VERSION ""

NS_ :

BS_:

BU_:

BO_ 2566590462 NTEES: 34 Vector__XXX
 SG_ NxTStd100HEOtptEB1Tt : 0|16@1+ (1,0) [0|64255] "kWh" Vector__XXX
 SG_ NxTrkngStrd100HrEngnOtptEnrgBn2 : 16|16@1+ (1,0) [0|64255] "kWh" Vector__XXX
 SG_ NxTrkngStrd100HrEngnOtptEnrgBn3 : 32|16@1+ (1,0) [0|64255] "kWh" Vector__XXX
 SG_ NxTrkngStrd100HrEngnOtptEnrgBn4 : 48|16@1+ (1,0) [0|64255] "kWh" Vector__XXX
 SG_ NxTrkngStrd100HrEngnOtptEnrgBn5 : 64|16@1+ (1,0) [0|64255] "kWh" Vector__XXX
 SG_ NxTrkngStrd100HrEngnOtptEnrgBn6 : 80|16@1+ (1,0) [0|64255] "kWh" Vector__XXX
 SG_ NxTrkngStrd100HrEngnOtptEnrgBn7 : 96|16@1+ (1,0) [0|64255] "kWh" Vector__XXX
 SG_ NxTrkngStrd100HrEngnOtptEnrgBn8 : 112|16@1+ (1,0) [0|64255] "kWh" Vector__XXX
 SG_ NxTrkngStrd100HrEngnOtptEnrgBn9 : 128|16@1+ (1,0) [0|64255] "kWh" Vector__XXX
 SG_ NxTStd100HEOtptEB10 : 144|16@1+ (1,0) [0|64255] "kWh" Vector__XXX
 SG_ NxTStd100HEOtptEB11 : 160|16@1+ (1,0) [0|64255] "kWh" Vector__XXX
 SG_ NxTStd100HEOtptEB12 : 176|16@1+ (1,0) [0|64255] "kWh" Vector__XXX
 SG_ NxTStd100HEOtptEB13 : 192|16@1+ (1,0) [0|64255] "kWh" Vector__XXX
 SG_ NxTStd100HEOtptEB14 : 208|16@1+ (1,0) [0|64255] "kWh" Vector__XXX
 SG_ NxTStd100HEOtptEB15NtB : 224|16@1+ (1,0) [0|64255] "kWh" Vector__XXX
 SG_ NxTStd100HEOtptEB16RB : 240|16@1+ (1,0) [0|64255] "kWh" Vector__XXX
 SG_ NxTStd100HEOtptEB17MOB : 256|16@1+ (1,0) [0|64255] "kWh" Vector__XXX

BO_ 2566590718 NTENS: 68 Vector__XXX
 SG_ NxTStd100HEOtNxMssB1Tt : 0|32@1+ (0.0005,0) [0|2105540.6075] "g" Vector__XXX
 SG_ NxTrkngStrd100HrEngnOtNxMssBn2 : 32|32@1+ (0.0005,0) [0|2105540.6075] "g" Vector__XXX
 SG_ NxTrkngStrd100HrEngnOtNxMssBn3 : 64|32@1+ (0.0005,0) [0|2105540.6075] "g" Vector__XXX
 SG_ NxTrkngStrd100HrEngnOtNxMssBn4 : 96|32@1+ (0.0005,0) [0|2105540.6075] "g" Vector__XXX
 SG_ NxTrkngStrd100HrEngnOtNxMssBn5 : 128|32@1+ (0.0005,0) [0|2105540.6075] "g" Vector__XXX
 SG_ NxTrkngStrd100HrEngnOtNxMssBn6 : 160|32@1+ (0.0005,0) [0|2105540.6075] "g" Vector__XXX
 SG_ NxTrkngStrd100HrEngnOtNxMssBn7 : 192|32@1+ (0.0005,0) [0|2105540.6075] "g" Vector__XXX
 SG_ NxTrkngStrd100HrEngnOtNxMssBn8 : 224|32@1+ (0.0005,0) [0|2105540.6075] "g" Vector__XXX
 SG_ NxTrkngStrd100HrEngnOtNxMssBn9 : 256|32@1+ (0.0005,0) [0|2105540.6075] "g" Vector__XXX
 SG_ NxTrkngStrd100HrEngnOtNxMssBn10 : 288|32@1+ (0.0005,0) [0|2105540.6075] "g" Vector__XXX
 SG_ NxTrkngStrd100HrEngnOtNxMssBn11 : 320|32@1+ (0.0005,0) [0|2105540.6075] "g" Vector__XXX
 SG_ NxTrkngStrd100HrEngnOtNxMssBn12 : 352|32@1+ (0.0005,0) [0|2105540.6075] "g" Vector__XXX
 SG_ NxTrkngStrd100HrEngnOtNxMssBn13 : 384|32@1+ (0.0005,0) [0|2105540.6075] "g" Vector__XXX
 SG_ NxTrkngStrd100HrEngnOtNxMssBn14 : 416|32@1+ (0.0005,0) [0|2105540.6075] "g" Vector__XXX
 SG_ NxTStd100HEOtNxMssB15NtB : 448|32@1+ (0.0005,0) [0|2105540.6075] "g" Vector__XXX
 SG_ NxTStd100HEOtNxMssB16RB : 480|32@1+ (0.0005,0) [0|2105540.6075] "g" Vector__XXX
 SG_ NxTStd100HEOtNxMssB17MOB : 512|32@1+ (0.0005,0) [0|2105540.6075] "g" Vector__XXX

BO_ 2566590974 NTSNS: 68 Vector__XXX
 SG_ NxTStd100HSstOtNxMssB1Tt : 0|32@1+ (0.0002,0) [0|842216.243] "g" Vector__XXX
 SG_ NxTrkngStrd100HrSstmOtNxMssBn2 : 32|32@1+ (0.0002,0) [0|842216.243] "g" Vector__XXX
 SG_ NxTrkngStrd100HrSstmOtNxMssBn3 : 64|32@1+ (0.0002,0) [0|842216.243] "g" Vector__XXX
 SG_ NxTrkngStrd100HrSstmOtNxMssBn4 : 96|32@1+ (0.0002,0) [0|842216.243] "g" Vector__XXX
 SG_ NxTrkngStrd100HrSstmOtNxMssBn5 : 128|32@1+ (0.0002,0) [0|842216.243] "g" Vector__XXX
 SG_ NxTrkngStrd100HrSstmOtNxMssBn6 : 160|32@1+ (0.0002,0) [0|842216.243] "g" Vector__XXX
 SG_ NxTrkngStrd100HrSstmOtNxMssBn7 : 192|32@1+ (0.0002,0) [0|842216.243] "g" Vector__XXX
 SG_ NxTrkngStrd100HrSstmOtNxMssBn8 : 224|32@1+ (0.0002,0) [0|842216.243] "g" Vector__XXX
 SG_ NxTrkngStrd100HrSstmOtNxMssBn9 : 256|32@1+ (0.0002,0) [0|842216.243] "g" Vector__XXX
 SG_ NxTrkngStrd100HrSstmOtNxMssBn10 : 288|32@1+ (0.0002,0) [0|842216.243] "g" Vector__XXX
 SG_ NxTrkngStrd100HrSstmOtNxMssBn11 : 320|32@1+ (0.0002,0) [0|842216.243] "g" Vector__XXX
 SG_ NxTrkngStrd100HrSstmOtNxMssBn12 : 352|32@1+ (0.0002,0) [0|842216.243] "g" Vector__XXX
 SG_ NxTrkngStrd100HrSstmOtNxMssBn13 : 384|32@1+ (0.0002,0) [0|842216.243] "g" Vector__XXX
 SG_ NxTrkngStrd100HrSstmOtNxMssBn14 : 416|32@1+ (0.0002,0) [0|842216.243] "g" Vector__XXX
 SG_ NxTStd100HSstOtNxMssB15NtB : 448|32@1+ (0.0002,0) [0|842216.243] "g" Vector__XXX
 SG_ NxTStd100HSstOtNxMssB16RB : 480|32@1+ (0.0002,0) [0|842216.243] "g" Vector__XXX
 SG_ NxTStd100HSstOtNxMssB17MOB : 512|32@1+ (0.0002,0) [0|842216.243] "g" Vector__XXX

BO_ 2566591230 NTFCA: 34 Vector__XXX
 SG_ NxTrkngAtv100HrFlCnsmptnBn1Ttl : 0|16@1+ (0.5,0) [0|32127.5] "l" Vector__XXX
 SG_ NxTrkngAtv100HrFlCnsmptnBn2 : 16|16@1+ (0.5,0) [0|32127.5] "l" Vector__XXX
 SG_ NxTrkngAtv100HrFlCnsmptnBn3 : 32|16@1+ (0.5,0) [0|32127.5] "l" Vector__XXX
 SG_ NxTrkngAtv100HrFlCnsmptnBn4 : 48|16@1+ (0.5,0) [0|32127.5] "l" Vector__XXX
 SG_ NxTrkngAtv100HrFlCnsmptnBn5 : 64|16@1+ (0.5,0) [0|32127.5] "l" Vector__XXX
 SG_ NxTrkngAtv100HrFlCnsmptnBn6 : 80|16@1+ (0.5,0) [0|32127.5] "l" Vector__XXX
 SG_ NxTrkngAtv100HrFlCnsmptnBn7 : 96|16@1+ (0.5,0) [0|32127.5] "l" Vector__XXX
 SG_ NxTrkngAtv100HrFlCnsmptnBn8 : 112|16@1+ (0.5,0) [0|32127.5] "l" Vector__XXX
 SG_ NxTrkngAtv100HrFlCnsmptnBn9 : 128|16@1+ (0.5,0) [0|32127.5] "l" Vector__XXX
 SG_ NxTrkngAtv100HrFlCnsmptnBn10 : 144|16@1+ (0.5,0) [0|32127.5] "l" Vector__XXX
 SG_ NxTrkngAtv100HrFlCnsmptnBn11 : 160|16@1+ (0.5,0) [0|32127.5] "l" Vector__XXX
 SG_ NxTrkngAtv100HrFlCnsmptnBn12 : 176|16@1+ (0.5,0) [0|32127.5] "l" Vector__XXX
 SG_ NxTrkngAtv100HrFlCnsmptnBn13 : 192|16@1+ (0.5,0) [0|32127.5] "l" Vector__XXX
 SG_ NxTrkngAtv100HrFlCnsmptnBn14 : 208|16@1+ (0.5,0) [0|32127.5] "l" Vector__XXX
 SG_ NxTAtv100HFCsptB15NtB : 224|16@1+ (0.5,0) [0|32127.5] "l" Vector__XXX
 SG_ NxTAtv100HFCsptB16RB : 240|16@1+ (0.5,0) [0|32127.5] "l" Vector__XXX
 SG_ NxTAtv100HFCsptB17MOB : 256|16@1+ (0.5,0) [0|32127.5] "l" Vector__XXX

BO_ 2566591486 NTEHA: 34 Vector__XXX
 SG_ NxTrkngAtv100HrEngnRnTmBn1Ttl : 0|16@1+ (10,0) [0|642550] "s" Vector__XXX
 SG_ NxTrkngAtv100HrEngnRnTmBn2 : 16|16@1+ (10,0) [0|642550] "s" Vector__XXX
 SG_ NxTrkngAtv100HrEngnRnTmBn3 : 32|16@1+ (10,0) [0|642550] "s" Vector__XXX
 SG_ NxTrkngAtv100HrEngnRnTmBn4 : 48|16@1+ (10,0) [0|642550] "s" Vector__XXX
 SG_ NxTrkngAtv100HrEngnRnTmBn5 : 64|16@1+ (10,0) [0|642550] "s" Vector__XXX
 SG_ NxTrkngAtv100HrEngnRnTmBn6 : 80|16@1+ (10,0) [0|642550] "s" Vector__XXX
 SG_ NxTrkngAtv100HrEngnRnTmBn7 : 96|16@1+ (10,0) [0|642550] "s" Vector__XXX
 SG_ NxTrkngAtv100HrEngnRnTmBn8 : 112|16@1+ (10,0) [0|642550] "s" Vector__XXX
 SG_ NxTrkngAtv100HrEngnRnTmBn9 : 128|16@1+ (10,0) [0|642550] "s" Vector__XXX
 SG_ NxTrkngAtv100HrEngnRnTmBn10 : 144|16@1+ (10,0) [0|642550] "s" Vector__XXX
 SG_ NxTrkngAtv100HrEngnRnTmBn11 : 160|16@1+ (10,0) [0|642550] "s" Vector__XXX
 SG_ NxTrkngAtv100HrEngnRnTmBn12 : 176|16@1+ (10,0) [0|642550] "s" Vector__XXX
 SG_ NxTrkngAtv100HrEngnRnTmBn13 : 192|16@1+ (10,0) [0|642550] "s" Vector__XXX
 SG_ NxTrkngAtv100HrEngnRnTmBn14 : 208|16@1+ (10,0) [0|642550] "s" Vector__XXX
 SG_ NxTrkngAtv100HrEngnRnTmBn15NtBn : 224|16@1+ (10,0) [0|642550] "s" Vector__XXX
 SG_ NxTAtv100HERTB16RB : 240|16@1+ (10,0) [0|642550] "s" Vector__XXX
 SG_ NxTAtv100HERTB17MOB : 256|16@1+ (10,0) [0|642550] "s" Vector__XXX

BO_ 2566591742 NTVMA: 34 Vector__XXX
 SG_ NxTrkngAtv100HrVhlDstnBn1Ttl : 0|16@1+ (0.25,0) [0|16063.75] "km" Vector__XXX
 SG_ NxTrkngAtv100HrVhlDstnBn2 : 16|16@1+ (0.25,0) [0|16063.75] "km" Vector__XXX
 SG_ NxTrkngAtv100HrVhlDstnBn3 : 32|16@1+ (0.25,0) [0|16063.75] "km" Vector__XXX
 SG_ NxTrkngAtv100HrVhlDstnBn4 : 48|16@1+ (0.25,0) [0|16063.75] "km" Vector__XXX
 SG_ NxTrkngAtv100HrVhlDstnBn5 : 64|16@1+ (0.25,0) [0|16063.75] "km" Vector__XXX
 SG_ NxTrkngAtv100HrVhlDstnBn6 : 80|16@1+ (0.25,0) [0|16063.75] "km" Vector__XXX
 SG_ NxTrkngAtv100HrVhlDstnBn7 : 96|16@1+ (0.25,0) [0|16063.75] "km" Vector__XXX
 SG_ NxTrkngAtv100HrVhlDstnBn8 : 112|16@1+ (0.25,0) [0|16063.75] "km" Vector__XXX
 SG_ NxTrkngAtv100HrVhlDstnBn9 : 128|16@1+ (0.25,0) [0|16063.75] "km" Vector__XXX
 SG_ NxTrkngAtv100HrVhlDstnBn10 : 144|16@1+ (0.25,0) [0|16063.75] "km" Vector__XXX
 SG_ NxTrkngAtv100HrVhlDstnBn11 : 160|16@1+ (0.25,0) [0|16063.75] "km" Vector__XXX
 SG_ NxTrkngAtv100HrVhlDstnBn12 : 176|16@1+ (0.25,0) [0|16063.75] "km" Vector__XXX
 SG_ NxTrkngAtv100HrVhlDstnBn13 : 192|16@1+ (0.25,0) [0|16063.75] "km" Vector__XXX
 SG_ NxTrkngAtv100HrVhlDstnBn14 : 208|16@1+ (0.25,0) [0|16063.75] "km" Vector__XXX
 SG_ NxTrkngAtv100HrVhlDstnBn15NtBn : 224|16@1+ (0.25,0) [0|16063.75] "km" Vector__XXX
 SG_ NxTrkngAtv100HrVhlDstnBn16RgnBn : 240|16@1+ (0.25,0) [0|16063.75] "km" Vector__XXX
 SG_ NxTAtv100HVDstB17MOB : 256|16@1+ (0.25,0) [0|16063.75] "km" Vector__XXX

BO_ 2566591998 NTEEA: 34 Vector__XXX
 SG_ NxTAtv100HEOtptEB1Tt : 0|16@1+ (1,0) [0|64255] "kWh" Vector__XXX
 SG_ NxTrkngAtv100HrEngnOtptEnrgBn2 : 16|16@1+ (1,0) [0|64255] "kWh" Vector__XXX
 SG_ NxTrkngAtv100HrEngnOtptEnrgBn3 : 32|16@1+ (1,0) [0|64255] "kWh" Vector__XXX
 SG_ NxTrkngAtv100HrEngnOtptEnrgBn4 : 48|16@1+ (1,0) [0|64255] "kWh" Vector__XXX
 SG_ NxTrkngAtv100HrEngnOtptEnrgBn5 : 64|16@1+ (1,0) [0|64255] "kWh" Vector__XXX
 SG_ NxTrkngAtv100HrEngnOtptEnrgBn6 : 80|16@1+ (1,0) [0|64255] "kWh" Vector__XXX
 SG_ NxTrkngAtv100HrEngnOtptEnrgBn7 : 96|16@1+ (1,0) [0|64255] "kWh" Vector__XXX
 SG_ NxTrkngAtv100HrEngnOtptEnrgBn8 : 112|16@1+ (1,0) [0|64255] "kWh" Vector__XXX
 SG_ NxTrkngAtv100HrEngnOtptEnrgBn9 : 128|16@1+ (1,0) [0|64255] "kWh" Vector__XXX
 SG_ NxTrkngAtv100HrEngnOtptEnrgBn10 : 144|16@1+ (1,0) [0|64255] "kWh" Vector__XXX
 SG_ NxTrkngAtv100HrEngnOtptEnrgBn11 : 160|16@1+ (1,0) [0|64255] "kWh" Vector__XXX
 SG_ NxTrkngAtv100HrEngnOtptEnrgBn12 : 176|16@1+ (1,0) [0|64255] "kWh" Vector__XXX
 SG_ NxTrkngAtv100HrEngnOtptEnrgBn13 : 192|16@1+ (1,0) [0|64255] "kWh" Vector__XXX
 SG_ NxTrkngAtv100HrEngnOtptEnrgBn14 : 208|16@1+ (1,0) [0|64255] "kWh" Vector__XXX
 SG_ NxTAtv100HEOtptEB15NtB : 224|16@1+ (1,0) [0|64255] "kWh" Vector__XXX
 SG_ NxTAtv100HEOtptEB16RB : 240|16@1+ (1,0) [0|64255] "kWh" Vector__XXX
 SG_ NxTAtv100HEOtptEB17MOB : 256|16@1+ (1,0) [0|64255] "kWh" Vector__XXX

BO_ 2566592254 NTENA: 68 Vector__XXX
 SG_ NxTAtv100HEOtNxMssB1Tt : 0|32@1+ (0.0005,0) [0|2105540.6075] "g" Vector__XXX
 SG_ NxTrkngAtv100HrEngnOtNxMssBn2 : 32|32@1+ (0.0005,0) [0|2105540.6075] "g" Vector__XXX
 SG_ NxTrkngAtv100HrEngnOtNxMssBn3 : 64|32@1+ (0.0005,0) [0|2105540.6075] "g" Vector__XXX
 SG_ NxTrkngAtv100HrEngnOtNxMssBn4 : 96|32@1+ (0.0005,0) [0|2105540.6075] "g" Vector__XXX
 SG_ NxTrkngAtv100HrEngnOtNxMssBn5 : 128|32@1+ (0.0005,0) [0|2105540.6075] "g" Vector__XXX
 SG_ NxTrkngAtv100HrEngnOtNxMssBn6 : 160|32@1+ (0.0005,0) [0|2105540.6075] "g" Vector__XXX
 SG_ NxTrkngAtv100HrEngnOtNxMssBn7 : 192|32@1+ (0.0005,0) [0|2105540.6075] "g" Vector__XXX
 SG_ NxTrkngAtv100HrEngnOtNxMssBn8 : 224|32@1+ (0.0005,0) [0|2105540.6075] "g" Vector__XXX
 SG_ NxTrkngAtv100HrEngnOtNxMssBn9 : 256|32@1+ (0.0005,0) [0|2105540.6075] "g" Vector__XXX
 SG_ NxTrkngAtv100HrEngnOtNxMssBn10 : 288|32@1+ (0.0005,0) [0|2105540.6075] "g" Vector__XXX
 SG_ NxTrkngAtv100HrEngnOtNxMssBn11 : 320|32@1+ (0.0005,0) [0|2105540.6075] "g" Vector__XXX
 SG_ NxTrkngAtv100HrEngnOtNxMssBn12 : 352|32@1+ (0.0005,0) [0|2105540.6075] "g" Vector__XXX
 SG_ NxTrkngAtv100HrEngnOtNxMssBn13 : 384|32@1+ (0.0005,0) [0|2105540.6075] "g" Vector__XXX
 SG_ NxTrkngAtv100HrEngnOtNxMssBn14 : 416|32@1+ (0.0005,0) [0|2105540.6075] "g" Vector__XXX
 SG_ NxTAtv100HEOtNxMssB15NtB : 448|32@1+ (0.0005,0) [0|2105540.6075] "g" Vector__XXX
 SG_ NxTAtv100HEOtNxMssB16RB : 480|32@1+ (0.0005,0) [0|2105540.6075] "g" Vector__XXX
 SG_ NxTAtv100HEOtNxMssB17MOB : 512|32@1+ (0.0005,0) [0|2105540.6075] "g" Vector__XXX

BO_ 2566592510 NTSNA: 68 Vector__XXX
 SG_ NxTAtv100HSstOtNxMssB1Tt : 0|32@1+ (0.0002,0) [0|842216.243] "g" Vector__XXX
 SG_ NxTrkngAtv100HrSstmOtNxMssBn2 : 32|32@1+ (0.0002,0) [0|842216.243] "g" Vector__XXX
 SG_ NxTrkngAtv100HrSstmOtNxMssBn3 : 64|32@1+ (0.0002,0) [0|842216.243] "g" Vector__XXX
 SG_ NxTrkngAtv100HrSstmOtNxMssBn4 : 96|32@1+ (0.0002,0) [0|842216.243] "g" Vector__XXX
 SG_ NxTrkngAtv100HrSstmOtNxMssBn5 : 128|32@1+ (0.0002,0) [0|842216.243] "g" Vector__XXX
 SG_ NxTrkngAtv100HrSstmOtNxMssBn6 : 160|32@1+ (0.0002,0) [0|842216.243] "g" Vector__XXX
 SG_ NxTrkngAtv100HrSstmOtNxMssBn7 : 192|32@1+ (0.0002,0) [0|842216.243] "g" Vector__XXX
 SG_ NxTrkngAtv100HrSstmOtNxMssBn8 : 224|32@1+ (0.0002,0) [0|842216.243] "g" Vector__XXX
 SG_ NxTrkngAtv100HrSstmOtNxMssBn9 : 256|32@1+ (0.0002,0) [0|842216.243] "g" Vector__XXX
 SG_ NxTrkngAtv100HrSstmOtNxMssBn10 : 288|32@1+ (0.0002,0) [0|842216.243] "g" Vector__XXX
 SG_ NxTrkngAtv100HrSstmOtNxMssBn11 : 320|32@1+ (0.0002,0) [0|842216.243] "g" Vector__XXX
 SG_ NxTrkngAtv100HrSstmOtNxMssBn12 : 352|32@1+ (0.0002,0) [0|842216.243] "g" Vector__XXX
 SG_ NxTrkngAtv100HrSstmOtNxMssBn13 : 384|32@1+ (0.0002,0) [0|842216.243] "g" Vector__XXX
 SG_ NxTrkngAtv100HrSstmOtNxMssBn14 : 416|32@1+ (0.0002,0) [0|842216.243] "g" Vector__XXX
 SG_ NxTAtv100HSstOtNxMssB15NtB : 448|32@1+ (0.0002,0) [0|842216.243] "g" Vector__XXX
 SG_ NxTAtv100HSstOtNxMssB16RB : 480|32@1+ (0.0002,0) [0|842216.243] "g" Vector__XXX
 SG_ NxTAtv100HSstOtNxMssB17MOB : 512|32@1+ (0.0002,0) [0|842216.243] "g" Vector__XXX

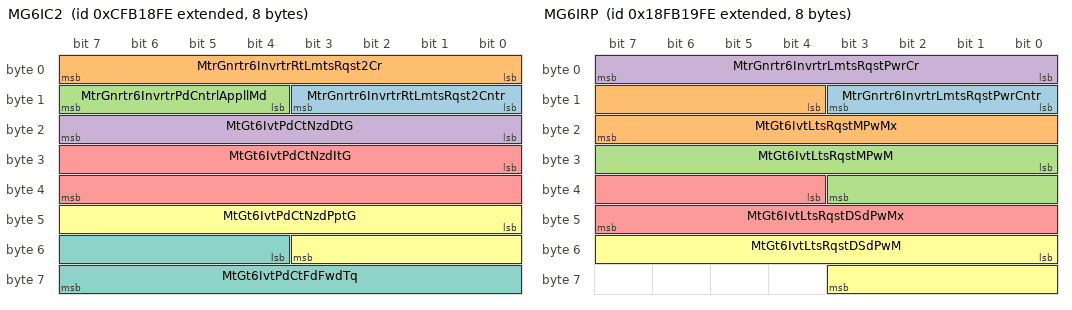
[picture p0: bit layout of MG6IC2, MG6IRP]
BO_ 2365266174 MG6IC2: 8 Vector__XXX
 SG_ MtrGnrtr6InvrtrRtLmtsRqst2Cntr : 8|4@1+ (1,0) [0|15] "" Vector__XXX
 SG_ MtrGnrtr6InvrtrRtLmtsRqst2Cr : 0|8@1+ (1,0) [0|250] "count" Vector__XXX
 SG_ MtrGnrtr6InvrtrPdCntrlAppllMd : 12|4@1+ (1,0) [0|15] "" Vector__XXX
 SG_ MtGt6IvtPdCtNzdDtG : 16|8@1+ (0.03125,0) [0|7.8125] "%/(%/s)" Vector__XXX
 SG_ MtGt6IvtPdCtNzdItG : 24|16@1+ (0.015625,0) [0|1003.984375] "%/(%/s)" Vector__XXX
 SG_ MtGt6IvtPdCtNzdPptG : 40|12@1+ (0.0625,0) [0|250.9375] "%/%" Vector__XXX
 SG_ MtGt6IvtPdCtFdFwdTq : 52|12@1+ (0.0625,-125) [-125|125.9375] "%" Vector__XXX

BO_ 2566593022 MG6IRP: 8 Vector__XXX
 SG_ MtrGnrtr6InvrtrLmtsRqstPwrCntr : 8|4@1+ (1,0) [0|15] "" Vector__XXX
 SG_ MtGt6IvtLtsRqstMPwMx : 12|12@1+ (0.0625,-125) [-125|125.9375] "%" Vector__XXX
 SG_ MtGt6IvtLtsRqstMPwM : 24|12@1+ (0.0625,-125) [-125|125.9375] "%" Vector__XXX
 SG_ MtrGnrtr6InvrtrLmtsRqstPwrCr : 0|8@1+ (1,0) [0|250] "count" Vector__XXX
 SG_ MtGt6IvtLtsRqstDSdPwMx : 36|12@1+ (0.0625,-125) [-125|125.9375] "%" Vector__XXX
 SG_ MtGt6IvtLtsRqstDSdPwM : 48|12@1+ (0.0625,-125) [-125|125.9375] "%" Vector__XXX

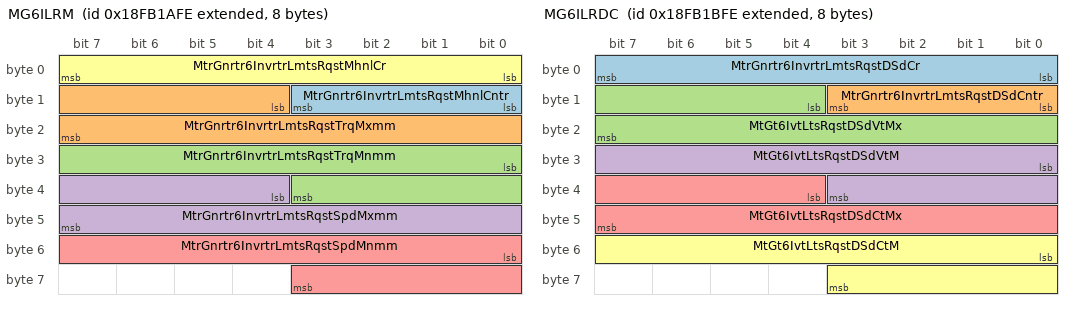
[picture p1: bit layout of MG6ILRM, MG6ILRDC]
BO_ 2566593278 MG6ILRM: 8 Vector__XXX
 SG_ MtrGnrtr6InvrtrLmtsRqstMhnlCntr : 8|4@1+ (1,0) [0|15] "" Vector__XXX
 SG_ MtrGnrtr6InvrtrLmtsRqstTrqMxmm : 12|12@1+ (0.0625,-125) [-125|125.9375] "%" Vector__XXX
 SG_ MtrGnrtr6InvrtrLmtsRqstTrqMnmm : 24|12@1+ (0.0625,-125) [-125|125.9375] "%" Vector__XXX
 SG_ MtrGnrtr6InvrtrLmtsRqstSpdMxmm : 36|12@1+ (0.0625,-125) [-125|125.9375] "%" Vector__XXX
 SG_ MtrGnrtr6InvrtrLmtsRqstSpdMnmm : 48|12@1+ (0.0625,-125) [-125|125.9375] "%" Vector__XXX
 SG_ MtrGnrtr6InvrtrLmtsRqstMhnlCr : 0|8@1+ (1,0) [0|250] "count" Vector__XXX

BO_ 2566593534 MG6ILRDC: 8 Vector__XXX
 SG_ MtrGnrtr6InvrtrLmtsRqstDSdCr : 0|8@1+ (1,0) [0|250] "count" Vector__XXX
 SG_ MtrGnrtr6InvrtrLmtsRqstDSdCntr : 8|4@1+ (1,0) [0|15] "" Vector__XXX
 SG_ MtGt6IvtLtsRqstDSdVtMx : 12|12@1+ (0.0625,-125) [-125|125.9375] "%" Vector__XXX
 SG_ MtGt6IvtLtsRqstDSdVtM : 24|12@1+ (0.0625,-125) [-125|125.9375] "%" Vector__XXX
 SG_ MtGt6IvtLtsRqstDSdCtMx : 36|12@1+ (0.0625,-125) [-125|125.9375] "%" Vector__XXX
 SG_ MtGt6IvtLtsRqstDSdCtM : 48|12@1+ (0.0625,-125) [-125|125.9375] "%" Vector__XXX

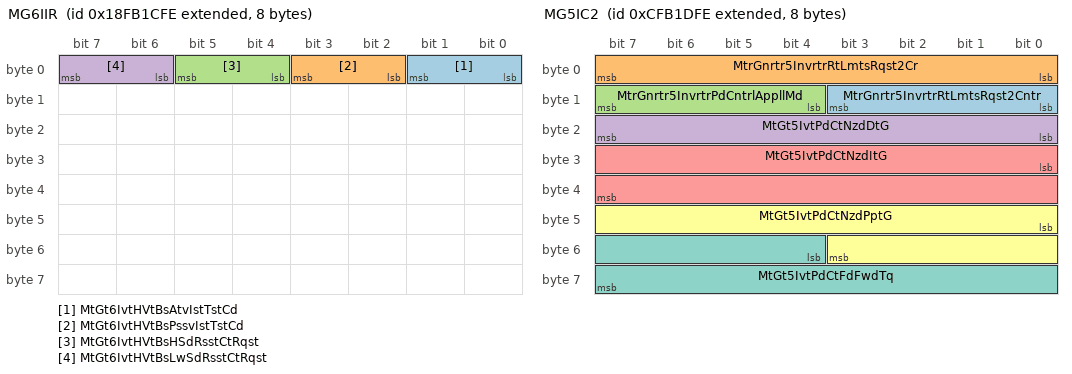
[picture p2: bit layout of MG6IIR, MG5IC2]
BO_ 2566593790 MG6IIR: 8 Vector__XXX
 SG_ MtGt6IvtHVtBsAtvIstTstCd : 0|2@1+ (1,0) [0|3] "" Vector__XXX
 SG_ MtGt6IvtHVtBsPssvIstTstCd : 2|2@1+ (1,0) [0|3] "" Vector__XXX
 SG_ MtGt6IvtHVtBsHSdRsstCtRqst : 4|2@1+ (1,0) [0|3] "" Vector__XXX
 SG_ MtGt6IvtHVtBsLwSdRsstCtRqst : 6|2@1+ (1,0) [0|3] "" Vector__XXX

BO_ 2365267454 MG5IC2: 8 Vector__XXX
 SG_ MtrGnrtr5InvrtrRtLmtsRqst2Cntr : 8|4@1+ (1,0) [0|15] "" Vector__XXX
 SG_ MtrGnrtr5InvrtrRtLmtsRqst2Cr : 0|8@1+ (1,0) [0|250] "count" Vector__XXX
 SG_ MtrGnrtr5InvrtrPdCntrlAppllMd : 12|4@1+ (1,0) [0|15] "" Vector__XXX
 SG_ MtGt5IvtPdCtNzdDtG : 16|8@1+ (0.03125,0) [0|7.8125] "%/(%/s)" Vector__XXX
 SG_ MtGt5IvtPdCtNzdItG : 24|16@1+ (0.015625,0) [0|1003.984375] "%/(%/s)" Vector__XXX
 SG_ MtGt5IvtPdCtNzdPptG : 40|12@1+ (0.0625,0) [0|250.9375] "%/%" Vector__XXX
 SG_ MtGt5IvtPdCtFdFwdTq : 52|12@1+ (0.0625,-125) [-125|125.9375] "%" Vector__XXX

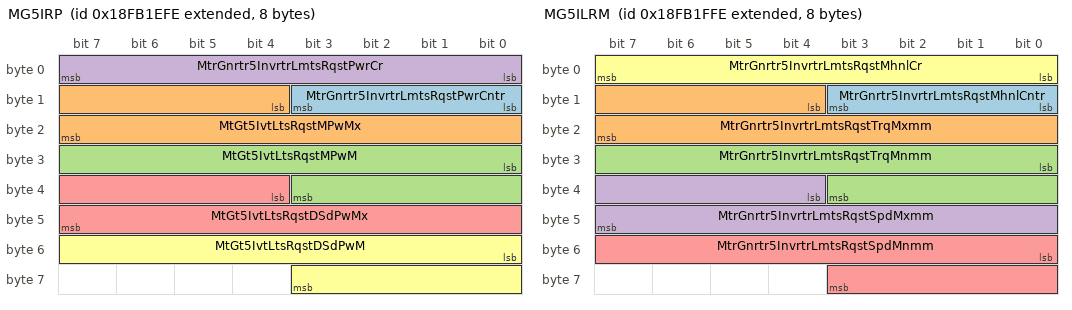
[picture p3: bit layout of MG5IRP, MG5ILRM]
BO_ 2566594302 MG5IRP: 8 Vector__XXX
 SG_ MtrGnrtr5InvrtrLmtsRqstPwrCntr : 8|4@1+ (1,0) [0|15] "" Vector__XXX
 SG_ MtGt5IvtLtsRqstMPwMx : 12|12@1+ (0.0625,-125) [-125|125.9375] "%" Vector__XXX
 SG_ MtGt5IvtLtsRqstMPwM : 24|12@1+ (0.0625,-125) [-125|125.9375] "%" Vector__XXX
 SG_ MtrGnrtr5InvrtrLmtsRqstPwrCr : 0|8@1+ (1,0) [0|250] "count" Vector__XXX
 SG_ MtGt5IvtLtsRqstDSdPwMx : 36|12@1+ (0.0625,-125) [-125|125.9375] "%" Vector__XXX
 SG_ MtGt5IvtLtsRqstDSdPwM : 48|12@1+ (0.0625,-125) [-125|125.9375] "%" Vector__XXX

BO_ 2566594558 MG5ILRM: 8 Vector__XXX
 SG_ MtrGnrtr5InvrtrLmtsRqstMhnlCntr : 8|4@1+ (1,0) [0|15] "" Vector__XXX
 SG_ MtrGnrtr5InvrtrLmtsRqstTrqMxmm : 12|12@1+ (0.0625,-125) [-125|125.9375] "%" Vector__XXX
 SG_ MtrGnrtr5InvrtrLmtsRqstTrqMnmm : 24|12@1+ (0.0625,-125) [-125|125.9375] "%" Vector__XXX
 SG_ MtrGnrtr5InvrtrLmtsRqstSpdMxmm : 36|12@1+ (0.0625,-125) [-125|125.9375] "%" Vector__XXX
 SG_ MtrGnrtr5InvrtrLmtsRqstSpdMnmm : 48|12@1+ (0.0625,-125) [-125|125.9375] "%" Vector__XXX
 SG_ MtrGnrtr5InvrtrLmtsRqstMhnlCr : 0|8@1+ (1,0) [0|250] "count" Vector__XXX

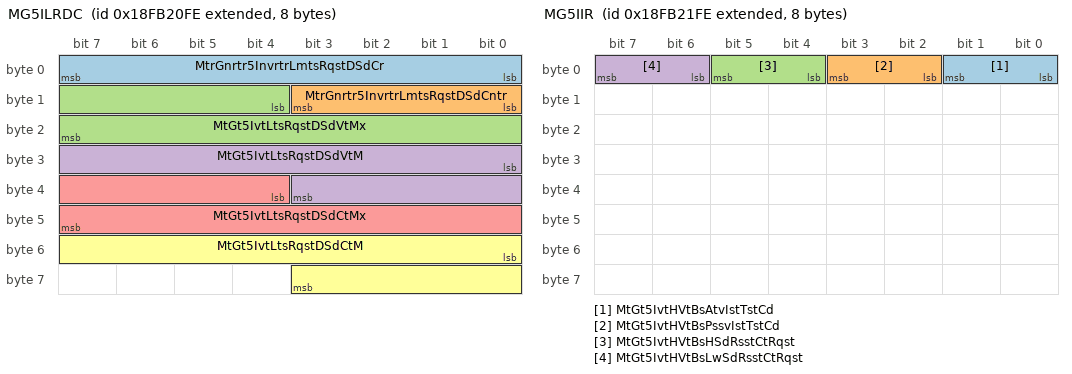
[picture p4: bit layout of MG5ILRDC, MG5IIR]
BO_ 2566594814 MG5ILRDC: 8 Vector__XXX
 SG_ MtrGnrtr5InvrtrLmtsRqstDSdCr : 0|8@1+ (1,0) [0|250] "count" Vector__XXX
 SG_ MtrGnrtr5InvrtrLmtsRqstDSdCntr : 8|4@1+ (1,0) [0|15] "" Vector__XXX
 SG_ MtGt5IvtLtsRqstDSdVtMx : 12|12@1+ (0.0625,-125) [-125|125.9375] "%" Vector__XXX
 SG_ MtGt5IvtLtsRqstDSdVtM : 24|12@1+ (0.0625,-125) [-125|125.9375] "%" Vector__XXX
 SG_ MtGt5IvtLtsRqstDSdCtMx : 36|12@1+ (0.0625,-125) [-125|125.9375] "%" Vector__XXX
 SG_ MtGt5IvtLtsRqstDSdCtM : 48|12@1+ (0.0625,-125) [-125|125.9375] "%" Vector__XXX

BO_ 2566595070 MG5IIR: 8 Vector__XXX
 SG_ MtGt5IvtHVtBsAtvIstTstCd : 0|2@1+ (1,0) [0|3] "" Vector__XXX
 SG_ MtGt5IvtHVtBsPssvIstTstCd : 2|2@1+ (1,0) [0|3] "" Vector__XXX
 SG_ MtGt5IvtHVtBsHSdRsstCtRqst : 4|2@1+ (1,0) [0|3] "" Vector__XXX
 SG_ MtGt5IvtHVtBsLwSdRsstCtRqst : 6|2@1+ (1,0) [0|3] "" Vector__XXX

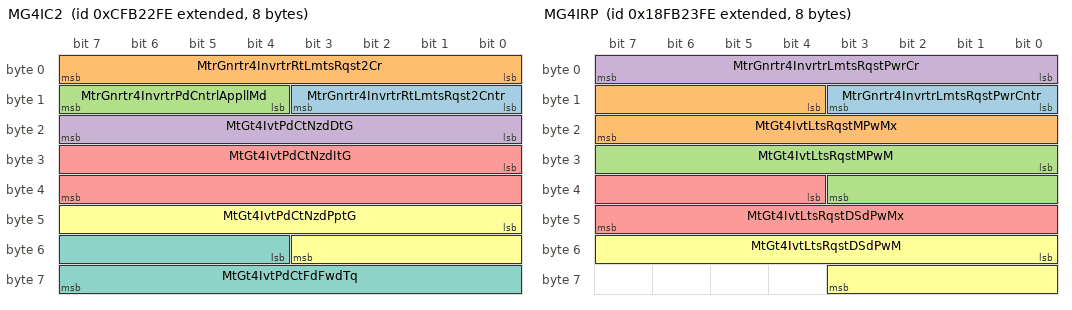
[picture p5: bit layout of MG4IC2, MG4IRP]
BO_ 2365268734 MG4IC2: 8 Vector__XXX
 SG_ MtrGnrtr4InvrtrRtLmtsRqst2Cntr : 8|4@1+ (1,0) [0|15] "" Vector__XXX
 SG_ MtrGnrtr4InvrtrRtLmtsRqst2Cr : 0|8@1+ (1,0) [0|250] "count" Vector__XXX
 SG_ MtrGnrtr4InvrtrPdCntrlAppllMd : 12|4@1+ (1,0) [0|15] "" Vector__XXX
 SG_ MtGt4IvtPdCtNzdDtG : 16|8@1+ (0.03125,0) [0|7.8125] "%/(%/s)" Vector__XXX
 SG_ MtGt4IvtPdCtNzdItG : 24|16@1+ (0.015625,0) [0|1003.984375] "%/(%/s)" Vector__XXX
 SG_ MtGt4IvtPdCtNzdPptG : 40|12@1+ (0.0625,0) [0|250.9375] "%/%" Vector__XXX
 SG_ MtGt4IvtPdCtFdFwdTq : 52|12@1+ (0.0625,-125) [-125|125.9375] "%" Vector__XXX

BO_ 2566595582 MG4IRP: 8 Vector__XXX
 SG_ MtrGnrtr4InvrtrLmtsRqstPwrCntr : 8|4@1+ (1,0) [0|15] "" Vector__XXX
 SG_ MtGt4IvtLtsRqstMPwMx : 12|12@1+ (0.0625,-125) [-125|125.9375] "%" Vector__XXX
 SG_ MtGt4IvtLtsRqstMPwM : 24|12@1+ (0.0625,-125) [-125|125.9375] "%" Vector__XXX
 SG_ MtrGnrtr4InvrtrLmtsRqstPwrCr : 0|8@1+ (1,0) [0|250] "count" Vector__XXX
 SG_ MtGt4IvtLtsRqstDSdPwMx : 36|12@1+ (0.0625,-125) [-125|125.9375] "%" Vector__XXX
 SG_ MtGt4IvtLtsRqstDSdPwM : 48|12@1+ (0.0625,-125) [-125|125.9375] "%" Vector__XXX

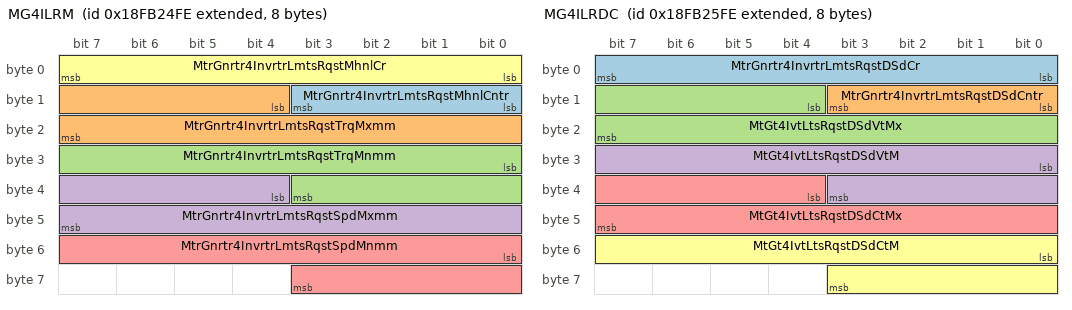
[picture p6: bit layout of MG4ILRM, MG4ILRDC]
BO_ 2566595838 MG4ILRM: 8 Vector__XXX
 SG_ MtrGnrtr4InvrtrLmtsRqstMhnlCntr : 8|4@1+ (1,0) [0|15] "" Vector__XXX
 SG_ MtrGnrtr4InvrtrLmtsRqstTrqMxmm : 12|12@1+ (0.0625,-125) [-125|125.9375] "%" Vector__XXX
 SG_ MtrGnrtr4InvrtrLmtsRqstTrqMnmm : 24|12@1+ (0.0625,-125) [-125|125.9375] "%" Vector__XXX
 SG_ MtrGnrtr4InvrtrLmtsRqstSpdMxmm : 36|12@1+ (0.0625,-125) [-125|125.9375] "%" Vector__XXX
 SG_ MtrGnrtr4InvrtrLmtsRqstSpdMnmm : 48|12@1+ (0.0625,-125) [-125|125.9375] "%" Vector__XXX
 SG_ MtrGnrtr4InvrtrLmtsRqstMhnlCr : 0|8@1+ (1,0) [0|250] "count" Vector__XXX

BO_ 2566596094 MG4ILRDC: 8 Vector__XXX
 SG_ MtrGnrtr4InvrtrLmtsRqstDSdCr : 0|8@1+ (1,0) [0|250] "count" Vector__XXX
 SG_ MtrGnrtr4InvrtrLmtsRqstDSdCntr : 8|4@1+ (1,0) [0|15] "" Vector__XXX
 SG_ MtGt4IvtLtsRqstDSdVtMx : 12|12@1+ (0.0625,-125) [-125|125.9375] "%" Vector__XXX
 SG_ MtGt4IvtLtsRqstDSdVtM : 24|12@1+ (0.0625,-125) [-125|125.9375] "%" Vector__XXX
 SG_ MtGt4IvtLtsRqstDSdCtMx : 36|12@1+ (0.0625,-125) [-125|125.9375] "%" Vector__XXX
 SG_ MtGt4IvtLtsRqstDSdCtM : 48|12@1+ (0.0625,-125) [-125|125.9375] "%" Vector__XXX

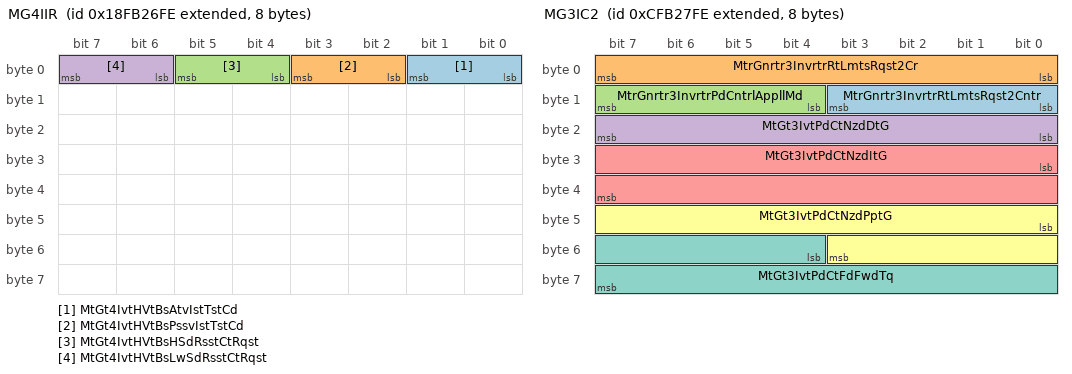
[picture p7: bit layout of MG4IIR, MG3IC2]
BO_ 2566596350 MG4IIR: 8 Vector__XXX
 SG_ MtGt4IvtHVtBsAtvIstTstCd : 0|2@1+ (1,0) [0|3] "" Vector__XXX
 SG_ MtGt4IvtHVtBsPssvIstTstCd : 2|2@1+ (1,0) [0|3] "" Vector__XXX
 SG_ MtGt4IvtHVtBsHSdRsstCtRqst : 4|2@1+ (1,0) [0|3] "" Vector__XXX
 SG_ MtGt4IvtHVtBsLwSdRsstCtRqst : 6|2@1+ (1,0) [0|3] "" Vector__XXX

BO_ 2365270014 MG3IC2: 8 Vector__XXX
 SG_ MtrGnrtr3InvrtrRtLmtsRqst2Cntr : 8|4@1+ (1,0) [0|15] "" Vector__XXX
 SG_ MtrGnrtr3InvrtrRtLmtsRqst2Cr : 0|8@1+ (1,0) [0|250] "count" Vector__XXX
 SG_ MtrGnrtr3InvrtrPdCntrlAppllMd : 12|4@1+ (1,0) [0|15] "" Vector__XXX
 SG_ MtGt3IvtPdCtNzdDtG : 16|8@1+ (0.03125,0) [0|7.8125] "%/(%/s)" Vector__XXX
 SG_ MtGt3IvtPdCtNzdItG : 24|16@1+ (0.015625,0) [0|1003.984375] "%/(%/s)" Vector__XXX
 SG_ MtGt3IvtPdCtNzdPptG : 40|12@1+ (0.0625,0) [0|250.9375] "%/%" Vector__XXX
 SG_ MtGt3IvtPdCtFdFwdTq : 52|12@1+ (0.0625,-125) [-125|125.9375] "%" Vector__XXX

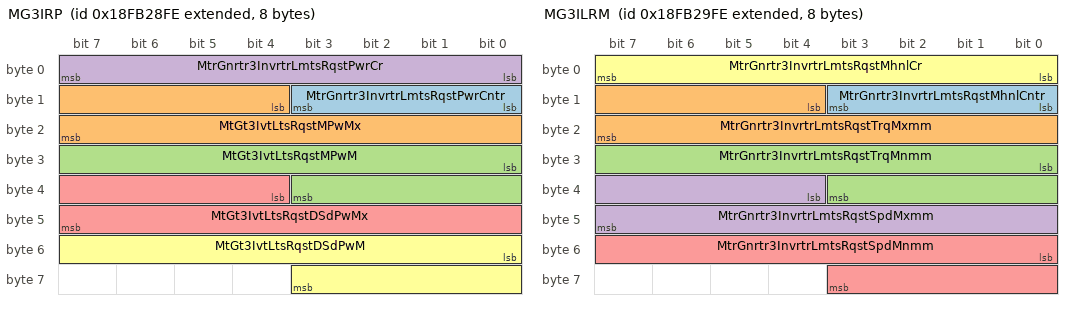
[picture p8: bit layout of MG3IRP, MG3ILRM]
BO_ 2566596862 MG3IRP: 8 Vector__XXX
 SG_ MtrGnrtr3InvrtrLmtsRqstPwrCntr : 8|4@1+ (1,0) [0|15] "" Vector__XXX
 SG_ MtGt3IvtLtsRqstMPwMx : 12|12@1+ (0.0625,-125) [-125|125.9375] "%" Vector__XXX
 SG_ MtGt3IvtLtsRqstMPwM : 24|12@1+ (0.0625,-125) [-125|125.9375] "%" Vector__XXX
 SG_ MtrGnrtr3InvrtrLmtsRqstPwrCr : 0|8@1+ (1,0) [0|250] "count" Vector__XXX
 SG_ MtGt3IvtLtsRqstDSdPwMx : 36|12@1+ (0.0625,-125) [-125|125.9375] "%" Vector__XXX
 SG_ MtGt3IvtLtsRqstDSdPwM : 48|12@1+ (0.0625,-125) [-125|125.9375] "%" Vector__XXX

BO_ 2566597118 MG3ILRM: 8 Vector__XXX
 SG_ MtrGnrtr3InvrtrLmtsRqstMhnlCntr : 8|4@1+ (1,0) [0|15] "" Vector__XXX
 SG_ MtrGnrtr3InvrtrLmtsRqstTrqMxmm : 12|12@1+ (0.0625,-125) [-125|125.9375] "%" Vector__XXX
 SG_ MtrGnrtr3InvrtrLmtsRqstTrqMnmm : 24|12@1+ (0.0625,-125) [-125|125.9375] "%" Vector__XXX
 SG_ MtrGnrtr3InvrtrLmtsRqstSpdMxmm : 36|12@1+ (0.0625,-125) [-125|125.9375] "%" Vector__XXX
 SG_ MtrGnrtr3InvrtrLmtsRqstSpdMnmm : 48|12@1+ (0.0625,-125) [-125|125.9375] "%" Vector__XXX
 SG_ MtrGnrtr3InvrtrLmtsRqstMhnlCr : 0|8@1+ (1,0) [0|250] "count" Vector__XXX

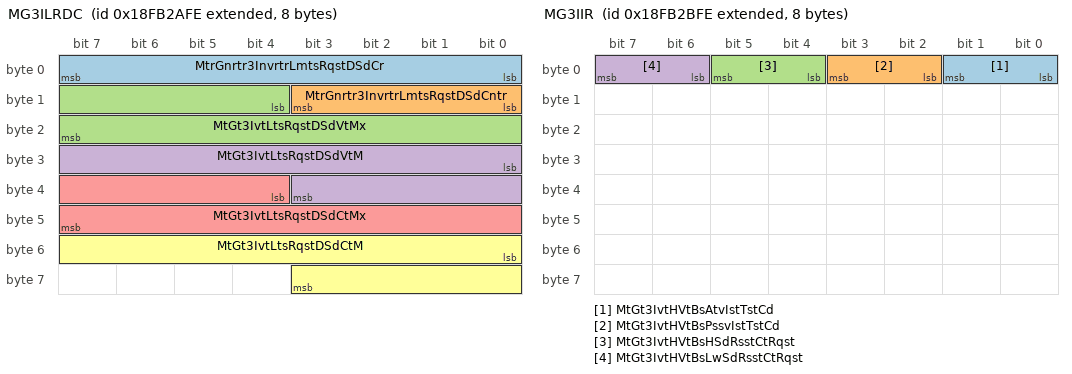
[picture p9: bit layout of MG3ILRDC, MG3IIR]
BO_ 2566597374 MG3ILRDC: 8 Vector__XXX
 SG_ MtrGnrtr3InvrtrLmtsRqstDSdCr : 0|8@1+ (1,0) [0|250] "count" Vector__XXX
 SG_ MtrGnrtr3InvrtrLmtsRqstDSdCntr : 8|4@1+ (1,0) [0|15] "" Vector__XXX
 SG_ MtGt3IvtLtsRqstDSdVtMx : 12|12@1+ (0.0625,-125) [-125|125.9375] "%" Vector__XXX
 SG_ MtGt3IvtLtsRqstDSdVtM : 24|12@1+ (0.0625,-125) [-125|125.9375] "%" Vector__XXX
 SG_ MtGt3IvtLtsRqstDSdCtMx : 36|12@1+ (0.0625,-125) [-125|125.9375] "%" Vector__XXX
 SG_ MtGt3IvtLtsRqstDSdCtM : 48|12@1+ (0.0625,-125) [-125|125.9375] "%" Vector__XXX

BO_ 2566597630 MG3IIR: 8 Vector__XXX
 SG_ MtGt3IvtHVtBsAtvIstTstCd : 0|2@1+ (1,0) [0|3] "" Vector__XXX
 SG_ MtGt3IvtHVtBsPssvIstTstCd : 2|2@1+ (1,0) [0|3] "" Vector__XXX
 SG_ MtGt3IvtHVtBsHSdRsstCtRqst : 4|2@1+ (1,0) [0|3] "" Vector__XXX
 SG_ MtGt3IvtHVtBsLwSdRsstCtRqst : 6|2@1+ (1,0) [0|3] "" Vector__XXX

BO_ 2566598142 TCI82: 8 Vector__XXX
 SG_ EngineTurbocharger5Speed : 0|16@1+ (4,0) [0|257020] "rpm" Vector__XXX
 SG_ EngineTurbocharger6Speed : 16|16@1+ (4,0) [0|257020] "rpm" Vector__XXX
 SG_ EngnTrhrgr5CmprssrIntkPrssr : 32|16@1+ (0.0078125,-250) [-250|251.9921875] "kPa" Vector__XXX
 SG_ EngnTrhrgr6CmprssrIntkPrssr : 48|16@1+ (0.0078125,-250) [-250|251.9921875] "kPa" Vector__XXX

BO_ 2566598398 WINCH2: 8 Vector__XXX
 SG_ WinchLifetimeRevolutionCounter : 0|32@1+ (1,0) [0|4211081215] "count" Vector__XXX

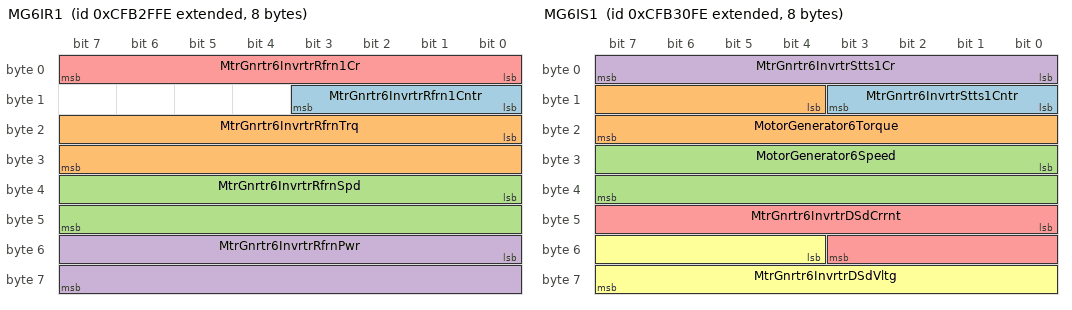
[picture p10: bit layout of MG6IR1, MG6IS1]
BO_ 2365272062 MG6IR1: 8 Vector__XXX
 SG_ MtrGnrtr6InvrtrRfrn1Cntr : 8|4@1+ (1,0) [0|15] "" Vector__XXX
 SG_ MtrGnrtr6InvrtrRfrnTrq : 16|16@1+ (0.5,0) [0|32127.5] "Nm" Vector__XXX
 SG_ MtrGnrtr6InvrtrRfrnSpd : 32|16@1+ (4,0) [0|257020] "rpm" Vector__XXX
 SG_ MtrGnrtr6InvrtrRfrnPwr : 48|16@1+ (0.0625,0) [0|4015.9375] "kW" Vector__XXX
 SG_ MtrGnrtr6InvrtrRfrn1Cr : 0|8@1+ (1,0) [0|250] "count" Vector__XXX

BO_ 2365272318 MG6IS1: 8 Vector__XXX
 SG_ MtrGnrtr6InvrtrStts1Cntr : 8|4@1+ (1,0) [0|15] "" Vector__XXX
 SG_ MotorGenerator6Torque : 12|12@1+ (0.0625,-125) [-125|125.9375] "%" Vector__XXX
 SG_ MotorGenerator6Speed : 24|16@1+ (0.00390625,-125) [-125|125.99609375] "%" Vector__XXX
 SG_ MtrGnrtr6InvrtrStts1Cr : 0|8@1+ (1,0) [0|250] "count" Vector__XXX
 SG_ MtrGnrtr6InvrtrDSdCrrnt : 40|12@1+ (0.0625,-125) [-125|125.9375] "%" Vector__XXX
 SG_ MtrGnrtr6InvrtrDSdVltg : 52|12@1+ (0.0625,-125) [-125|125.9375] "%" Vector__XXX

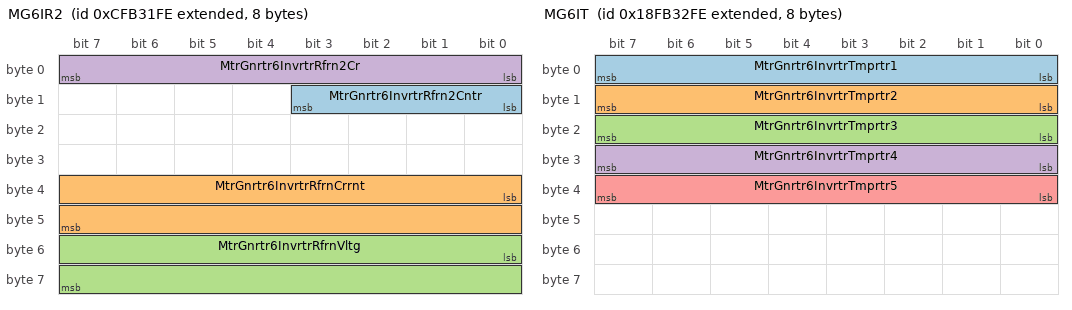
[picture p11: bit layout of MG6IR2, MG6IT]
BO_ 2365272574 MG6IR2: 8 Vector__XXX
 SG_ MtrGnrtr6InvrtrRfrn2Cntr : 8|4@1+ (1,0) [0|15] "" Vector__XXX
 SG_ MtrGnrtr6InvrtrRfrnCrrnt : 32|16@1+ (0.125,0) [0|8031.875] "A" Vector__XXX
 SG_ MtrGnrtr6InvrtrRfrnVltg : 48|16@1+ (0.125,0) [0|8031.875] "V" Vector__XXX
 SG_ MtrGnrtr6InvrtrRfrn2Cr : 0|8@1+ (1,0) [0|250] "count" Vector__XXX

BO_ 2566599422 MG6IT: 8 Vector__XXX
 SG_ MtrGnrtr6InvrtrTmprtr1 : 0|8@1+ (1,-40) [-40|210] "degC" Vector__XXX
 SG_ MtrGnrtr6InvrtrTmprtr2 : 8|8@1+ (1,-40) [-40|210] "degC" Vector__XXX
 SG_ MtrGnrtr6InvrtrTmprtr3 : 16|8@1+ (1,-40) [-40|210] "degC" Vector__XXX
 SG_ MtrGnrtr6InvrtrTmprtr4 : 24|8@1+ (1,-40) [-40|210] "degC" Vector__XXX
 SG_ MtrGnrtr6InvrtrTmprtr5 : 32|8@1+ (1,-40) [-40|210] "degC" Vector__XXX

BO_ 2566599678 MG6IMT: 8 Vector__XXX
 SG_ MotorGenerator6Temperature1 : 0|8@1+ (1,-40) [-40|210] "degC" Vector__XXX
 SG_ MotorGenerator6Temperature2 : 8|8@1+ (1,-40) [-40|210] "degC" Vector__XXX
 SG_ MotorGenerator6Temperature3 : 16|8@1+ (1,-40) [-40|210] "degC" Vector__XXX
 SG_ MotorGenerator6Temperature4 : 24|8@1+ (1,-40) [-40|210] "degC" Vector__XXX

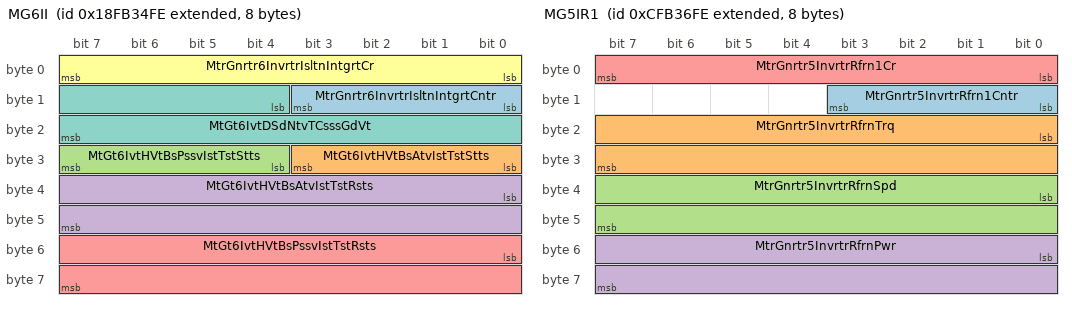
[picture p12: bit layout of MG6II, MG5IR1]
BO_ 2566599934 MG6II: 8 Vector__XXX
 SG_ MtrGnrtr6InvrtrIsltnIntgrtCntr : 8|4@1+ (1,0) [0|15] "" Vector__XXX
 SG_ MtGt6IvtHVtBsAtvIstTstStts : 24|4@1+ (1,0) [0|15] "" Vector__XXX
 SG_ MtGt6IvtHVtBsPssvIstTstStts : 28|4@1+ (1,0) [0|15] "" Vector__XXX
 SG_ MtGt6IvtHVtBsAtvIstTstRsts : 32|16@1+ (0.1,0) [0|6425.5] "OhmPerV" Vector__XXX
 SG_ MtGt6IvtHVtBsPssvIstTstRsts : 48|16@1+ (0.1,0) [0|6425.5] "OhmPerV" Vector__XXX
 SG_ MtrGnrtr6InvrtrIsltnIntgrtCr : 0|8@1+ (1,0) [0|250] "count" Vector__XXX
 SG_ MtGt6IvtDSdNtvTCsssGdVt : 12|12@1+ (0.0625,-125) [-125|125.9375] "%" Vector__XXX

BO_ 2566600190 MG6IAPL: 8 Vector__XXX
 SG_ MtGt6IvtPwLtdDTUddRs : 0|2@1+ (1,0) [0|3] "" Vector__XXX
 SG_ MtGt6IvtPwLtdDTMPwMx : 10|2@1+ (1,0) [0|3] "" Vector__XXX
 SG_ MtGt6IvtPwLtdDTMPwM : 12|2@1+ (1,0) [0|3] "" Vector__XXX
 SG_ MtrGnrtr6InvrtrPwrLmtdDTTrqMxmm : 18|2@1+ (1,0) [0|3] "" Vector__XXX
 SG_ MtrGnrtr6InvrtrPwrLmtdDTTrqMnmm : 20|2@1+ (1,0) [0|3] "" Vector__XXX
 SG_ MtrGnrtr6InvrtrPwrLmtdDTSpdMxmm : 22|2@1+ (1,0) [0|3] "" Vector__XXX
 SG_ MtrGnrtr6InvrtrPwrLmtdDTSpdMnmm : 24|2@1+ (1,0) [0|3] "" Vector__XXX
 SG_ MtGt6IvtPwLtdDTIvtTpt : 28|2@1+ (1,0) [0|3] "" Vector__XXX
 SG_ MtGt6IvtPwLtdDTMtTpt : 30|2@1+ (1,0) [0|3] "" Vector__XXX
 SG_ MtGt6IvtPwLtdDTFtCdt : 32|2@1+ (1,0) [0|3] "" Vector__XXX
 SG_ MtGt6IvtPwLtdDTAtvTqRtLt : 34|2@1+ (1,0) [0|3] "" Vector__XXX
 SG_ MtGt6IvtPwLtdDTAtvSpdRtLt : 36|2@1+ (1,0) [0|3] "" Vector__XXX
 SG_ MtGt6IvtTqLtdDTMCtsts : 38|2@1+ (1,0) [0|3] "" Vector__XXX
 SG_ MtGt6IvtPwLtdDTDSdCtMx : 2|2@1+ (1,0) [0|3] "" Vector__XXX
 SG_ MtGt6IvtPwLtdDTDSdCtM : 4|2@1+ (1,0) [0|3] "" Vector__XXX
 SG_ MtGt6IvtPwLtdDTDSdVtMx : 6|2@1+ (1,0) [0|3] "" Vector__XXX
 SG_ MtGt6IvtPwLtdDTDSdVtM : 8|2@1+ (1,0) [0|3] "" Vector__XXX
 SG_ MtGt6IvtPwLtdDTDSdPwMx : 14|2@1+ (1,0) [0|3] "" Vector__XXX
 SG_ MtGt6IvtPwLtdDTDSdPwM : 16|2@1+ (1,0) [0|3] "" Vector__XXX

BO_ 2365273854 MG5IR1: 8 Vector__XXX
 SG_ MtrGnrtr5InvrtrRfrn1Cntr : 8|4@1+ (1,0) [0|15] "" Vector__XXX
 SG_ MtrGnrtr5InvrtrRfrnTrq : 16|16@1+ (0.5,0) [0|32127.5] "Nm" Vector__XXX
 SG_ MtrGnrtr5InvrtrRfrnSpd : 32|16@1+ (4,0) [0|257020] "rpm" Vector__XXX
 SG_ MtrGnrtr5InvrtrRfrnPwr : 48|16@1+ (0.0625,0) [0|4015.9375] "kW" Vector__XXX
 SG_ MtrGnrtr5InvrtrRfrn1Cr : 0|8@1+ (1,0) [0|250] "count" Vector__XXX

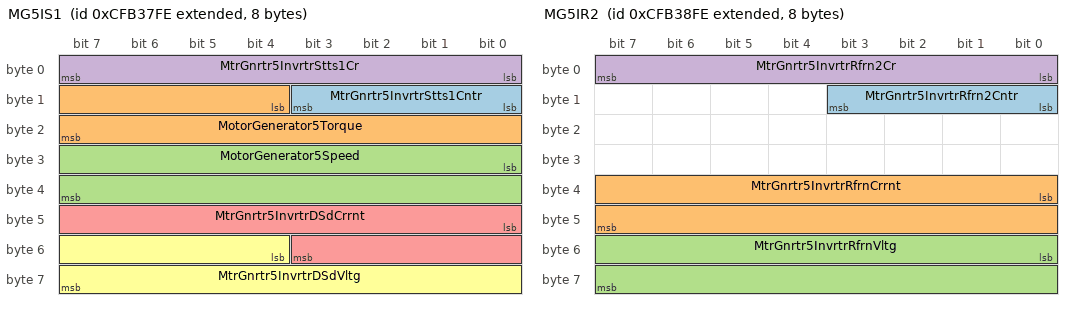
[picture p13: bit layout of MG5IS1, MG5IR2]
BO_ 2365274110 MG5IS1: 8 Vector__XXX
 SG_ MtrGnrtr5InvrtrStts1Cntr : 8|4@1+ (1,0) [0|15] "" Vector__XXX
 SG_ MotorGenerator5Torque : 12|12@1+ (0.0625,-125) [-125|125.9375] "%" Vector__XXX
 SG_ MotorGenerator5Speed : 24|16@1+ (0.00390625,-125) [-125|125.99609375] "%" Vector__XXX
 SG_ MtrGnrtr5InvrtrStts1Cr : 0|8@1+ (1,0) [0|250] "count" Vector__XXX
 SG_ MtrGnrtr5InvrtrDSdCrrnt : 40|12@1+ (0.0625,-125) [-125|125.9375] "%" Vector__XXX
 SG_ MtrGnrtr5InvrtrDSdVltg : 52|12@1+ (0.0625,-125) [-125|125.9375] "%" Vector__XXX

BO_ 2365274366 MG5IR2: 8 Vector__XXX
 SG_ MtrGnrtr5InvrtrRfrn2Cntr : 8|4@1+ (1,0) [0|15] "" Vector__XXX
 SG_ MtrGnrtr5InvrtrRfrnCrrnt : 32|16@1+ (0.125,0) [0|8031.875] "A" Vector__XXX
 SG_ MtrGnrtr5InvrtrRfrnVltg : 48|16@1+ (0.125,0) [0|8031.875] "V" Vector__XXX
 SG_ MtrGnrtr5InvrtrRfrn2Cr : 0|8@1+ (1,0) [0|250] "count" Vector__XXX

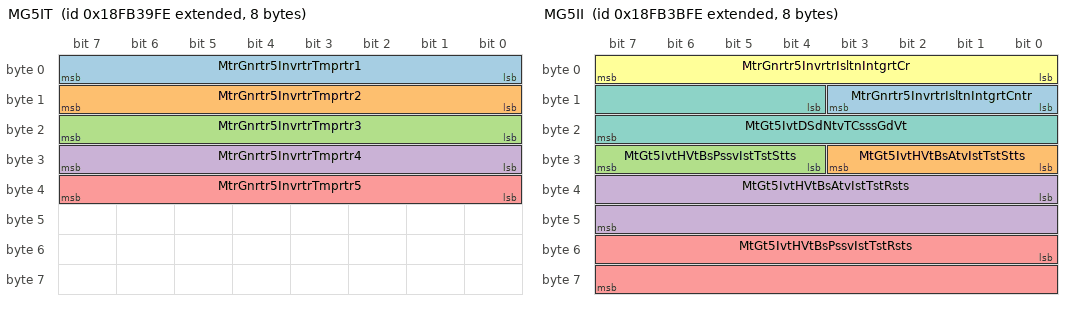
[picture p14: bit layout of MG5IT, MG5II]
BO_ 2566601214 MG5IT: 8 Vector__XXX
 SG_ MtrGnrtr5InvrtrTmprtr1 : 0|8@1+ (1,-40) [-40|210] "degC" Vector__XXX
 SG_ MtrGnrtr5InvrtrTmprtr2 : 8|8@1+ (1,-40) [-40|210] "degC" Vector__XXX
 SG_ MtrGnrtr5InvrtrTmprtr3 : 16|8@1+ (1,-40) [-40|210] "degC" Vector__XXX
 SG_ MtrGnrtr5InvrtrTmprtr4 : 24|8@1+ (1,-40) [-40|210] "degC" Vector__XXX
 SG_ MtrGnrtr5InvrtrTmprtr5 : 32|8@1+ (1,-40) [-40|210] "degC" Vector__XXX

BO_ 2566601470 MG5IMT: 8 Vector__XXX
 SG_ MotorGenerator5Temperature1 : 0|8@1+ (1,-40) [-40|210] "degC" Vector__XXX
 SG_ MotorGenerator5Temperature2 : 8|8@1+ (1,-40) [-40|210] "degC" Vector__XXX
 SG_ MotorGenerator5Temperature3 : 16|8@1+ (1,-40) [-40|210] "degC" Vector__XXX
 SG_ MotorGenerator5Temperature4 : 24|8@1+ (1,-40) [-40|210] "degC" Vector__XXX

BO_ 2566601726 MG5II: 8 Vector__XXX
 SG_ MtrGnrtr5InvrtrIsltnIntgrtCntr : 8|4@1+ (1,0) [0|15] "" Vector__XXX
 SG_ MtGt5IvtHVtBsAtvIstTstStts : 24|4@1+ (1,0) [0|15] "" Vector__XXX
 SG_ MtGt5IvtHVtBsPssvIstTstStts : 28|4@1+ (1,0) [0|15] "" Vector__XXX
 SG_ MtGt5IvtHVtBsAtvIstTstRsts : 32|16@1+ (0.1,0) [0|6425.5] "OhmPerV" Vector__XXX
 SG_ MtGt5IvtHVtBsPssvIstTstRsts : 48|16@1+ (0.1,0) [0|6425.5] "OhmPerV" Vector__XXX
 SG_ MtrGnrtr5InvrtrIsltnIntgrtCr : 0|8@1+ (1,0) [0|250] "count" Vector__XXX
 SG_ MtGt5IvtDSdNtvTCsssGdVt : 12|12@1+ (0.0625,-125) [-125|125.9375] "%" Vector__XXX

BO_ 2566601982 MG5IAPL: 8 Vector__XXX
 SG_ MtGt5IvtPwLtdDTUddRs : 0|2@1+ (1,0) [0|3] "" Vector__XXX
 SG_ MtGt5IvtPwLtdDTMPwMx : 10|2@1+ (1,0) [0|3] "" Vector__XXX
 SG_ MtGt5IvtPwLtdDTMPwM : 12|2@1+ (1,0) [0|3] "" Vector__XXX
 SG_ MtrGnrtr5InvrtrPwrLmtdDTTrqMxmm : 18|2@1+ (1,0) [0|3] "" Vector__XXX
 SG_ MtrGnrtr5InvrtrPwrLmtdDTTrqMnmm : 20|2@1+ (1,0) [0|3] "" Vector__XXX
 SG_ MtrGnrtr5InvrtrPwrLmtdDTSpdMxmm : 22|2@1+ (1,0) [0|3] "" Vector__XXX
 SG_ MtrGnrtr5InvrtrPwrLmtdDTSpdMnmm : 24|2@1+ (1,0) [0|3] "" Vector__XXX
 SG_ MtGt5IvtPwLtdDTIvtTpt : 28|2@1+ (1,0) [0|3] "" Vector__XXX
 SG_ MtGt5IvtPwLtdDTMtTpt : 30|2@1+ (1,0) [0|3] "" Vector__XXX
 SG_ MtGt5IvtPwLtdDTFtCdt : 32|2@1+ (1,0) [0|3] "" Vector__XXX
 SG_ MtGt5IvtPwLtdDTAtvTqRtLt : 34|2@1+ (1,0) [0|3] "" Vector__XXX
 SG_ MtGt5IvtPwLtdDTAtvSpdRtLt : 36|2@1+ (1,0) [0|3] "" Vector__XXX
 SG_ MtGt5IvtTqLtdDTMCtsts : 38|2@1+ (1,0) [0|3] "" Vector__XXX
 SG_ MtGt5IvtPwLtdDTDSdCtMx : 2|2@1+ (1,0) [0|3] "" Vector__XXX
 SG_ MtGt5IvtPwLtdDTDSdCtM : 4|2@1+ (1,0) [0|3] "" Vector__XXX
 SG_ MtGt5IvtPwLtdDTDSdVtMx : 6|2@1+ (1,0) [0|3] "" Vector__XXX
 SG_ MtGt5IvtPwLtdDTDSdVtM : 8|2@1+ (1,0) [0|3] "" Vector__XXX
 SG_ MtGt5IvtPwLtdDTDSdPwMx : 14|2@1+ (1,0) [0|3] "" Vector__XXX
 SG_ MtGt5IvtPwLtdDTDSdPwM : 16|2@1+ (1,0) [0|3] "" Vector__XXX

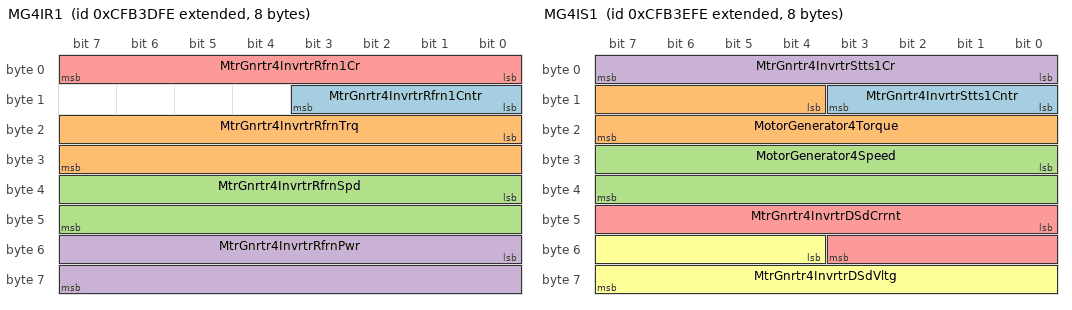
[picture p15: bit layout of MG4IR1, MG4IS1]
BO_ 2365275646 MG4IR1: 8 Vector__XXX
 SG_ MtrGnrtr4InvrtrRfrn1Cntr : 8|4@1+ (1,0) [0|15] "" Vector__XXX
 SG_ MtrGnrtr4InvrtrRfrnTrq : 16|16@1+ (0.5,0) [0|32127.5] "Nm" Vector__XXX
 SG_ MtrGnrtr4InvrtrRfrnSpd : 32|16@1+ (4,0) [0|257020] "rpm" Vector__XXX
 SG_ MtrGnrtr4InvrtrRfrnPwr : 48|16@1+ (0.0625,0) [0|4015.9375] "kW" Vector__XXX
 SG_ MtrGnrtr4InvrtrRfrn1Cr : 0|8@1+ (1,0) [0|250] "count" Vector__XXX

BO_ 2365275902 MG4IS1: 8 Vector__XXX
 SG_ MtrGnrtr4InvrtrStts1Cntr : 8|4@1+ (1,0) [0|15] "" Vector__XXX
 SG_ MotorGenerator4Torque : 12|12@1+ (0.0625,-125) [-125|125.9375] "%" Vector__XXX
 SG_ MotorGenerator4Speed : 24|16@1+ (0.00390625,-125) [-125|125.99609375] "%" Vector__XXX
 SG_ MtrGnrtr4InvrtrStts1Cr : 0|8@1+ (1,0) [0|250] "count" Vector__XXX
 SG_ MtrGnrtr4InvrtrDSdCrrnt : 40|12@1+ (0.0625,-125) [-125|125.9375] "%" Vector__XXX
 SG_ MtrGnrtr4InvrtrDSdVltg : 52|12@1+ (0.0625,-125) [-125|125.9375] "%" Vector__XXX

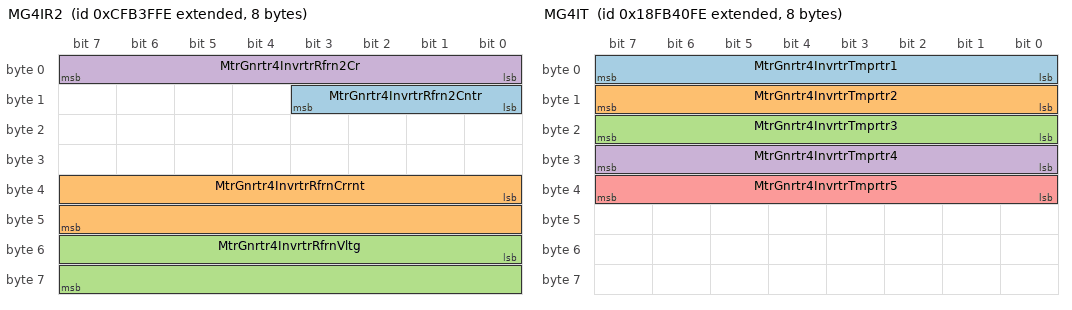
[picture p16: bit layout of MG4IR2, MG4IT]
BO_ 2365276158 MG4IR2: 8 Vector__XXX
 SG_ MtrGnrtr4InvrtrRfrn2Cntr : 8|4@1+ (1,0) [0|15] "" Vector__XXX
 SG_ MtrGnrtr4InvrtrRfrnCrrnt : 32|16@1+ (0.125,0) [0|8031.875] "A" Vector__XXX
 SG_ MtrGnrtr4InvrtrRfrnVltg : 48|16@1+ (0.125,0) [0|8031.875] "V" Vector__XXX
 SG_ MtrGnrtr4InvrtrRfrn2Cr : 0|8@1+ (1,0) [0|250] "count" Vector__XXX

BO_ 2566603006 MG4IT: 8 Vector__XXX
 SG_ MtrGnrtr4InvrtrTmprtr1 : 0|8@1+ (1,-40) [-40|210] "degC" Vector__XXX
 SG_ MtrGnrtr4InvrtrTmprtr2 : 8|8@1+ (1,-40) [-40|210] "degC" Vector__XXX
 SG_ MtrGnrtr4InvrtrTmprtr3 : 16|8@1+ (1,-40) [-40|210] "degC" Vector__XXX
 SG_ MtrGnrtr4InvrtrTmprtr4 : 24|8@1+ (1,-40) [-40|210] "degC" Vector__XXX
 SG_ MtrGnrtr4InvrtrTmprtr5 : 32|8@1+ (1,-40) [-40|210] "degC" Vector__XXX

BO_ 2566603262 MG4IMT: 8 Vector__XXX
 SG_ MotorGenerator4Temperature1 : 0|8@1+ (1,-40) [-40|210] "degC" Vector__XXX
 SG_ MotorGenerator4Temperature2 : 8|8@1+ (1,-40) [-40|210] "degC" Vector__XXX
 SG_ MotorGenerator4Temperature3 : 16|8@1+ (1,-40) [-40|210] "degC" Vector__XXX
 SG_ MotorGenerator4Temperature4 : 24|8@1+ (1,-40) [-40|210] "degC" Vector__XXX

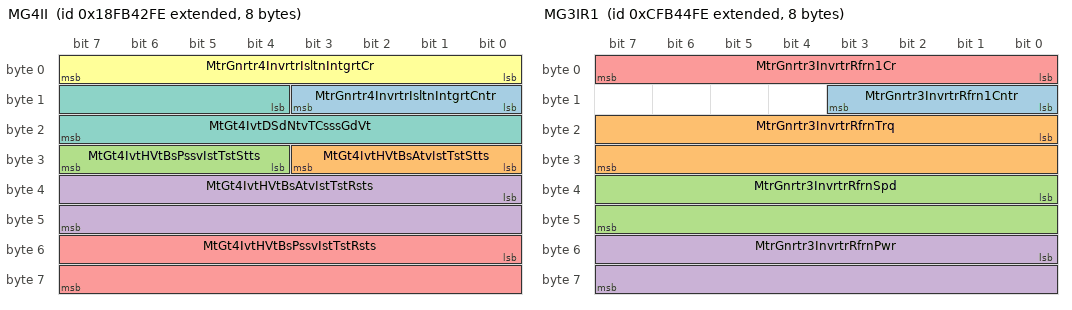
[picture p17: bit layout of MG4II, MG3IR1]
BO_ 2566603518 MG4II: 8 Vector__XXX
 SG_ MtrGnrtr4InvrtrIsltnIntgrtCntr : 8|4@1+ (1,0) [0|15] "" Vector__XXX
 SG_ MtGt4IvtHVtBsAtvIstTstStts : 24|4@1+ (1,0) [0|15] "" Vector__XXX
 SG_ MtGt4IvtHVtBsPssvIstTstStts : 28|4@1+ (1,0) [0|15] "" Vector__XXX
 SG_ MtGt4IvtHVtBsAtvIstTstRsts : 32|16@1+ (0.1,0) [0|6425.5] "OhmPerV" Vector__XXX
 SG_ MtGt4IvtHVtBsPssvIstTstRsts : 48|16@1+ (0.1,0) [0|6425.5] "OhmPerV" Vector__XXX
 SG_ MtrGnrtr4InvrtrIsltnIntgrtCr : 0|8@1+ (1,0) [0|250] "count" Vector__XXX
 SG_ MtGt4IvtDSdNtvTCsssGdVt : 12|12@1+ (0.0625,-125) [-125|125.9375] "%" Vector__XXX

BO_ 2566603774 MG4IAPL: 8 Vector__XXX
 SG_ MtGt4IvtPwLtdDTUddRs : 0|2@1+ (1,0) [0|3] "" Vector__XXX
 SG_ MtGt4IvtPwLtdDTMPwMx : 10|2@1+ (1,0) [0|3] "" Vector__XXX
 SG_ MtGt4IvtPwLtdDTMPwM : 12|2@1+ (1,0) [0|3] "" Vector__XXX
 SG_ MtrGnrtr4InvrtrPwrLmtdDTTrqMxmm : 18|2@1+ (1,0) [0|3] "" Vector__XXX
 SG_ MtrGnrtr4InvrtrPwrLmtdDTTrqMnmm : 20|2@1+ (1,0) [0|3] "" Vector__XXX
 SG_ MtrGnrtr4InvrtrPwrLmtdDTSpdMxmm : 22|2@1+ (1,0) [0|3] "" Vector__XXX
 SG_ MtrGnrtr4InvrtrPwrLmtdDTSpdMnmm : 24|2@1+ (1,0) [0|3] "" Vector__XXX
 SG_ MtGt4IvtPwLtdDTIvtTpt : 28|2@1+ (1,0) [0|3] "" Vector__XXX
 SG_ MtGt4IvtPwLtdDTMtTpt : 30|2@1+ (1,0) [0|3] "" Vector__XXX
 SG_ MtGt4IvtPwLtdDTFtCdt : 32|2@1+ (1,0) [0|3] "" Vector__XXX
 SG_ MtGt4IvtPwLtdDTAtvTqRtLt : 34|2@1+ (1,0) [0|3] "" Vector__XXX
 SG_ MtGt4IvtPwLtdDTAtvSpdRtLt : 36|2@1+ (1,0) [0|3] "" Vector__XXX
 SG_ MtGt4IvtTqLtdDTMCtsts : 38|2@1+ (1,0) [0|3] "" Vector__XXX
 SG_ MtGt4IvtPwLtdDTDSdCtMx : 2|2@1+ (1,0) [0|3] "" Vector__XXX
 SG_ MtGt4IvtPwLtdDTDSdCtM : 4|2@1+ (1,0) [0|3] "" Vector__XXX
 SG_ MtGt4IvtPwLtdDTDSdVtMx : 6|2@1+ (1,0) [0|3] "" Vector__XXX
 SG_ MtGt4IvtPwLtdDTDSdVtM : 8|2@1+ (1,0) [0|3] "" Vector__XXX
 SG_ MtGt4IvtPwLtdDTDSdPwMx : 14|2@1+ (1,0) [0|3] "" Vector__XXX
 SG_ MtGt4IvtPwLtdDTDSdPwM : 16|2@1+ (1,0) [0|3] "" Vector__XXX

BO_ 2365277438 MG3IR1: 8 Vector__XXX
 SG_ MtrGnrtr3InvrtrRfrn1Cntr : 8|4@1+ (1,0) [0|15] "" Vector__XXX
 SG_ MtrGnrtr3InvrtrRfrnTrq : 16|16@1+ (0.5,0) [0|32127.5] "Nm" Vector__XXX
 SG_ MtrGnrtr3InvrtrRfrnSpd : 32|16@1+ (4,0) [0|257020] "rpm" Vector__XXX
 SG_ MtrGnrtr3InvrtrRfrnPwr : 48|16@1+ (0.0625,0) [0|4015.9375] "kW" Vector__XXX
 SG_ MtrGnrtr3InvrtrRfrn1Cr : 0|8@1+ (1,0) [0|250] "count" Vector__XXX

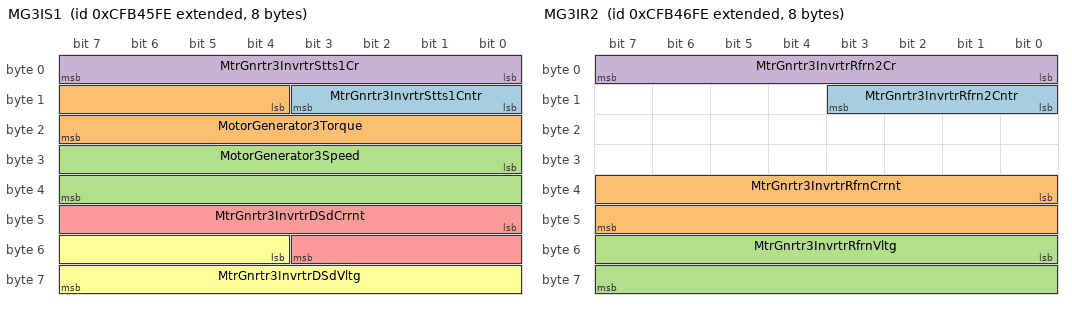
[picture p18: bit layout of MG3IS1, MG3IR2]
BO_ 2365277694 MG3IS1: 8 Vector__XXX
 SG_ MtrGnrtr3InvrtrStts1Cntr : 8|4@1+ (1,0) [0|15] "" Vector__XXX
 SG_ MotorGenerator3Torque : 12|12@1+ (0.0625,-125) [-125|125.9375] "%" Vector__XXX
 SG_ MotorGenerator3Speed : 24|16@1+ (0.00390625,-125) [-125|125.99609375] "%" Vector__XXX
 SG_ MtrGnrtr3InvrtrStts1Cr : 0|8@1+ (1,0) [0|250] "count" Vector__XXX
 SG_ MtrGnrtr3InvrtrDSdCrrnt : 40|12@1+ (0.0625,-125) [-125|125.9375] "%" Vector__XXX
 SG_ MtrGnrtr3InvrtrDSdVltg : 52|12@1+ (0.0625,-125) [-125|125.9375] "%" Vector__XXX

BO_ 2365277950 MG3IR2: 8 Vector__XXX
 SG_ MtrGnrtr3InvrtrRfrn2Cntr : 8|4@1+ (1,0) [0|15] "" Vector__XXX
 SG_ MtrGnrtr3InvrtrRfrnCrrnt : 32|16@1+ (0.125,0) [0|8031.875] "A" Vector__XXX
 SG_ MtrGnrtr3InvrtrRfrnVltg : 48|16@1+ (0.125,0) [0|8031.875] "V" Vector__XXX
 SG_ MtrGnrtr3InvrtrRfrn2Cr : 0|8@1+ (1,0) [0|250] "count" Vector__XXX

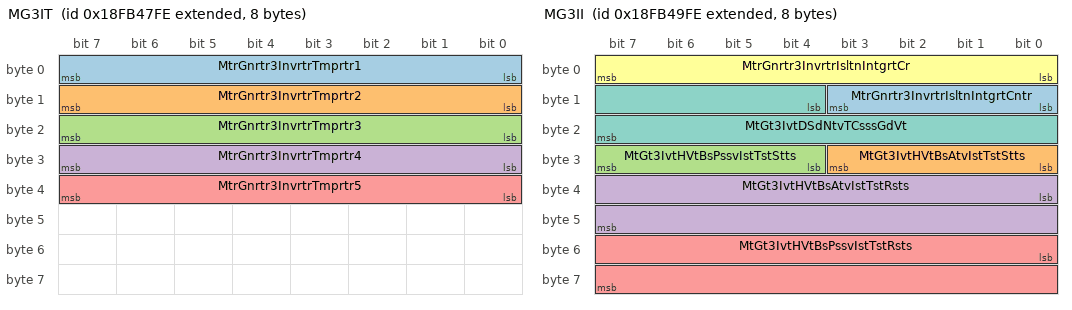
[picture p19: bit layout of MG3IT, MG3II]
BO_ 2566604798 MG3IT: 8 Vector__XXX
 SG_ MtrGnrtr3InvrtrTmprtr1 : 0|8@1+ (1,-40) [-40|210] "degC" Vector__XXX
 SG_ MtrGnrtr3InvrtrTmprtr2 : 8|8@1+ (1,-40) [-40|210] "degC" Vector__XXX
 SG_ MtrGnrtr3InvrtrTmprtr3 : 16|8@1+ (1,-40) [-40|210] "degC" Vector__XXX
 SG_ MtrGnrtr3InvrtrTmprtr4 : 24|8@1+ (1,-40) [-40|210] "degC" Vector__XXX
 SG_ MtrGnrtr3InvrtrTmprtr5 : 32|8@1+ (1,-40) [-40|210] "degC" Vector__XXX

BO_ 2566605054 MG3IMT: 8 Vector__XXX
 SG_ MotorGenerator3Temperature1 : 0|8@1+ (1,-40) [-40|210] "degC" Vector__XXX
 SG_ MotorGenerator3Temperature2 : 8|8@1+ (1,-40) [-40|210] "degC" Vector__XXX
 SG_ MotorGenerator3Temperature3 : 16|8@1+ (1,-40) [-40|210] "degC" Vector__XXX
 SG_ MotorGenerator3Temperature4 : 24|8@1+ (1,-40) [-40|210] "degC" Vector__XXX

BO_ 2566605310 MG3II: 8 Vector__XXX
 SG_ MtrGnrtr3InvrtrIsltnIntgrtCntr : 8|4@1+ (1,0) [0|15] "" Vector__XXX
 SG_ MtGt3IvtHVtBsAtvIstTstStts : 24|4@1+ (1,0) [0|15] "" Vector__XXX
 SG_ MtGt3IvtHVtBsPssvIstTstStts : 28|4@1+ (1,0) [0|15] "" Vector__XXX
 SG_ MtGt3IvtHVtBsAtvIstTstRsts : 32|16@1+ (0.1,0) [0|6425.5] "OhmPerV" Vector__XXX
 SG_ MtGt3IvtHVtBsPssvIstTstRsts : 48|16@1+ (0.1,0) [0|6425.5] "OhmPerV" Vector__XXX
 SG_ MtrGnrtr3InvrtrIsltnIntgrtCr : 0|8@1+ (1,0) [0|250] "count" Vector__XXX
 SG_ MtGt3IvtDSdNtvTCsssGdVt : 12|12@1+ (0.0625,-125) [-125|125.9375] "%" Vector__XXX

CM_ BO_ 2566590462 "NOx Tracking Stored 100 Hour Engine Output Energy Bins ";
CM_ SG_ 2566590462 NxTStd100HEOtptEB1Tt "NOx Tracking Stored 100 Hour Engine Output Energy Bin 1 (Total): Accumulated Engine output energy while all NOx sensors are active over the prior 100 hour period for Bin 1 [Note Bin 1 is the total of Bins 2-14]";
CM_ SG_ 2566590462 NxTrkngStrd100HrEngnOtptEnrgBn2 "NOx Tracking Stored 100 Hour Engine Output Energy Bin 2 : Accumulated Engine output energy while all NOx sensors are active over the prior 100 hour period for Bin 2 [Note Bin 2 is the 'idle' bin]";
CM_ SG_ 2566590462 NxTrkngStrd100HrEngnOtptEnrgBn3 "NOx Tracking Stored 100 Hour Engine Output Energy Bin 3 : Accumulated Engine output energy while all NOx sensors are active over the prior 100 hour period for Bin 3. ";
CM_ SG_ 2566590462 NxTrkngStrd100HrEngnOtptEnrgBn4 "NOx Tracking Stored 100 Hour Engine Output Energy Bin 4: Accumulated Engine output energy while all NOx sensors are active over the prior 100 hour period for Bin 4.";
CM_ SG_ 2566590462 NxTrkngStrd100HrEngnOtptEnrgBn5 "NOx Tracking Stored 100 Hour Engine Output Energy Bin 5: Accumulated Engine output energy while all NOx sensors are active over the prior 100 hour period for Bin 5.";
CM_ SG_ 2566590462 NxTrkngStrd100HrEngnOtptEnrgBn6 "NOx Tracking Stored 100 Hour Engine Output Energy Bin 6: Accumulated Engine output energy while all NOx sensors are active over the prior 100 hour period for Bin 6. ";
CM_ SG_ 2566590462 NxTrkngStrd100HrEngnOtptEnrgBn7 "NOx Tracking Stored 100 Hour Engine Output Energy Bin 7: Accumulated Engine output energy while all NOx sensors are active over the prior 100 hour period for Bin 7. ";
CM_ SG_ 2566590462 NxTrkngStrd100HrEngnOtptEnrgBn8 "NOx Tracking Stored 100 Hour Engine Output Energy Bin 8: Accumulated Engine output energy while all NOx sensors are active over the prior 100 hour period for Bin 8. ";
CM_ SG_ 2566590462 NxTrkngStrd100HrEngnOtptEnrgBn9 "NOx Tracking Stored 100 Hour Engine Output Energy Bin 9: Accumulated Engine output energy while all NOx sensors are active over the prior 100 hour period for Bin 9";
CM_ SG_ 2566590462 NxTStd100HEOtptEB10 "NOx Tracking Stored 100 Hour Engine Output Energy Bin 10: Accumulated Engine output energy while all NOx sensors are active over the prior 100 hour period for Bin 10";
CM_ SG_ 2566590462 NxTStd100HEOtptEB11 "NOx Tracking Stored 100 Hour Engine Output Energy Bin 11: Accumulated Engine output energy while all NOx sensors are active over the prior 100 hour period for Bin 11";
CM_ SG_ 2566590462 NxTStd100HEOtptEB12 "NOx Tracking Stored 100 Hour Engine Output Energy Bin 12: Accumulated Engine output energy while all NOx sensors are active over the prior 100 hour period for Bin 12";
CM_ SG_ 2566590462 NxTStd100HEOtptEB13 "NOx Tracking Stored 100 Hour Engine Output Energy Bin 13: Accumulated Engine output energy while all NOx sensors are active over the prior 100 hour period for Bin 13";
CM_ SG_ 2566590462 NxTStd100HEOtptEB14 "NOx Tracking Stored 100 Hour Engine Output Energy Bin 14 : Accumulated Engine output energy while all NOx sensors are active over the prior 100 hour period for Bin 14";
CM_ SG_ 2566590462 NxTStd100HEOtptEB15NtB "NOx Tracking Stored 100 Hour Engine Output Energy Bin 15 (NTE BIN) : Accumulated Engine output energy while all NOx sensors are active over the prior 100 hour period for Bin 15 [Note Bin 15 is the NTE Bin]";
CM_ SG_ 2566590462 NxTStd100HEOtptEB16RB "NOx Tracking Stored 100 Hour Engine Output Energy Bin 16 (Regen Bin) : Accumulated Engine output energy while all NOx sensors are active over the prior 100 hour period for Bin 16 [Note Bin 16 is the Regen Bin]";
CM_ SG_ 2566590462 NxTStd100HEOtptEB17MOB "NOx Tracking Stored 100 Hour Engine Output Energy Bin 17 (MIL On Bin) : Accumulated Engine output energy while all NOx sensors are active over the prior 100 hour period for Bin 17 [Note Bin 17 is the MIL On Bin]";
CM_ BO_ 2566590718 "NOx Tracking Stored 100 Hour Engine Out NOx Mass Bins ";
CM_ SG_ 2566590718 NxTStd100HEOtNxMssB1Tt "NOx Tracking Stored 100 Hour Engine Out NOx Mass Bin 1 (Total): Accumulated Engine out NOx mass while all NOx sensors are active over the prior 100 hour period for Bin 1 [Note Bin 1 is the total of Bins 2-14]";
CM_ SG_ 2566590718 NxTrkngStrd100HrEngnOtNxMssBn2 "NOx Tracking Stored 100 Hour Engine Out NOx Mass Bin 2 : Accumulated Engine out NOx mass while all NOx sensors are active over the prior 100 hour period for Bin 2 [Note Bin 2 is the 'idle' bin]";
CM_ SG_ 2566590718 NxTrkngStrd100HrEngnOtNxMssBn3 "NOx Tracking Stored 100 Hour Engine Out NOx Mass Bin 3 : Accumulated Engine out NOx mass while all NOx sensors are active over the prior 100 hour period for Bin 3. ";
CM_ SG_ 2566590718 NxTrkngStrd100HrEngnOtNxMssBn4 "NOx Tracking Stored 100 Hour Engine Out NOx Mass Bin 4: Accumulated Engine out NOx mass while all NOx sensors are active over the prior 100 hour period for Bin 4.";
CM_ SG_ 2566590718 NxTrkngStrd100HrEngnOtNxMssBn5 "NOx Tracking Stored 100 Hour Engine Out NOx Mass Bin 5: Accumulated Engine out NOx mass while all NOx sensors are active over the prior 100 hour period for Bin 5.";
CM_ SG_ 2566590718 NxTrkngStrd100HrEngnOtNxMssBn6 "NOx Tracking Stored 100 Hour Engine Out NOx Mass Bin 6: Accumulated Engine out NOx mass while all NOx sensors are active over the prior 100 hour period for Bin 6. ";
CM_ SG_ 2566590718 NxTrkngStrd100HrEngnOtNxMssBn7 "NOx Tracking Stored 100 Hour Engine Out NOx Mass Bin 7: Accumulated Engine out NOx mass while all NOx sensors are active over the prior 100 hour period for Bin 7. ";
CM_ SG_ 2566590718 NxTrkngStrd100HrEngnOtNxMssBn8 "NOx Tracking Stored 100 Hour Engine Out NOx Mass Bin 8: Accumulated Engine out NOx mass while all NOx sensors are active over the prior 100 hour period for Bin 8. ";
CM_ SG_ 2566590718 NxTrkngStrd100HrEngnOtNxMssBn9 "NOx Tracking Stored 100 Hour Engine Out NOx Mass Bin 9: Accumulated Engine out NOx mass while all NOx sensors are active over the prior 100 hour period for Bin 9";
CM_ SG_ 2566590718 NxTrkngStrd100HrEngnOtNxMssBn10 "NOx Tracking Stored 100 Hour Engine Out NOx Mass Bin 10: Accumulated Engine out NOx mass while all NOx sensors are active over the prior 100 hour period for Bin 10";
CM_ SG_ 2566590718 NxTrkngStrd100HrEngnOtNxMssBn11 "NOx Tracking Stored 100 Hour Engine Out NOx Mass Bin 11: Accumulated Engine out NOx mass while all NOx sensors are active over the prior 100 hour period for Bin 11";
CM_ SG_ 2566590718 NxTrkngStrd100HrEngnOtNxMssBn12 "NOx Tracking Stored 100 Hour Engine Out NOx Mass Bin 12: Accumulated Engine out NOx mass while all NOx sensors are active over the prior 100 hour period for Bin 12";
CM_ SG_ 2566590718 NxTrkngStrd100HrEngnOtNxMssBn13 "NOx Tracking Stored 100 Hour Engine Out NOx Mass Bin 13: Accumulated Engine out NOx mass while all NOx sensors are active over the prior 100 hour period for Bin 13";
CM_ SG_ 2566590718 NxTrkngStrd100HrEngnOtNxMssBn14 "NOx Tracking Stored 100 Hour Engine Out NOx Mass Bin 14 : Accumulated Engine out NOx mass while all NOx sensors are active over the prior 100 hour period for Bin 14";
CM_ SG_ 2566590718 NxTStd100HEOtNxMssB15NtB "NOx Tracking Stored 100 Hour Engine Out NOx Mass Bin 15 (NTE BIN) : Accumulated Engine out NOx mass while all NOx sensors are active over the prior 100 hour period for Bin 15 [Note Bin 15 is the NTE Bin]";
CM_ SG_ 2566590718 NxTStd100HEOtNxMssB16RB "NOx Tracking Stored 100 Hour Engine Out NOx Mass Bin 16 (Regen Bin) : Accumulated Engine out NOx mass while all NOx sensors are active over the prior 100 hour period for Bin 16 [Note Bin 16 is the Regen Bin]";
CM_ SG_ 2566590718 NxTStd100HEOtNxMssB17MOB "NOx Tracking Stored 100 Hour Engine Out NOx Mass Bin 17 (MIL On Bin) : Accumulated Engine out NOx mass while all NOx sensors are active over the prior 100 hour period for Bin 17 [Note Bin 17 is the Mil On Bin]";
CM_ BO_ 2566590974 "NOx Tracking Stored 100 Hour System Out NOx Mass Bins ";
CM_ SG_ 2566590974 NxTStd100HSstOtNxMssB1Tt "NOx Tracking Stored 100 Hour System Out NOx Mass Bin 1 (Total): Accumulated system out [SCR outlet] NOx mass while all NOx sensors are active over the prior 100 hour period for Bin 1 [Note Bin 1 is the total of Bins 2-14]";
CM_ SG_ 2566590974 NxTrkngStrd100HrSstmOtNxMssBn2 "NOx Tracking Stored 100 Hour System Out NOx Mass Bin 2 : Accumulated system out [SCR outlet] NOx mass while all NOx sensors are active over the prior 100 hour period for Bin 2 [Note Bin 2 is the 'idle' bin]";
CM_ SG_ 2566590974 NxTrkngStrd100HrSstmOtNxMssBn3 "NOx Tracking Stored 100 Hour System Out NOx Mass Bin 3 : Accumulated system out [SCR outlet] NOx mass while all NOx sensors are active over the prior 100 hour period for Bin 3.";
CM_ SG_ 2566590974 NxTrkngStrd100HrSstmOtNxMssBn4 "NOx Tracking Stored 100 Hour System Out NOx Mass Bin 4: Accumulated system out [SCR outlet] NOx mass while all NOx sensors are active over the prior 100 hour period for Bin 4.";
CM_ SG_ 2566590974 NxTrkngStrd100HrSstmOtNxMssBn5 "NOx Tracking Stored 100 Hour System Out NOx Mass Bin 5: Accumulated system out [SCR outlet] NOx mass while all NOx sensors are active over the prior 100 hour period for Bin 5.";
CM_ SG_ 2566590974 NxTrkngStrd100HrSstmOtNxMssBn6 "NOx Tracking Stored 100 Hour System Out NOx Mass Bin 6: Accumulated system out [SCR outlet] NOx mass while all NOx sensors are active over the prior 100 hour period for Bin 6. ";
CM_ SG_ 2566590974 NxTrkngStrd100HrSstmOtNxMssBn7 "NOx Tracking Stored 100 Hour System Out NOx Mass Bin 7: Accumulated system out [SCR outlet] NOx mass while all NOx sensors are active over the prior 100 hour period for Bin 7. ";
CM_ SG_ 2566590974 NxTrkngStrd100HrSstmOtNxMssBn8 "NOx Tracking Stored 100 Hour System Out NOx Mass Bin 8: Accumulated system out [SCR outlet] NOx mass while all NOx sensors are active over the prior 100 hour period for Bin 8. ";
CM_ SG_ 2566590974 NxTrkngStrd100HrSstmOtNxMssBn9 "NOx Tracking Stored 100 Hour System Out NOx Mass Bin 9: Accumulated system out [SCR outlet] NOx mass while all NOx sensors are active over the prior 100 hour period for Bin 9";
CM_ SG_ 2566590974 NxTrkngStrd100HrSstmOtNxMssBn10 "NOx Tracking Stored 100 Hour System Out NOx Mass Bin 10: Accumulated system out [SCR outlet] NOx mass while all NOx sensors are active over the prior 100 hour period for Bin 10 ";
CM_ SG_ 2566590974 NxTrkngStrd100HrSstmOtNxMssBn11 "NOx Tracking Stored 100 Hour System Out NOx Mass Bin 11: Accumulated system out [SCR outlet] NOx mass while all NOx sensors are active over the prior 100 hour period for Bin 11";
CM_ SG_ 2566590974 NxTrkngStrd100HrSstmOtNxMssBn12 "NOx Tracking Stored 100 Hour System Out NOx Mass Bin 12: Accumulated system out [SCR outlet] NOx mass while all NOx sensors are active over the prior 100 hour period for Bin 12";
CM_ SG_ 2566590974 NxTrkngStrd100HrSstmOtNxMssBn13 "NOx Tracking Stored 100 Hour System Out NOx Mass Bin 13: Accumulated system out [SCR outlet] NOx mass while all NOx sensors are active over the prior 100 hour period for Bin 13";
CM_ SG_ 2566590974 NxTrkngStrd100HrSstmOtNxMssBn14 "NOx Tracking Stored 100 Hour System Out NOx Mass Bin 14 : Accumulated system out [SCR outlet] NOx mass while all NOx sensors are active over the prior 100 hour period for Bin 14";
CM_ SG_ 2566590974 NxTStd100HSstOtNxMssB15NtB "NOx Tracking Stored 100 Hour System Out NOx Mass Bin 15 (NTE BIN) : Accumulated system out [SCR outlet] NOx mass while all NOx sensors are active over the prior 100 hour period for Bin 15 [Note Bin 15 is the Regen Bin]";
CM_ SG_ 2566590974 NxTStd100HSstOtNxMssB16RB "NOx Tracking Stored 100 Hour System Out NOx Mass Bin 16 (Regen Bin) : Accumulated system out [SCR outlet] NOx mass while all NOx sensors are active over the prior 100 hour period for Bin 16 [Note Bin 16 is the Regen Bin]";
CM_ SG_ 2566590974 NxTStd100HSstOtNxMssB17MOB "NOx Tracking Stored 100 Hour System Out NOx Mass Bin 17 (MIL On Bin) : Accumulated system out [SCR outlet] NOx mass while all NOx sensors are active over the prior 100 hour period for Bin 17 [Note Bin 17 is the MIL On Bin]";
CM_ BO_ 2566591230 "NOx Tracking Active 100 Hour Fuel Consumption Bins ";
CM_ SG_ 2566591230 NxTrkngAtv100HrFlCnsmptnBn1Ttl "NOx Tracking Active 100 Hour Fuel Consumption Bin 1 (Total): Accumulated Fuel consumption while all NOx sensors are active over the current 100 hour block for Bin 1 [Note Bin 1 is the total of Bins 2-14]";
CM_ SG_ 2566591230 NxTrkngAtv100HrFlCnsmptnBn2 "NOx Tracking Active 100 Hour Fuel Consumption Bin 2 : Accumulated Fuel consumption while all NOx sensors are active over the current 100 hour block for Bin 2 [Note Bin 2 is the 'idle' bin]";
CM_ SG_ 2566591230 NxTrkngAtv100HrFlCnsmptnBn3 "NOx Tracking Active 100 Hour Fuel Consumption Bin 3 : Accumulated Fuel consumption while all NOx sensors are active over the current 100 hour block for Bin 3.";
CM_ SG_ 2566591230 NxTrkngAtv100HrFlCnsmptnBn4 "NOx Tracking Active 100 Hour Fuel Consumption Bin 4: Accumulated Fuel consumption while all NOx sensors are active over the current 100 hour block for Bin 4.";
CM_ SG_ 2566591230 NxTrkngAtv100HrFlCnsmptnBn5 "NOx Tracking Active 100 Hour Fuel Consumption Bin 5: Accumulated Fuel consumption while all NOx sensors are active over the current 100 hour block for Bin 5.";
CM_ SG_ 2566591230 NxTrkngAtv100HrFlCnsmptnBn6 "NOx Tracking Active 100 Hour Fuel Consumption Bin 6: Accumulated Fuel consumption while all NOx sensors are active over the current 100 hour block for Bin 6. ";
CM_ SG_ 2566591230 NxTrkngAtv100HrFlCnsmptnBn7 "NOx Tracking Active 100 Hour Fuel Consumption Bin 7: Accumulated Fuel consumption while all NOx sensors are active over the current 100 hour block for Bin 7. ";
CM_ SG_ 2566591230 NxTrkngAtv100HrFlCnsmptnBn8 "NOx Tracking Active 100 Hour Fuel Consumption Bin 8: Accumulated Fuel consumption while all NOx sensors are active over the current 100 hour block for Bin 8. ";
CM_ SG_ 2566591230 NxTrkngAtv100HrFlCnsmptnBn9 "NOx Tracking Active 100 Hour Fuel Consumption Bin 9: Accumulated Fuel consumption while all NOx sensors are active over the current 100 hour block for Bin 9";
CM_ SG_ 2566591230 NxTrkngAtv100HrFlCnsmptnBn10 "NOx Tracking Active 100 Hour Fuel Consumption Bin 10: Accumulated Fuel consumption while all NOx sensors are active over the current 100 hour block for Bin 10";
CM_ SG_ 2566591230 NxTrkngAtv100HrFlCnsmptnBn11 "NOx Tracking Active 100 Hour Fuel Consumption Bin 11: Accumulated Fuel consumption while all NOx sensors are active over the current 100 hour block for Bin 11";
CM_ SG_ 2566591230 NxTrkngAtv100HrFlCnsmptnBn12 "NOx Tracking Active 100 Hour Fuel Consumption Bin 12: Accumulated Fuel consumption while all NOx sensors are active over the current 100 hour block for Bin 12";
CM_ SG_ 2566591230 NxTrkngAtv100HrFlCnsmptnBn13 "NOx Tracking Active 100 Hour Fuel Consumption Bin 13: Accumulated Fuel consumption while all NOx sensors are active over the current 100 hour block for Bin 13";
CM_ SG_ 2566591230 NxTrkngAtv100HrFlCnsmptnBn14 "NOx Tracking Active 100 Hour Fuel Consumption Bin 14 : Accumulated Fuel consumption while all NOx sensors are active over the current 100 hour block for Bin 14";
CM_ SG_ 2566591230 NxTAtv100HFCsptB15NtB "NOx Tracking Active 100 Hour Fuel Consumption Bin 15 (NTE BIN) : Accumulated Fuel consumption while all NOx sensors are active over the current 100 hour block for Bin 15 [Note Bin 15 is the NTE Bin]";
CM_ SG_ 2566591230 NxTAtv100HFCsptB16RB "NOx Tracking Active 100 Hour Fuel Consumption Bin 16 (Regen Bin) : Accumulated Fuel consumption while all NOx sensors are active over the current 100 hour block for Bin 16 [Note Bin 16 is the Regen Bin]";
CM_ SG_ 2566591230 NxTAtv100HFCsptB17MOB "NOx Tracking Active 100 Hour Fuel Consumption Bin 17 (MIL On Bin) : Accumulated Fuel consumption while all NOx sensors are active over the current 100 hour block for Bin 17 [Note Bin 17 is the Mil On Bin]";
CM_ BO_ 2566591486 "NOx Tracking Active 100 Hour Engine Run Time Bins ";
CM_ SG_ 2566591486 NxTrkngAtv100HrEngnRnTmBn1Ttl "NOx Tracking Active 100 Hour Engine Run Time Bin 1 (Total): Accumulated Engine run time while all NOx sensors are active over the current 100 hour block for Bin 1 [Note Bin 1 is the total of Bins 2-14]";
CM_ SG_ 2566591486 NxTrkngAtv100HrEngnRnTmBn2 "NOx Tracking Active 100 Hour Engine Run Time Bin 2 : Accumulated Engine run time while all NOx sensors are active over the current 100 hour block for Bin 2 [Note Bin 2 is the 'idle' bin]";
CM_ SG_ 2566591486 NxTrkngAtv100HrEngnRnTmBn3 "NOx Tracking Active 100 Hour Engine Run Time Bin 3 : Accumulated Engine run time while all NOx sensors are active over the current 100 hour block for Bin 3. ";
CM_ SG_ 2566591486 NxTrkngAtv100HrEngnRnTmBn4 "NOx Tracking Active 100 Hour Engine Run Time Bin 4: Accumulated Engine run time while all NOx sensors are active over the current 100 hour block for Bin 4. ";
CM_ SG_ 2566591486 NxTrkngAtv100HrEngnRnTmBn5 "NOx Tracking Active 100 Hour Engine Run Time Bin 5: Accumulated Engine run time while all NOx sensors are active over the current 100 hour block for Bin 5.";
CM_ SG_ 2566591486 NxTrkngAtv100HrEngnRnTmBn6 "NOx Tracking Active 100 Hour Engine Run Time Bin 6: Accumulated Engine run time while all NOx sensors are active over the current 100 hour block for Bin 6. ";
CM_ SG_ 2566591486 NxTrkngAtv100HrEngnRnTmBn7 "NOx Tracking Active 100 Hour Engine Run Time Bin 7: Accumulated Engine run time while all NOx sensors are active over the current 100 hour block for Bin 7. ";
CM_ SG_ 2566591486 NxTrkngAtv100HrEngnRnTmBn8 "NOx Tracking Active 100 Hour Engine Run Time Bin 8: Accumulated Engine run time while all NOx sensors are active over the current 100 hour block for Bin 8. ";
CM_ SG_ 2566591486 NxTrkngAtv100HrEngnRnTmBn9 "NOx Tracking Active 100 Hour Engine Run Time Bin 9: Accumulated Engine run time while all NOx sensors are active over the current 100 hour block for Bin 9";
CM_ SG_ 2566591486 NxTrkngAtv100HrEngnRnTmBn10 "NOx Tracking Active 100 Hour Engine Run Time Bin 10: Accumulated Engine run time while all NOx sensors are active over the current 100 hour block for Bin 10";
CM_ SG_ 2566591486 NxTrkngAtv100HrEngnRnTmBn11 "NOx Tracking Active 100 Hour Engine Run Time Bin 11: Accumulated Engine run time while all NOx sensors are active over the current 100 hour block for Bin 11";
CM_ SG_ 2566591486 NxTrkngAtv100HrEngnRnTmBn12 "NOx Tracking Active 100 Hour Engine Run Time Bin 12: Accumulated Engine run time while all NOx sensors are active over the current 100 hour block for Bin 12";
CM_ SG_ 2566591486 NxTrkngAtv100HrEngnRnTmBn13 "NOx Tracking Active 100 Hour Engine Run Time Bin 13: Accumulated Engine run time while all NOx sensors are active over the current 100 hour block for Bin 13";
CM_ SG_ 2566591486 NxTrkngAtv100HrEngnRnTmBn14 "NOx Tracking Active 100 Hour Engine Run Time Bin 14 : Accumulated Engine run time while all NOx sensors are active over the current 100 hour block for Bin 14";
CM_ SG_ 2566591486 NxTrkngAtv100HrEngnRnTmBn15NtBn "NOx Tracking Active 100 Hour Engine Run Time Bin 15 (NTE BIN) : Accumulated Engine run time while all NOx sensors are active over the current 100 hour block for Bin 15 [Note Bin 15 is the NTE Bin]";
CM_ SG_ 2566591486 NxTAtv100HERTB16RB "NOx Tracking Active 100 Hour Engine Run Time Bin 16 (Regen Bin) : Accumulated Engine run time while all NOx sensors are active over the current 100 hour block for Bin 16 [Note Bin 16 is the Regen Bin]";
CM_ SG_ 2566591486 NxTAtv100HERTB17MOB "NOx Tracking Active 100 Hour Engine Run Time Bin 17 (MIL On Bin) : Accumulated Engine run time while all NOx sensors are active over the current 100 hour block for Bin 17 [Note Bin 17 is the MIL On Bin]";
CM_ BO_ 2566591742 "NOx Tracking Active 100 Hour Vehicle Distance Bins ";
CM_ SG_ 2566591742 NxTrkngAtv100HrVhlDstnBn1Ttl "NOx Tracking Active 100 Hour Vehicle Distance Bin 1 (Total): Accumulated Vehicle distance while all NOx sensors are active over the current 100 hour block for Bin 1 [Note Bin 1 is the total of Bins 2-14]";
CM_ SG_ 2566591742 NxTrkngAtv100HrVhlDstnBn2 "NOx Tracking Active 100 Hour Vehicle Distance Bin 2 : Accumulated Vehicle distance while all NOx sensors are active over the current 100 hour block for Bin 2 [Note Bin 2 is the 'idle' bin]";
CM_ SG_ 2566591742 NxTrkngAtv100HrVhlDstnBn3 "NOx Tracking Active 100 Hour Vehicle Distance Bin 3 : Accumulated Vehicle distance while all NOx sensors are active over the current 100 hour block for Bin 3.";
CM_ SG_ 2566591742 NxTrkngAtv100HrVhlDstnBn4 "NOx Tracking Active 100 Hour Vehicle Distance Bin 4: Accumulated Vehicle distance while all NOx sensors are active over the current 100 hour block for Bin 4. ";
CM_ SG_ 2566591742 NxTrkngAtv100HrVhlDstnBn5 "NOx Tracking Active 100 Hour Vehicle Distance Bin 5: Accumulated Vehicle distance while all NOx sensors are active over the current 100 hour block for Bin 5.";
CM_ SG_ 2566591742 NxTrkngAtv100HrVhlDstnBn6 "NOx Tracking Active 100 Hour Vehicle Distance Bin 6: Accumulated Vehicle distance while all NOx sensors are active over the current 100 hour block for Bin 6. ";
CM_ SG_ 2566591742 NxTrkngAtv100HrVhlDstnBn7 "NOx Tracking Active 100 Hour Vehicle Distance Bin 7: Accumulated Vehicle distance while all NOx sensors are active over the current 100 hour block for Bin 7. ";
CM_ SG_ 2566591742 NxTrkngAtv100HrVhlDstnBn8 "NOx Tracking Active 100 Hour Vehicle Distance Bin 8: Accumulated Vehicle distance while all NOx sensors are active over the current 100 hour block for Bin 8. ";
CM_ SG_ 2566591742 NxTrkngAtv100HrVhlDstnBn9 "NOx Tracking Active 100 Hour Vehicle Distance Bin 9: Accumulated Vehicle distance while all NOx sensors are active over the current 100 hour block for Bin 9";
CM_ SG_ 2566591742 NxTrkngAtv100HrVhlDstnBn10 "NOx Tracking Active 100 Hour Vehicle Distance Bin 10: Accumulated Vehicle distance while all NOx sensors are active over the current 100 hour block for Bin 10";
CM_ SG_ 2566591742 NxTrkngAtv100HrVhlDstnBn11 "NOx Tracking Active 100 Hour Vehicle Distance Bin 11: Accumulated Vehicle distance while all NOx sensors are active over the current 100 hour block for Bin 11";
CM_ SG_ 2566591742 NxTrkngAtv100HrVhlDstnBn12 "NOx Tracking Active 100 Hour Vehicle Distance Bin 12: Accumulated Vehicle distance while all NOx sensors are active over the current 100 hour block for Bin 12";
CM_ SG_ 2566591742 NxTrkngAtv100HrVhlDstnBn13 "NOx Tracking Active 100 Hour Vehicle Distance Bin 13: Accumulated Vehicle distance while all NOx sensors are active over the current 100 hour block for Bin 13";
CM_ SG_ 2566591742 NxTrkngAtv100HrVhlDstnBn14 "NOx Tracking Active 100 Hour Vehicle Distance Bin 14 : Accumulated Vehicle distance while all NOx sensors are active over the current 100 hour block for Bin 14";
CM_ SG_ 2566591742 NxTrkngAtv100HrVhlDstnBn15NtBn "NOx Tracking Active 100 Hour Vehicle Distance Bin 15 (NTE BIN) : Accumulated Vehicle distance while all NOx sensors are active over the current 100 hour block for Bin 15 [Note Bin 15 is the NTE Bin]";
CM_ SG_ 2566591742 NxTrkngAtv100HrVhlDstnBn16RgnBn "NOx Tracking Active 100 Hour Vehicle Distance Bin 16 (Regen Bin) : Accumulated Vehicle distance while all NOx sensors are active over the current 100 hour block for Bin 16 [Note Bin 16 is the Regen Bin]";
CM_ SG_ 2566591742 NxTAtv100HVDstB17MOB "NOx Tracking Active 100 Hour Vehicle Distance Bin 17 (MIL On Bin) : Accumulated Vehicle distance while all NOx sensors are active over the current 100 hour block for Bin 17 [Note Bin 17 is the Mil On Bin]";
CM_ BO_ 2566591998 "NOx Tracking Active 100 Hour Engine Output Energy Bins ";
CM_ SG_ 2566591998 NxTAtv100HEOtptEB1Tt "NOx Tracking Active 100 Hour Engine Output Energy Bin 1 (Total): Accumulated Engine output energy while all NOx sensors are active over the current 100 hour block for Bin 1 [Note Bin 1 is the total of Bins 2-14]";
CM_ SG_ 2566591998 NxTrkngAtv100HrEngnOtptEnrgBn2 "NOx Tracking Active 100 Hour Engine Output Energy Bin 2 : Accumulated Engine output energy while all NOx sensors are active over the current 100 hour block for Bin 2 [Note Bin 2 is the 'idle' bin]";
CM_ SG_ 2566591998 NxTrkngAtv100HrEngnOtptEnrgBn3 "NOx Tracking Active 100 Hour Engine Output Energy Bin 3 : Accumulated Engine output energy while all NOx sensors are active over the current 100 hour block for Bin 3. ";
CM_ SG_ 2566591998 NxTrkngAtv100HrEngnOtptEnrgBn4 "NOx Tracking Active 100 Hour Engine Output Energy Bin 4: Accumulated Engine output energy while all NOx sensors are active over the current 100 hour block for Bin 4.";
CM_ SG_ 2566591998 NxTrkngAtv100HrEngnOtptEnrgBn5 "NOx Tracking Active 100 Hour Engine Output Energy Bin 5: Accumulated Engine output energy while all NOx sensors are active over the current 100 hour block for Bin 5.";
CM_ SG_ 2566591998 NxTrkngAtv100HrEngnOtptEnrgBn6 "NOx Tracking Active 100 Hour Engine Output Energy Bin 6: Accumulated Engine output energy while all NOx sensors are active over the current 100 hour block for Bin 6. ";
CM_ SG_ 2566591998 NxTrkngAtv100HrEngnOtptEnrgBn7 "NOx Tracking Active 100 Hour Engine Output Energy Bin 7: Accumulated Engine output energy while all NOx sensors are active over the current 100 hour block for Bin 7. ";
CM_ SG_ 2566591998 NxTrkngAtv100HrEngnOtptEnrgBn8 "NOx Tracking Active 100 Hour Engine Output Energy Bin 8: Accumulated Engine output energy while all NOx sensors are active over the current 100 hour block for Bin 8. ";
CM_ SG_ 2566591998 NxTrkngAtv100HrEngnOtptEnrgBn9 "NOx Tracking Active 100 Hour Engine Output Energy Bin 9: Accumulated Engine output energy while all NOx sensors are active over the current 100 hour block for Bin 9";
CM_ SG_ 2566591998 NxTrkngAtv100HrEngnOtptEnrgBn10 "NOx Tracking Active 100 Hour Engine Output Energy Bin 10: Accumulated Engine output energy while all NOx sensors are active over the current 100 hour block for Bin 10";
CM_ SG_ 2566591998 NxTrkngAtv100HrEngnOtptEnrgBn11 "NOx Tracking Active 100 Hour Engine Output Energy Bin 11: Accumulated Engine output energy while all NOx sensors are active over the current 100 hour block for Bin 11";
CM_ SG_ 2566591998 NxTrkngAtv100HrEngnOtptEnrgBn12 "NOx Tracking Active 100 Hour Engine Output Energy Bin 12: Accumulated Engine output energy while all NOx sensors are active over the current 100 hour block for Bin 12";
CM_ SG_ 2566591998 NxTrkngAtv100HrEngnOtptEnrgBn13 "NOx Tracking Active 100 Hour Engine Output Energy Bin 13: Accumulated Engine output energy while all NOx sensors are active over the current 100 hour block for Bin 13";
CM_ SG_ 2566591998 NxTrkngAtv100HrEngnOtptEnrgBn14 "NOx Tracking Active 100 Hour Engine Output Energy Bin 14 : Accumulated Engine output energy while all NOx sensors are active over the current 100 hour block for Bin 14";
CM_ SG_ 2566591998 NxTAtv100HEOtptEB15NtB "NOx Tracking Active 100 Hour Engine Output Energy Bin 15 (NTE BIN) : Accumulated Engine output energy while all NOx sensors are active over the current 100 hour block for Bin 15 [Note Bin 15 is the NTE Bin]";
CM_ SG_ 2566591998 NxTAtv100HEOtptEB16RB "NOx Tracking Active 100 Hour Engine Output Energy Bin 16 (Regen Bin) : Accumulated Engine output energy while all NOx sensors are active over the current 100 hour block for Bin 16 [Note Bin 16 is the Regen Bin]";
CM_ SG_ 2566591998 NxTAtv100HEOtptEB17MOB "NOx Tracking Active 100 Hour Engine Output Energy Bin 17 (MIL On Bin) : Accumulated Engine output energy while all NOx sensors are active over the current 100 hour block for Bin 17 [Note Bin 17 is the MIL On Bin]";
CM_ BO_ 2566592254 "NOx Tracking Active 100 Hour Engine Out NOx Mass Bins ";
CM_ SG_ 2566592254 NxTAtv100HEOtNxMssB1Tt "NOx Tracking Active 100 Hour Engine Out NOx Mass Bin 1 (Total): Accumulated Engine out NOx mass while all NOx sensors are active over the current 100 hour block for Bin 1 [Note Bin 1 is the total of Bins 2-14]";
CM_ SG_ 2566592254 NxTrkngAtv100HrEngnOtNxMssBn2 "NOx Tracking Active 100 Hour Engine Out NOx Mass Bin 2 : Accumulated Engine out NOx mass while all NOx sensors are active over the current 100 hour block for Bin 2 [Note Bin 2 is the 'idle' bin]";
CM_ SG_ 2566592254 NxTrkngAtv100HrEngnOtNxMssBn3 "NOx Tracking Active 100 Hour Engine Out NOx Mass Bin 3 : Accumulated Engine out NOx mass while all NOx sensors are active over the current 100 hour block for Bin 3. ";
CM_ SG_ 2566592254 NxTrkngAtv100HrEngnOtNxMssBn4 "NOx Tracking Active 100 Hour Engine Out NOx Mass Bin 4: Accumulated Engine out NOx mass while all NOx sensors are active over the current 100 hour block for Bin 4.";
CM_ SG_ 2566592254 NxTrkngAtv100HrEngnOtNxMssBn5 "NOx Tracking Active 100 Hour Engine Out NOx Mass Bin 5: Accumulated Engine out NOx mass while all NOx sensors are active over the current 100 hour block for Bin 5.";
CM_ SG_ 2566592254 NxTrkngAtv100HrEngnOtNxMssBn6 "NOx Tracking Active 100 Hour Engine Out NOx Mass Bin 6: Accumulated Engine out NOx mass while all NOx sensors are active over the current 100 hour block for Bin 6. ";
CM_ SG_ 2566592254 NxTrkngAtv100HrEngnOtNxMssBn7 "NOx Tracking Active 100 Hour Engine Out NOx Mass Bin 7: Accumulated Engine out NOx mass while all NOx sensors are active over the current 100 hour block for Bin 7. ";
CM_ SG_ 2566592254 NxTrkngAtv100HrEngnOtNxMssBn8 "NOx Tracking Active 100 Hour Engine Out NOx Mass Bin 8: Accumulated Engine out NOx mass while all NOx sensors are active over the current 100 hour block for Bin 8. ";
CM_ SG_ 2566592254 NxTrkngAtv100HrEngnOtNxMssBn9 "NOx Tracking Active 100 Hour Engine Out NOx Mass Bin 9: Accumulated Engine out NOx mass while all NOx sensors are active over the current 100 hour block for Bin 9";
CM_ SG_ 2566592254 NxTrkngAtv100HrEngnOtNxMssBn10 "NOx Tracking Active 100 Hour Engine Out NOx Mass Bin 10: Accumulated Engine out NOx mass while all NOx sensors are active over the current 100 hour block for Bin 10";
CM_ SG_ 2566592254 NxTrkngAtv100HrEngnOtNxMssBn11 "NOx Tracking Active 100 Hour Engine Out NOx Mass Bin 11: Accumulated Engine out NOx mass while all NOx sensors are active over the current 100 hour block for Bin 11";
CM_ SG_ 2566592254 NxTrkngAtv100HrEngnOtNxMssBn12 "NOx Tracking Active 100 Hour Engine Out NOx Mass Bin 12: Accumulated Engine out NOx mass while all NOx sensors are active over the current 100 hour block for Bin 12";
CM_ SG_ 2566592254 NxTrkngAtv100HrEngnOtNxMssBn13 "NOx Tracking Active 100 Hour Engine Out NOx Mass Bin 13: Accumulated Engine out NOx mass while all NOx sensors are active over the current 100 hour block for Bin 13";
CM_ SG_ 2566592254 NxTrkngAtv100HrEngnOtNxMssBn14 "NOx Tracking Active 100 Hour Engine Out NOx Mass Bin 14 : Accumulated Engine out NOx mass while all NOx sensors are active over the current 100 hour block for Bin 14";
CM_ SG_ 2566592254 NxTAtv100HEOtNxMssB15NtB "NOx Tracking Active 100 Hour Engine Out NOx Mass Bin 15 (NTE BIN) : Accumulated Engine out NOx mass while all NOx sensors are active over the current 100 hour block for Bin 15 [Note Bin 15 is the NTE Bin]";
CM_ SG_ 2566592254 NxTAtv100HEOtNxMssB16RB "NOx Tracking Active 100 Hour Engine Out NOx Mass Bin 16 (Regen Bin) : Accumulated Engine out NOx mass while all NOx sensors are active over the current 100 hour block for Bin 16 [Note Bin 16 is the Regen Bin]";
CM_ SG_ 2566592254 NxTAtv100HEOtNxMssB17MOB "NOx Tracking Active 100 Hour Engine Out NOx Mass Bin 17 (MIL On Bin) : Accumulated Engine out NOx mass while all NOx sensors are active over the current 100 hour block for Bin 17 [Note Bin 17 the Mil On Bin]";
CM_ BO_ 2566592510 "NOx Tracking Active 100 Hour System Out NOx Mass Bins ";
CM_ SG_ 2566592510 NxTAtv100HSstOtNxMssB1Tt "NOx Tracking Active 100 Hour System Out NOx Mass Bin 1 (Total): Accumulated system out [SCR outlet] NOx mass while all NOx sensors are active over the current 100 hour block for Bin 1 [Note Bin 1 is the total of Bins 2-14]";
CM_ SG_ 2566592510 NxTrkngAtv100HrSstmOtNxMssBn2 "NOx Tracking Active 100 Hour System Out NOx Mass Bin 2 : Accumulated system out [SCR outlet] NOx mass while all NOx sensors are active over the current 100 hour block for Bin 2 [Note Bin 2 is the 'idle' bin]";
CM_ SG_ 2566592510 NxTrkngAtv100HrSstmOtNxMssBn3 "NOx Tracking Active 100 Hour System Out NOx Mass Bin 3 : Accumulated system out [SCR outlet] NOx mass while all NOx sensors are active over the current 100 hour block for Bin 3.";
CM_ SG_ 2566592510 NxTrkngAtv100HrSstmOtNxMssBn4 "NOx Tracking Active 100 Hour System Out NOx Mass Bin 4: Accumulated system out [SCR outlet] NOx mass while all NOx sensors are active over the current 100 hour block for Bin 4.";
CM_ SG_ 2566592510 NxTrkngAtv100HrSstmOtNxMssBn5 "NOx Tracking Active 100 Hour System Out NOx Mass Bin 5: Accumulated system out [SCR outlet] NOx mass while all NOx sensors are active over the current 100 hour block for Bin 5.";
CM_ SG_ 2566592510 NxTrkngAtv100HrSstmOtNxMssBn6 "NOx Tracking Active 100 Hour System Out NOx Mass Bin 6: Accumulated system out [SCR outlet] NOx mass while all NOx sensors are active over the current 100 hour block for Bin 6. ";
CM_ SG_ 2566592510 NxTrkngAtv100HrSstmOtNxMssBn7 "NOx Tracking Active 100 Hour System Out NOx Mass Bin 7: Accumulated system out [SCR outlet] NOx mass while all NOx sensors are active over the current 100 hour block for Bin 7. ";
CM_ SG_ 2566592510 NxTrkngAtv100HrSstmOtNxMssBn8 "NOx Tracking Active 100 Hour System Out NOx Mass Bin 8: Accumulated system out [SCR outlet] NOx mass while all NOx sensors are active over the current 100 hour block for Bin 8. ";
CM_ SG_ 2566592510 NxTrkngAtv100HrSstmOtNxMssBn9 "NOx Tracking Active 100 Hour System Out NOx Mass Bin 9: Accumulated system out [SCR outlet] NOx mass while all NOx sensors are active over the current 100 hour block for Bin 9";
CM_ SG_ 2566592510 NxTrkngAtv100HrSstmOtNxMssBn10 "NOx Tracking Active 100 Hour System Out NOx Mass Bin 10: Accumulated system out [SCR outlet] NOx mass while all NOx sensors are active over the current 100 hour block for Bin 10 ";
CM_ SG_ 2566592510 NxTrkngAtv100HrSstmOtNxMssBn11 "NOx Tracking Active 100 Hour System Out NOx Mass Bin 11: Accumulated system out [SCR outlet] NOx mass while all NOx sensors are active over the current 100 hour block for Bin 11";
CM_ SG_ 2566592510 NxTrkngAtv100HrSstmOtNxMssBn12 "NOx Tracking Active 100 Hour System Out NOx Mass Bin 12: Accumulated system out [SCR outlet] NOx mass while all NOx sensors are active over the current 100 hour block for Bin 12";
CM_ SG_ 2566592510 NxTrkngAtv100HrSstmOtNxMssBn13 "NOx Tracking Active 100 Hour System Out NOx Mass Bin 13: Accumulated system out [SCR outlet] NOx mass while all NOx sensors are active over the current 100 hour block for Bin 13";
CM_ SG_ 2566592510 NxTrkngAtv100HrSstmOtNxMssBn14 "NOx Tracking Active 100 Hour System Out NOx Mass Bin 14 : Accumulated system out [SCR outlet] NOx mass while all NOx sensors are active over the current 100 hour block for Bin 14";
CM_ SG_ 2566592510 NxTAtv100HSstOtNxMssB15NtB "NOx Tracking Active 100 Hour System Out NOx Mass Bin 15 (NTE BIN) : Accumulated system out [SCR outlet] NOx mass while all NOx sensors are active over the current 100 hour block for Bin 15 [Note Bin 15 is the Regen Bin]";
CM_ SG_ 2566592510 NxTAtv100HSstOtNxMssB16RB "NOx Tracking Active 100 Hour System Out NOx Mass Bin 16 (Regen Bin) : Accumulated system out [SCR outlet] NOx mass while all NOx sensors are active over the current 100 hour block for Bin 16 [Note Bin 16 is the Regen Bin]";
CM_ SG_ 2566592510 NxTAtv100HSstOtNxMssB17MOB "NOx Tracking Active 100 Hour System Out NOx Mass Bin 17 (MIL On Bin) : Accumulated system out [SCR outlet] NOx mass while all NOx sensors are active over the current 100 hour block for Bin 17 [Note Bin 17 is the MIL On Bin]";
CM_ BO_ 2365266174 "Motor/Generator 6 Inverter Control 2";
CM_ SG_ 2365266174 MtrGnrtr6InvrtrRtLmtsRqst2Cntr "Motor/Generator 6 Inverter Rate Limits Request 2 Counter: The message counter is used to detect situations where the transmitting ECU malfunction repeats the same frame all the time. The receiver of the information may use the counter parameter to de...";
CM_ SG_ 2365266174 MtrGnrtr6InvrtrRtLmtsRqst2Cr "Motor/Generator 6 Inverter Rate Limits Request 2 CRC: The CRC is defined as follows: - Length: 8 bits- Polynomial: x^8+x^5+x^3+x^2+x+1- Initial Value: FFh- Input Data Reflection: Not reflected- Result Data Reflection: Not reflected- XOR value: FFh SA...";
CM_ SG_ 2365266174 MtrGnrtr6InvrtrPdCntrlAppllMd "Motor/Generator 6 Inverter PID Control Applicable Mode : Defines the Mode for which the PID Gain parameters apply within this instance of the inverter. See SPN 12172 [Control Setpoint Mode] for a definition of modes for control purposes.Applicable mo...";
CM_ SG_ 2365266174 MtGt6IvtPdCtNzdDtG "Motor/Generator 6 Inverter PID Control Normalized Differential Gain: A PID controller can be parametrized by factors Kp, Ki and Kd. This parameter defines the normalized integral gain (Kin) for control applications in this inverter instance. The norm...";
CM_ SG_ 2365266174 MtGt6IvtPdCtNzdItG "Motor/Generator 6 Inverter PID Control Normalized Integral Gain: A PID controller can be parametrized by factors Kp, Ki and Kd. This parameter defines the normalized integral gain (Kin) for control applications in this inverter instance. The normaliz...";
CM_ SG_ 2365266174 MtGt6IvtPdCtNzdPptG "Motor/Generator 6 Inverter PID Control Normalized Proportional Gain: A PID controller can be parametrized by factors Kp, Ki and Kd. This parameter defines the normalized proportional gain (Kpn) for control applications in this inverter instance. The ...";
CM_ SG_ 2365266174 MtGt6IvtPdCtFdFwdTq "Motor/Generator 6 Inverter PID Control Feed-Forward Torque: A PID controller can have a Feed-Forward Torque added to its output. This parameter defines the Feed-Forward Torque Setpoint for control applications in this inverter instance. The Setpoint ...";
CM_ BO_ 2566593022 "Motor/Generator 6 Inverter Limits Request Power";
CM_ SG_ 2566593022 MtrGnrtr6InvrtrLmtsRqstPwrCntr "Motor/Generator 6 Inverter Limits Request Power Counter: The message counter is used to detect situations where the transmitting ECU malfunction repeats the same frame all the time. The receiver of the information may use the counter parameter to det...";
CM_ SG_ 2566593022 MtGt6IvtLtsRqstMPwMx "Motor/Generator 6 Inverter Limits Request Mechanical Power Maximum: This requests a maximum limit for the mechanical power.Refer to SPN 12177 [Reference Power] to convert % to kW. Request a value of FBFh to instruct the inverter to use its default va...";
CM_ SG_ 2566593022 MtGt6IvtLtsRqstMPwM "Motor/Generator 6 Inverter Limits Request Mechanical Power Minimum: This requests a minimum limit for the mechanical power.Refer to SPN 12177 [Reference Power] to convert % to kW. Request a value of FBFh to instruct the inverter to use its default va...";
CM_ SG_ 2566593022 MtrGnrtr6InvrtrLmtsRqstPwrCr "Motor/Generator 6 Inverter Limits Request Power CRC: The CRC is defined as follows: - Length: 8 bits- Polynomial: x^8+x^5+x^3+x^2+x+1- Initial Value: FFh- Input Data Reflection: Not reflected- Result Data Reflection: Not reflected- XOR value: FFh SAE...";
CM_ SG_ 2566593022 MtGt6IvtLtsRqstDSdPwMx "Motor/Generator 6 Inverter Limits Request DC Side Power Maximum: This requests a maximum limit for the DC Side power.Refer to SPN 12177 [Reference Power] to convert % to kW. Request a value of FBFh to instruct the inverter to use its default values.F...";
CM_ SG_ 2566593022 MtGt6IvtLtsRqstDSdPwM "Motor/Generator 6 Inverter Limits Request DC Side Power Minimum: This requests a minimum limit for the DC Side power.Refer to SPN 12177 [Reference Power] to convert % to kW. Request a value of FBFh to instruct the inverter to use its default values.F...";
CM_ BO_ 2566593278 "Motor/Generator 6 Inverter Limits Request Mechanical";
CM_ SG_ 2566593278 MtrGnrtr6InvrtrLmtsRqstMhnlCntr "Motor/Generator 6 Inverter Limits Request Mechanical Counter: The message counter is used to detect situations where the transmitting ECU malfunction repeats the same frame all the time. The receiver of the information may use the counter parameter t...";
CM_ SG_ 2566593278 MtrGnrtr6InvrtrLmtsRqstTrqMxmm "Motor/Generator 6 Inverter Limits Request Torque Maximum: This requests a maximum torque the inverter should command for this device.Refer to SPN 12175 [Reference Torque] to convert % to Nm. Request a value of FBFh to instruct the inverter to use its...";
CM_ SG_ 2566593278 MtrGnrtr6InvrtrLmtsRqstTrqMnmm "Motor/Generator 6 Inverter Limits Request Torque Minimum: This requests a minimum torque the inverter should command for this device.Refer to SPN 12175 [Reference Torque] to convert % to Nm. Request a value of FBFh to instruct the inverter to use its...";
CM_ SG_ 2566593278 MtrGnrtr6InvrtrLmtsRqstSpdMxmm "Motor/Generator 6 Inverter Limits Request Speed Maximum: This is a request to the inverter to set a maximum speed limit for this device.Refer to SPN 12176 [Reference Speed] to convert % to rpm. Request a value of FBFh to instruct the inverter to use ...";
CM_ SG_ 2566593278 MtrGnrtr6InvrtrLmtsRqstSpdMnmm "Motor/Generator 6 Inverter Limits Request Speed Minimum: This is a request to the inverter to set a minimum speed limit for this device.Refer to SPN 12176 [Reference Speed] to convert % to rpm. Request a value of FBFh to instruct the inverter to use ...";
CM_ SG_ 2566593278 MtrGnrtr6InvrtrLmtsRqstMhnlCr "Motor/Generator 6 Inverter Limits Request Mechanical CRC: The CRC is defined as follows: - Length: 8 bits- Polynomial: x^8+x^5+x^3+x^2+x+1- Initial Value: FFh- Input Data Reflection: Not reflected- Result Data Reflection: Not reflected- XOR value: FF...";
CM_ BO_ 2566593534 "Motor/Generator 6 Inverter Limits Request DC Side";
CM_ SG_ 2566593534 MtrGnrtr6InvrtrLmtsRqstDSdCr "Motor/Generator 6 Inverter Limits Request DC Side CRC: The CRC is defined as follows: - Length: 8 bits- Polynomial: x^8+x^5+x^3+x^2+x+1- Initial Value: FFh- Input Data Reflection: Not reflected- Result Data Reflection: Not reflected- XOR value: FFh S...";
CM_ SG_ 2566593534 MtrGnrtr6InvrtrLmtsRqstDSdCntr "Motor/Generator 6 Inverter Limits Request DC Side Counter: The message counter is used to detect situations where the transmitting ECU malfunction repeats the same frame all the time. The receiver of the information may use the counter parameter to d...";
CM_ SG_ 2566593534 MtGt6IvtLtsRqstDSdVtMx "Motor/Generator 6 Inverter Limits Request DC Side Voltage Maximum: This is a request to the inverter to set a maximum DC Side Voltage limit for this device instance.Refer to SPN 12208 [Reference Voltage] to convert % to Volts. Request a value of FBFh...";
CM_ SG_ 2566593534 MtGt6IvtLtsRqstDSdVtM "Motor/Generator 6 Inverter Limits Request DC Side Voltage Minimum: This is a request to the inverter to set a minimum DC Side Voltage limit for this device instance.Refer to SPN 12208 [Reference Voltage] to convert % to Volts. Request a value of FBFh...";
CM_ SG_ 2566593534 MtGt6IvtLtsRqstDSdCtMx "Motor/Generator 6 Inverter Limits Request DC Side Current Maximum: This is a request to the inverter to set a maximum DC Side Current limit for this device instance.Refer to SPN 12207 [Reference Current] to convert % to Amps. Request a value of FBFh ...";
CM_ SG_ 2566593534 MtGt6IvtLtsRqstDSdCtM "Motor/Generator 6 Inverter Limits Request DC Side Current Minimum: This is a request to the inverter to set a minimum DC Side Current limit for this device instance.Refer to SPN 12207 [Reference Current] to convert % to Amps. Request a value of FBFh ...";
CM_ BO_ 2566593790 "Motor/Generator 6 Inverter Isolation Integrity Request";
CM_ SG_ 2566593790 MtGt6IvtHVtBsAtvIstTstCd "Motor/Generator 6 Inverter High-Voltage Bus Active Isolation Test Command: Command for the inverter to perform an active electrical isolation test on the high voltage bus.An active isolation test might use a generated signal (e.g. an injected AC sign...";
CM_ SG_ 2566593790 MtGt6IvtHVtBsPssvIstTstCd "Motor/Generator 6 Inverter High-Voltage Bus Passive Isolation Test Command: Command for the inverter to perform a passive electrical isolation test on the high voltage bus.A passive isolation test uses additional circuitry (e.g. a high impedance netw...";
CM_ SG_ 2566593790 MtGt6IvtHVtBsHSdRsstCtRqst "Motor/Generator 6 Inverter High-Voltage Bus High Side Resistor Connect Request: This parameter is used to request connection of the inverter High-Voltage bus high side resistor in order to perform an isolation test. 00b = Connection not Requested01b ...";
CM_ SG_ 2566593790 MtGt6IvtHVtBsLwSdRsstCtRqst "Motor/Generator 6 Inverter High-Voltage Bus Low Side Resistor Connect Request: This parameter is used to request connection of the inverter High-Voltage bus low side resistor in order to perform an isolation test.  00b = Connection not Requested01b =...";
CM_ BO_ 2365267454 "Motor/Generator 5 Inverter Control 2";
CM_ SG_ 2365267454 MtrGnrtr5InvrtrRtLmtsRqst2Cntr "Motor/Generator 5 Inverter Rate Limits Request 2 Counter: The message counter is used to detect situations where the transmitting ECU malfunction repeats the same frame all the time. The receiver of the information may use the counter parameter to de...";
CM_ SG_ 2365267454 MtrGnrtr5InvrtrRtLmtsRqst2Cr "Motor/Generator 5 Inverter Rate Limits Request 2 CRC: The CRC is defined as follows: - Length: 8 bits- Polynomial: x^8+x^5+x^3+x^2+x+1- Initial Value: FFh- Input Data Reflection: Not reflected- Result Data Reflection: Not reflected- XOR value: FFh SA...";
CM_ SG_ 2365267454 MtrGnrtr5InvrtrPdCntrlAppllMd "Motor/Generator 5 Inverter PID Control Applicable Mode : Defines the Mode for which the PID Gain parameters apply within this instance of the inverter. See SPN 12054 [Control Setpoint Mode] for a definition of modes for control purposes.Applicable mo...";
CM_ SG_ 2365267454 MtGt5IvtPdCtNzdDtG "Motor/Generator 5 Inverter PID Control Normalized Differential Gain: A PID controller can be parametrized by factors Kp, Ki and Kd. This parameter defines the normalized integral gain (Kin) for control applications in this inverter instance. The norm...";
CM_ SG_ 2365267454 MtGt5IvtPdCtNzdItG "Motor/Generator 5 Inverter PID Control Normalized Integral Gain: A PID controller can be parametrized by factors Kp, Ki and Kd. This parameter defines the normalized integral gain (Kin) for control applications in this inverter instance. The normaliz...";
CM_ SG_ 2365267454 MtGt5IvtPdCtNzdPptG "Motor/Generator 5 Inverter PID Control Normalized Proportional Gain: A PID controller can be parametrized by factors Kp, Ki and Kd. This parameter defines the normalized proportional gain (Kpn) for control applications in this inverter instance. The ...";
CM_ SG_ 2365267454 MtGt5IvtPdCtFdFwdTq "Motor/Generator 5 Inverter PID Control Feed-Forward Torque: A PID controller can have a Feed-Forward Torque added to its output. This parameter defines the Feed-Forward Torque Setpoint for control applications in this inverter instance. The Setpoint ...";
CM_ BO_ 2566594302 "Motor/Generator 5 Inverter Limits Request Power";
CM_ SG_ 2566594302 MtrGnrtr5InvrtrLmtsRqstPwrCntr "Motor/Generator 5 Inverter Limits Request Power Counter: The message counter is used to detect situations where the transmitting ECU malfunction repeats the same frame all the time. The receiver of the information may use the counter parameter to det...";
CM_ SG_ 2566594302 MtGt5IvtLtsRqstMPwMx "Motor/Generator 5 Inverter Limits Request Mechanical Power Maximum: This requests a maximum limit for the mechanical power.Refer to SPN 12059 [Reference Power] to convert % to kW. Request a value of FBFh to instruct the inverter to use its default va...";
CM_ SG_ 2566594302 MtGt5IvtLtsRqstMPwM "Motor/Generator 5 Inverter Limits Request Mechanical Power Minimum: This requests a minimum limit for the mechanical power.Refer to SPN 12059 [Reference Power] to convert % to kW. Request a value of FBFh to instruct the inverter to use its default va...";
CM_ SG_ 2566594302 MtrGnrtr5InvrtrLmtsRqstPwrCr "Motor/Generator 5 Inverter Limits Request Power CRC: The CRC is defined as follows: - Length: 8 bits- Polynomial: x^8+x^5+x^3+x^2+x+1- Initial Value: FFh- Input Data Reflection: Not reflected- Result Data Reflection: Not reflected- XOR value: FFh SAE...";
CM_ SG_ 2566594302 MtGt5IvtLtsRqstDSdPwMx "Motor/Generator 5 Inverter Limits Request DC Side Power Maximum: This requests a maximum limit for the DC Side power.Refer to SPN 12059 [Reference Power] to convert % to kW. Request a value of FBFh to instruct the inverter to use its default values.F...";
CM_ SG_ 2566594302 MtGt5IvtLtsRqstDSdPwM "Motor/Generator 5 Inverter Limits Request DC Side Power Minimum: This requests a minimum limit for the DC Side power.Refer to SPN 12059 [Reference Power] to convert % to kW. Request a value of FBFh to instruct the inverter to use its default values.F...";
CM_ BO_ 2566594558 "Motor/Generator 5 Inverter Limits Request Mechanical";
CM_ SG_ 2566594558 MtrGnrtr5InvrtrLmtsRqstMhnlCntr "Motor/Generator 5 Inverter Limits Request Mechanical Counter: The message counter is used to detect situations where the transmitting ECU malfunction repeats the same frame all the time. The receiver of the information may use the counter parameter t...";
CM_ SG_ 2566594558 MtrGnrtr5InvrtrLmtsRqstTrqMxmm "Motor/Generator 5 Inverter Limits Request Torque Maximum: This requests a maximum torque the inverter should command for this device.Refer to SPN 12057 [Reference Torque] to convert % to Nm. Request a value of FBFh to instruct the inverter to use its...";
CM_ SG_ 2566594558 MtrGnrtr5InvrtrLmtsRqstTrqMnmm "Motor/Generator 5 Inverter Limits Request Torque Minimum: This requests a minimum torque the inverter should command for this device.Refer to SPN 12057 [Reference Torque] to convert % to Nm. Request a value of FBFh to instruct the inverter to use its...";
CM_ SG_ 2566594558 MtrGnrtr5InvrtrLmtsRqstSpdMxmm "Motor/Generator 5 Inverter Limits Request Speed Maximum: This is a request to the inverter to set a maximum speed limit for this device.Refer to SPN 12058 [Reference Speed] to convert % to rpm. Request a value of FBFh to instruct the inverter to use ...";
CM_ SG_ 2566594558 MtrGnrtr5InvrtrLmtsRqstSpdMnmm "Motor/Generator 5 Inverter Limits Request Speed Minimum: This is a request to the inverter to set a minimum speed limit for this device.Refer to SPN 12058 [Reference Speed] to convert % to rpm. Request a value of FBFh to instruct the inverter to use ...";
CM_ SG_ 2566594558 MtrGnrtr5InvrtrLmtsRqstMhnlCr "Motor/Generator 5 Inverter Limits Request Mechanical CRC: The CRC is defined as follows: - Length: 8 bits- Polynomial: x^8+x^5+x^3+x^2+x+1- Initial Value: FFh- Input Data Reflection: Not reflected- Result Data Reflection: Not reflected- XOR value: FF...";
CM_ BO_ 2566594814 "Motor/Generator 5 Inverter Limits Request DC Side";
CM_ SG_ 2566594814 MtrGnrtr5InvrtrLmtsRqstDSdCr "Motor/Generator 5 Inverter Limits Request DC Side CRC: The CRC is defined as follows: - Length: 8 bits- Polynomial: x^8+x^5+x^3+x^2+x+1- Initial Value: FFh- Input Data Reflection: Not reflected- Result Data Reflection: Not reflected- XOR value: FFh S...";
CM_ SG_ 2566594814 MtrGnrtr5InvrtrLmtsRqstDSdCntr "Motor/Generator 5 Inverter Limits Request DC Side Counter: The message counter is used to detect situations where the transmitting ECU malfunction repeats the same frame all the time. The receiver of the information may use the counter parameter to d...";
CM_ SG_ 2566594814 MtGt5IvtLtsRqstDSdVtMx "Motor/Generator 5 Inverter Limits Request DC Side Voltage Maximum: This is a request to the inverter to set a maximum DC Side Voltage limit for this device instance.Refer to SPN 12090 [Reference Voltage] to convert % to Volts. Request a value of FBFh...";
CM_ SG_ 2566594814 MtGt5IvtLtsRqstDSdVtM "Motor/Generator 5 Inverter Limits Request DC Side Voltage Minimum: This is a request to the inverter to set a minimum DC Side Voltage limit for this device instance.Refer to SPN 12090 [Reference Voltage] to convert % to Volts. Request a value of FBFh...";
CM_ SG_ 2566594814 MtGt5IvtLtsRqstDSdCtMx "Motor/Generator 5 Inverter Limits Request DC Side Current Maximum: This is a request to the inverter to set a maximum DC Side Current limit for this device instance.Refer to SPN 12089 [Reference Current] to convert % to Amps. Request a value of FBFh ...";
CM_ SG_ 2566594814 MtGt5IvtLtsRqstDSdCtM "Motor/Generator 5 Inverter Limits Request DC Side Current Minimum: This is a request to the inverter to set a minimum DC Side Current limit for this device instance.Refer to SPN 12089 [Reference Current] to convert % to Amps. Request a value of FBFh ...";
CM_ BO_ 2566595070 "Motor/Generator 5 Inverter Isolation Integrity Request";
CM_ SG_ 2566595070 MtGt5IvtHVtBsAtvIstTstCd "Motor/Generator 5 Inverter High-Voltage Bus Active Isolation Test Command: Command for the inverter to perform an active electrical isolation test on the high voltage bus.An active isolation test might use a generated signal (e.g. an injected AC sign...";
CM_ SG_ 2566595070 MtGt5IvtHVtBsPssvIstTstCd "Motor/Generator 5 Inverter High-Voltage Bus Passive Isolation Test Command: Command for the inverter to perform a passive electrical isolation test on the high voltage bus.A passive isolation test uses additional circuitry (e.g. a high impedance netw...";
CM_ SG_ 2566595070 MtGt5IvtHVtBsHSdRsstCtRqst "Motor/Generator 5 Inverter High-Voltage Bus High Side Resistor Connect Request: This parameter is used to request connection of the inverter High-Voltage bus high side resistor in order to perform an isolation test. 00b = Connection not Requested01b ...";
CM_ SG_ 2566595070 MtGt5IvtHVtBsLwSdRsstCtRqst "Motor/Generator 5 Inverter High-Voltage Bus Low Side Resistor Connect Request: This parameter is used to request connection of the inverter High-Voltage bus low side resistor in order to perform an isolation test.  00b = Connection not Requested01b =...";
CM_ BO_ 2365268734 "Motor/Generator 4 Inverter Control 2";
CM_ SG_ 2365268734 MtrGnrtr4InvrtrRtLmtsRqst2Cntr "Motor/Generator 4 Inverter Rate Limits Request 2 Counter: The message counter is used to detect situations where the transmitting ECU malfunction repeats the same frame all the time. The receiver of the information may use the counter parameter to de...";
CM_ SG_ 2365268734 MtrGnrtr4InvrtrRtLmtsRqst2Cr "Motor/Generator 4 Inverter Rate Limits Request 2 CRC: The CRC is defined as follows: - Length: 8 bits- Polynomial: x^8+x^5+x^3+x^2+x+1- Initial Value: FFh- Input Data Reflection: Not reflected- Result Data Reflection: Not reflected- XOR value: FFh SA...";
CM_ SG_ 2365268734 MtrGnrtr4InvrtrPdCntrlAppllMd "Motor/Generator 4 Inverter PID Control Applicable Mode : Defines the Mode for which the PID Gain parameters apply within this instance of the inverter. See SPN 11936 [Control Setpoint Mode] for a definition of modes for control purposes.Applicable mo...";
CM_ SG_ 2365268734 MtGt4IvtPdCtNzdDtG "Motor/Generator 4 Inverter PID Control Normalized Differential Gain: A PID controller can be parametrized by factors Kp, Ki and Kd. This parameter defines the normalized integral gain (Kin) for control applications in this inverter instance. The norm...";
CM_ SG_ 2365268734 MtGt4IvtPdCtNzdItG "Motor/Generator 4 Inverter PID Control Normalized Integral Gain: A PID controller can be parametrized by factors Kp, Ki and Kd. This parameter defines the normalized integral gain (Kin) for control applications in this inverter instance. The normaliz...";
CM_ SG_ 2365268734 MtGt4IvtPdCtNzdPptG "Motor/Generator 4 Inverter PID Control Normalized Proportional Gain: A PID controller can be parametrized by factors Kp, Ki and Kd. This parameter defines the normalized proportional gain (Kpn) for control applications in this inverter instance. The ...";
CM_ SG_ 2365268734 MtGt4IvtPdCtFdFwdTq "Motor/Generator 4 Inverter PID Control Feed-Forward Torque: A PID controller can have a Feed-Forward Torque added to its output. This parameter defines the Feed-Forward Torque Setpoint for control applications in this inverter instance. The Setpoint ...";
CM_ BO_ 2566595582 "Motor/Generator 4 Inverter Limits Request Power";
CM_ SG_ 2566595582 MtrGnrtr4InvrtrLmtsRqstPwrCntr "Motor/Generator 4 Inverter Limits Request Power Counter: The message counter is used to detect situations where the transmitting ECU malfunction repeats the same frame all the time. The receiver of the information may use the counter parameter to det...";
CM_ SG_ 2566595582 MtGt4IvtLtsRqstMPwMx "Motor/Generator 4 Inverter Limits Request Mechanical Power Maximum: This requests a maximum limit for the mechanical power.Refer to SPN 11941 [Reference Power] to convert % to kW. Request a value of FBFh to instruct the inverter to use its default va...";
CM_ SG_ 2566595582 MtGt4IvtLtsRqstMPwM "Motor/Generator 4 Inverter Limits Request Mechanical Power Minimum: This requests a minimum limit for the mechanical power.Refer to SPN 11941 [Reference Power] to convert % to kW. Request a value of FBFh to instruct the inverter to use its default va...";
CM_ SG_ 2566595582 MtrGnrtr4InvrtrLmtsRqstPwrCr "Motor/Generator 4 Inverter Limits Request Power CRC: The CRC is defined as follows: - Length: 8 bits- Polynomial: x^8+x^5+x^3+x^2+x+1- Initial Value: FFh- Input Data Reflection: Not reflected- Result Data Reflection: Not reflected- XOR value: FFh SAE...";
CM_ SG_ 2566595582 MtGt4IvtLtsRqstDSdPwMx "Motor/Generator 4 Inverter Limits Request DC Side Power Maximum: This requests a maximum limit for the DC Side power.Refer to SPN 11941 [Reference Power] to convert % to kW. Request a value of FBFh to instruct the inverter to use its default values.F...";
CM_ SG_ 2566595582 MtGt4IvtLtsRqstDSdPwM "Motor/Generator 4 Inverter Limits Request DC Side Power Minimum: This requests a minimum limit for the DC Side power.Refer to SPN 11941 [Reference Power] to convert % to kW. Request a value of FBFh to instruct the inverter to use its default values.F...";
CM_ BO_ 2566595838 "Motor/Generator 4 Inverter Limits Request Mechanical";
CM_ SG_ 2566595838 MtrGnrtr4InvrtrLmtsRqstMhnlCntr "Motor/Generator 4 Inverter Limits Request Mechanical Counter: The message counter is used to detect situations where the transmitting ECU malfunction repeats the same frame all the time. The receiver of the information may use the counter parameter t...";
CM_ SG_ 2566595838 MtrGnrtr4InvrtrLmtsRqstTrqMxmm "Motor/Generator 4 Inverter Limits Request Torque Maximum: This requests a maximum torque the inverter should command for this device.Refer to SPN 11939 [Reference Torque] to convert % to Nm. Request a value of FBFh to instruct the inverter to use its...";
CM_ SG_ 2566595838 MtrGnrtr4InvrtrLmtsRqstTrqMnmm "Motor/Generator 4 Inverter Limits Request Torque Minimum: This requests a minimum torque the inverter should command for this device.Refer to SPN 11939 [Reference Torque] to convert % to Nm. Request a value of FBFh to instruct the inverter to use its...";
CM_ SG_ 2566595838 MtrGnrtr4InvrtrLmtsRqstSpdMxmm "Motor/Generator 4 Inverter Limits Request Speed Maximum: This is a request to the inverter to set a maximum speed limit for this device.Refer to SPN 11940 [Reference Speed] to convert % to rpm. Request a value of FBFh to instruct the inverter to use ...";
CM_ SG_ 2566595838 MtrGnrtr4InvrtrLmtsRqstSpdMnmm "Motor/Generator 4 Inverter Limits Request Speed Minimum: This is a request to the inverter to set a minimum speed limit for this device.Refer to SPN 11940 [Reference Speed] to convert % to rpm. Request a value of FBFh to instruct the inverter to use ...";
CM_ SG_ 2566595838 MtrGnrtr4InvrtrLmtsRqstMhnlCr "Motor/Generator 4 Inverter Limits Request Mechanical CRC: The CRC is defined as follows: - Length: 8 bits- Polynomial: x^8+x^5+x^3+x^2+x+1- Initial Value: FFh- Input Data Reflection: Not reflected- Result Data Reflection: Not reflected- XOR value: FF...";
CM_ BO_ 2566596094 "Motor/Generator 4 Inverter Limits Request DC Side";
CM_ SG_ 2566596094 MtrGnrtr4InvrtrLmtsRqstDSdCr "Motor/Generator 4 Inverter Limits Request DC Side CRC: The CRC is defined as follows: - Length: 8 bits- Polynomial: x^8+x^5+x^3+x^2+x+1- Initial Value: FFh- Input Data Reflection: Not reflected- Result Data Reflection: Not reflected- XOR value: FFh S...";
CM_ SG_ 2566596094 MtrGnrtr4InvrtrLmtsRqstDSdCntr "Motor/Generator 4 Inverter Limits Request DC Side Counter: The message counter is used to detect situations where the transmitting ECU malfunction repeats the same frame all the time. The receiver of the information may use the counter parameter to d...";
CM_ SG_ 2566596094 MtGt4IvtLtsRqstDSdVtMx "Motor/Generator 4 Inverter Limits Request DC Side Voltage Maximum: This is a request to the inverter to set a maximum DC Side Voltage limit for this device instance.Refer to SPN 11972 [Reference Voltage] to convert % to Volts. Request a value of FBFh...";
CM_ SG_ 2566596094 MtGt4IvtLtsRqstDSdVtM "Motor/Generator 4 Inverter Limits Request DC Side Voltage Minimum: This is a request to the inverter to set a minimum DC Side Voltage limit for this device instance.Refer to SPN 11972 [Reference Voltage] to convert % to Volts. Request a value of FBFh...";
CM_ SG_ 2566596094 MtGt4IvtLtsRqstDSdCtMx "Motor/Generator 4 Inverter Limits Request DC Side Current Maximum: This is a request to the inverter to set a maximum DC Side Current limit for this device instance.Refer to SPN 11971 [Reference Current] to convert % to Amps. Request a value of FBFh ...";
CM_ SG_ 2566596094 MtGt4IvtLtsRqstDSdCtM "Motor/Generator 4 Inverter Limits Request DC Side Current Minimum: This is a request to the inverter to set a minimum DC Side Current limit for this device instance.Refer to SPN 11971 [Reference Current] to convert % to Amps. Request a value of FBFh ...";
CM_ BO_ 2566596350 "Motor/Generator 4 Inverter Isolation Integrity Request";
CM_ SG_ 2566596350 MtGt4IvtHVtBsAtvIstTstCd "Motor/Generator 4 Inverter High-Voltage Bus Active Isolation Test Command: Command for the inverter to perform an active electrical isolation test on the high voltage bus.An active isolation test might use a generated signal (e.g. an injected AC sign...";
CM_ SG_ 2566596350 MtGt4IvtHVtBsPssvIstTstCd "Motor/Generator 4 Inverter High-Voltage Bus Passive Isolation Test Command: Command for the inverter to perform a passive electrical isolation test on the high voltage bus.A passive isolation test uses additional circuitry (e.g. a high impedance netw...";
CM_ SG_ 2566596350 MtGt4IvtHVtBsHSdRsstCtRqst "Motor/Generator 4 Inverter High-Voltage Bus High Side Resistor Connect Request: This parameter is used to request connection of the inverter High-Voltage bus high side resistor in order to perform an isolation test. 00b = Connection not Requested01b ...";
CM_ SG_ 2566596350 MtGt4IvtHVtBsLwSdRsstCtRqst "Motor/Generator 4 Inverter High-Voltage Bus Low Side Resistor Connect Request: This parameter is used to request connection of the inverter High-Voltage bus low side resistor in order to perform an isolation test.  00b = Connection not Requested01b =...";
CM_ BO_ 2365270014 "Motor/Generator 3 Inverter Control 2";
CM_ SG_ 2365270014 MtrGnrtr3InvrtrRtLmtsRqst2Cntr "Motor/Generator 3 Inverter Rate Limits Request 2 Counter: The message counter is used to detect situations where the transmitting ECU malfunction repeats the same frame all the time. The receiver of the information may use the counter parameter to de...";
CM_ SG_ 2365270014 MtrGnrtr3InvrtrRtLmtsRqst2Cr "Motor/Generator 3 Inverter Rate Limits Request 2 CRC: The CRC is defined as follows: - Length: 8 bits- Polynomial: x^8+x^5+x^3+x^2+x+1- Initial Value: FFh- Input Data Reflection: Not reflected- Result Data Reflection: Not reflected- XOR value: FFh SA...";
CM_ SG_ 2365270014 MtrGnrtr3InvrtrPdCntrlAppllMd "Motor/Generator 3 Inverter PID Control Applicable Mode : Defines the Mode for which the PID Gain parameters apply within this instance of the inverter. See SPN 11818 [Control Setpoint Mode] for a definition of modes for control purposes.Applicable mo...";
CM_ SG_ 2365270014 MtGt3IvtPdCtNzdDtG "Motor/Generator 3 Inverter PID Control Normalized Differential Gain: A PID controller can be parametrized by factors Kp, Ki and Kd. This parameter defines the normalized integral gain (Kin) for control applications in this inverter instance. The norm...";
CM_ SG_ 2365270014 MtGt3IvtPdCtNzdItG "Motor/Generator 3 Inverter PID Control Normalized Integral Gain: A PID controller can be parametrized by factors Kp, Ki and Kd. This parameter defines the normalized integral gain (Kin) for control applications in this inverter instance. The normaliz...";
CM_ SG_ 2365270014 MtGt3IvtPdCtNzdPptG "Motor/Generator 3 Inverter PID Control Normalized Proportional Gain: A PID controller can be parametrized by factors Kp, Ki and Kd. This parameter defines the normalized proportional gain (Kpn) for control applications in this inverter instance. The ...";
CM_ SG_ 2365270014 MtGt3IvtPdCtFdFwdTq "Motor/Generator 3 Inverter PID Control Feed-Forward Torque: A PID controller can have a Feed-Forward Torque added to its output. This parameter defines the Feed-Forward Torque Setpoint for control applications in this inverter instance. The Setpoint ...";
CM_ BO_ 2566596862 "Motor/Generator 3 Inverter Limits Request Power";
CM_ SG_ 2566596862 MtrGnrtr3InvrtrLmtsRqstPwrCntr "Motor/Generator 3 Inverter Limits Request Power Counter: The message counter is used to detect situations where the transmitting ECU malfunction repeats the same frame all the time. The receiver of the information may use the counter parameter to det...";
CM_ SG_ 2566596862 MtGt3IvtLtsRqstMPwMx "Motor/Generator 3 Inverter Limits Request Mechanical Power Maximum: This requests a maximum limit for the mechanical power.Refer to SPN 11823 [Reference Power] to convert % to kW. Request a value of FBFh to instruct the inverter to use its default va...";
CM_ SG_ 2566596862 MtGt3IvtLtsRqstMPwM "Motor/Generator 3 Inverter Limits Request Mechanical Power Minimum: This requests a minimum limit for the mechanical power.Refer to SPN 11823 [Reference Power] to convert % to kW. Request a value of FBFh to instruct the inverter to use its default va...";
CM_ SG_ 2566596862 MtrGnrtr3InvrtrLmtsRqstPwrCr "Motor/Generator 3 Inverter Limits Request Power CRC: The CRC is defined as follows: - Length: 8 bits- Polynomial: x^8+x^5+x^3+x^2+x+1- Initial Value: FFh- Input Data Reflection: Not reflected- Result Data Reflection: Not reflected- XOR value: FFh SAE...";
CM_ SG_ 2566596862 MtGt3IvtLtsRqstDSdPwMx "Motor/Generator 3 Inverter Limits Request DC Side Power Maximum: This requests a maximum limit for the DC Side power.Refer to SPN 11823 [Reference Power] to convert % to kW. Request a value of FBFh to instruct the inverter to use its default values.F...";
CM_ SG_ 2566596862 MtGt3IvtLtsRqstDSdPwM "Motor/Generator 3 Inverter Limits Request DC Side Power Minimum: This requests a minimum limit for the DC Side power.Refer to SPN 11823 [Reference Power] to convert % to kW. Request a value of FBFh to instruct the inverter to use its default values.F...";
CM_ BO_ 2566597118 "Motor/Generator 3 Inverter Limits Request Mechanical";
CM_ SG_ 2566597118 MtrGnrtr3InvrtrLmtsRqstMhnlCntr "Motor/Generator 3 Inverter Limits Request Mechanical Counter: The message counter is used to detect situations where the transmitting ECU malfunction repeats the same frame all the time. The receiver of the information may use the counter parameter t...";
CM_ SG_ 2566597118 MtrGnrtr3InvrtrLmtsRqstTrqMxmm "Motor/Generator 3 Inverter Limits Request Torque Maximum: This requests a maximum torque the inverter should command for this device.Refer to SPN 11821 [Reference Torque] to convert % to Nm. Request a value of FBFh to instruct the inverter to use its...";
CM_ SG_ 2566597118 MtrGnrtr3InvrtrLmtsRqstTrqMnmm "Motor/Generator 3 Inverter Limits Request Torque Minimum: This requests a minimum torque the inverter should command for this device.Refer to SPN 11821 [Reference Torque] to convert % to Nm. Request a value of FBFh to instruct the inverter to use its...";
CM_ SG_ 2566597118 MtrGnrtr3InvrtrLmtsRqstSpdMxmm "Motor/Generator 3 Inverter Limits Request Speed Maximum: This is a request to the inverter to set a maximum speed limit for this device.Refer to SPN 11822 [Reference Speed] to convert % to rpm. Request a value of FBFh to instruct the inverter to use ...";
CM_ SG_ 2566597118 MtrGnrtr3InvrtrLmtsRqstSpdMnmm "Motor/Generator 3 Inverter Limits Request Speed Minimum: This is a request to the inverter to set a minimum speed limit for this device.Refer to SPN 11822 [Reference Speed] to convert % to rpm. Request a value of FBFh to instruct the inverter to use ...";
CM_ SG_ 2566597118 MtrGnrtr3InvrtrLmtsRqstMhnlCr "Motor/Generator 3 Inverter Limits Request Mechanical CRC: The CRC is defined as follows: - Length: 8 bits- Polynomial: x^8+x^5+x^3+x^2+x+1- Initial Value: FFh- Input Data Reflection: Not reflected- Result Data Reflection: Not reflected- XOR value: FF...";
CM_ BO_ 2566597374 "Motor/Generator 3 Inverter Limits Request DC Side";
CM_ SG_ 2566597374 MtrGnrtr3InvrtrLmtsRqstDSdCr "Motor/Generator 3 Inverter Limits Request DC Side CRC: The CRC is defined as follows: - Length: 8 bits- Polynomial: x^8+x^5+x^3+x^2+x+1- Initial Value: FFh- Input Data Reflection: Not reflected- Result Data Reflection: Not reflected- XOR value: FFh S...";
CM_ SG_ 2566597374 MtrGnrtr3InvrtrLmtsRqstDSdCntr "Motor/Generator 3 Inverter Limits Request DC Side Counter: The message counter is used to detect situations where the transmitting ECU malfunction repeats the same frame all the time. The receiver of the information may use the counter parameter to d...";
CM_ SG_ 2566597374 MtGt3IvtLtsRqstDSdVtMx "Motor/Generator 3 Inverter Limits Request DC Side Voltage Maximum: This is a request to the inverter to set a maximum DC Side Voltage limit for this device instance.Refer to SPN 11854 [Reference Voltage] to convert % to Volts. Request a value of FBFh...";
CM_ SG_ 2566597374 MtGt3IvtLtsRqstDSdVtM "Motor/Generator 3 Inverter Limits Request DC Side Voltage Minimum: This is a request to the inverter to set a minimum DC Side Voltage limit for this device instance.Refer to SPN 11854 [Reference Voltage] to convert % to Volts. Request a value of FBFh...";
CM_ SG_ 2566597374 MtGt3IvtLtsRqstDSdCtMx "Motor/Generator 3 Inverter Limits Request DC Side Current Maximum: This is a request to the inverter to set a maximum DC Side Current limit for this device instance.Refer to SPN 11853 [Reference Current] to convert % to Amps. Request a value of FBFh ...";
CM_ SG_ 2566597374 MtGt3IvtLtsRqstDSdCtM "Motor/Generator 3 Inverter Limits Request DC Side Current Minimum: This is a request to the inverter to set a minimum DC Side Current limit for this device instance.Refer to SPN 11853 [Reference Current] to convert % to Amps. Request a value of FBFh ...";
CM_ BO_ 2566597630 "Motor/Generator 3 Inverter Isolation Integrity Request";
CM_ SG_ 2566597630 MtGt3IvtHVtBsAtvIstTstCd "Motor/Generator 3 Inverter High-Voltage Bus Active Isolation Test Command: Command for the inverter to perform an active electrical isolation test on the high voltage bus.An active isolation test might use a generated signal (e.g. an injected AC sign...";
CM_ SG_ 2566597630 MtGt3IvtHVtBsPssvIstTstCd "Motor/Generator 3 Inverter High-Voltage Bus Passive Isolation Test Command: Command for the inverter to perform a passive electrical isolation test on the high voltage bus.A passive isolation test uses additional circuitry (e.g. a high impedance netw...";
CM_ SG_ 2566597630 MtGt3IvtHVtBsHSdRsstCtRqst "Motor/Generator 3 Inverter High-Voltage Bus High Side Resistor Connect Request: This parameter is used to request connection of the inverter High-Voltage bus high side resistor in order to perform an isolation test. 00b = Connection not Requested01b ...";
CM_ SG_ 2566597630 MtGt3IvtHVtBsLwSdRsstCtRqst "Motor/Generator 3 Inverter High-Voltage Bus Low Side Resistor Connect Request: This parameter is used to request connection of the inverter High-Voltage bus low side resistor in order to perform an isolation test.  00b = Connection not Requested01b =...";
CM_ BO_ 2566598142 "Turbocharger Information 8";
CM_ SG_ 2566598142 EngineTurbocharger5Speed "Engine Turbocharger 5 Speed: Rotational velocity of rotor in the turbocharger.";
CM_ SG_ 2566598142 EngineTurbocharger6Speed "Engine Turbocharger 6 Speed: Rotational velocity of rotor in the turbocharger.";
CM_ SG_ 2566598142 EngnTrhrgr5CmprssrIntkPrssr "Engine Turbocharger 5 Compressor Intake Pressure: Gage pressure of the air entering the compressor side of the turbocharger.";
CM_ SG_ 2566598142 EngnTrhrgr6CmprssrIntkPrssr "Engine Turbocharger 6 Compressor Intake Pressure: Gage pressure of the air entering the compressor side of the turbocharger.";
CM_ BO_ 2566598398 "Winch Information 2";
CM_ SG_ 2566598398 WinchLifetimeRevolutionCounter "Winch Lifetime Revolution Counter: Accumulated number of revolutions of winch motor during its operation. This includes both forward and reverse directions and may be used for maintenance purposes.";
CM_ BO_ 2365272062 "Motor/Generator 6 Inverter Reference 1";
CM_ SG_ 2365272062 MtrGnrtr6InvrtrRfrn1Cntr "Motor/Generator 6 Inverter Reference 1 Counter: The message counter is used to detect situations where the transmitting ECU malfunction repeats the same frame all the time. The receiver of the information may use the counter parameter to detect this ...";
CM_ SG_ 2365272062 MtrGnrtr6InvrtrRfrnTrq "Motor/Generator 6 Inverter Reference Torque: This value is used for converting torque in percent to units of Nm.Value in Nm = (Percent Value)/(100%) * (Reference Torque)For example, if this parameter has a value of 400 Nm and the percent value is equ...";
CM_ SG_ 2365272062 MtrGnrtr6InvrtrRfrnSpd "Motor/Generator 6 Inverter Reference Speed: This value is used for converting Speed in percent to units of rpm.Value in rpm = (Percent Value)/(100%) * (Reference Speed)For example, if this parameter has a value of 8192 rpm and the percent value is eq...";
CM_ SG_ 2365272062 MtrGnrtr6InvrtrRfrnPwr "Motor/Generator 6 Inverter Reference Power: This value is used for converting power in percent to units of kW.  It is applicable to both mechanical and electrical power.(Value in kW) = (Percent Value)/(100%) * (Reference Power)For example, if this pa...";
CM_ SG_ 2365272062 MtrGnrtr6InvrtrRfrn1Cr "Motor/Generator 6 Inverter Reference 1 CRC: The CRC is defined as follows: - Length: 8 bits- Polynomial: x^8+x^5+x^3+x^2+x+1- Initial Value: FFh- Input Data Reflection: Not reflected- Result Data Reflection: Not reflected- XOR value: FFh SAE makes no...";
CM_ BO_ 2365272318 "Motor/Generator 6 Inverter Status 1";
CM_ SG_ 2365272318 MtrGnrtr6InvrtrStts1Cntr "Motor/Generator 6 Inverter Status 1 Counter: The message counter is used to detect situations where the transmitting ECU malfunction repeats the same frame all the time. The receiver of the information may use the counter parameter to detect this sit...";
CM_ SG_ 2365272318 MotorGenerator6Torque "Motor/Generator 6 Torque: The measured or estimated motor torque.  This refers to the motor rotor output and excludes any gearbox that may be attached to the motor.Refer to SPN 12175 [Reference Torque] to convert % to Nm.The motor is generating when ...";
CM_ SG_ 2365272318 MotorGenerator6Speed "Motor/Generator 6 Speed: The measured or estimated motor speed.  This refers to the motor rotor output and excludes any gearbox that may be attached to the motor.   Refer to SPN 12176 [Reference Speed] to convert % to rpm.";
CM_ SG_ 2365272318 MtrGnrtr6InvrtrStts1Cr "Motor/Generator 6 Inverter Status 1 CRC: The CRC is defined as follows: - Length: 8 bits- Polynomial: x^8+x^5+x^3+x^2+x+1- Initial Value: FFh- Input Data Reflection: Not reflected- Result Data Reflection: Not reflected- XOR value: FFh SAE makes no cl...";
CM_ SG_ 2365272318 MtrGnrtr6InvrtrDSdCrrnt "Motor/Generator 6 Inverter DC Side Current: This is the DC side current of the inverter.Refer to SPN 12207 [Reference Current] to convert % to Amps.While motoring, the current is defined as positive.  For example, in a hybrid or EV propulsion system,...";
CM_ SG_ 2365272318 MtrGnrtr6InvrtrDSdVltg "Motor/Generator 6 Inverter DC Side Voltage: The measured or estimated DC side voltage.  Refer to SPN 12208 [Reference Voltage] to convert % to Volts.";
CM_ BO_ 2365272574 "Motor/Generator 6 Inverter Reference 2";
CM_ SG_ 2365272574 MtrGnrtr6InvrtrRfrn2Cntr "Motor/Generator 6 Inverter Reference 2 Counter: The message counter is used to detect situations where the transmitting ECU malfunction repeats the same frame all the time. The receiver of the information may use the counter parameter to detect this ...";
CM_ SG_ 2365272574 MtrGnrtr6InvrtrRfrnCrrnt "Motor/Generator 6 Inverter Reference Current: This value is used for converting inverter current in percent to units of Amps (RMS or DC).(Value in Amps) = (Percent Value)/(100%) * (Reference Current)For example, if this parameter has a value of 200 A...";
CM_ SG_ 2365272574 MtrGnrtr6InvrtrRfrnVltg "Motor/Generator 6 Inverter Reference Voltage: This value is used for converting inverter voltage in percent to units of Volts (RMS or DC).(Value in Volts) = (Percent Value)/(100%) * (Reference Voltage)For example, if this parameter has a value of 400...";
CM_ SG_ 2365272574 MtrGnrtr6InvrtrRfrn2Cr "Motor/Generator 6 Inverter Reference 2 CRC: The CRC is defined as follows: - Length: 8 bits- Polynomial: x^8+x^5+x^3+x^2+x+1- Initial Value: FFh- Input Data Reflection: Not reflected- Result Data Reflection: Not reflected- XOR value: FFh SAE makes no...";
CM_ BO_ 2566599422 "Motor/Generator 6 Inverter Temperature";
CM_ SG_ 2566599422 MtrGnrtr6InvrtrTmprtr1 "Motor/Generator 6 Inverter Temperature 1: The exact location of this temperature can be defined by the manufacturer.  It is intended to be located somewhere on the inverter. ";
CM_ SG_ 2566599422 MtrGnrtr6InvrtrTmprtr2 "Motor/Generator 6 Inverter Temperature 2: The exact location of this temperature can be defined by the manufacturer.  It is intended to be located somewhere on the inverter. ";
CM_ SG_ 2566599422 MtrGnrtr6InvrtrTmprtr3 "Motor/Generator 6 Inverter Temperature 3: The exact location of this temperature can be defined by the manufacturer.  It is intended to be located somewhere on the inverter. ";
CM_ SG_ 2566599422 MtrGnrtr6InvrtrTmprtr4 "Motor/Generator 6 Inverter Temperature 4: The exact location of this temperature can be defined by the manufacturer.  It is intended to be located somewhere on the inverter. ";
CM_ SG_ 2566599422 MtrGnrtr6InvrtrTmprtr5 "Motor/Generator 6 Inverter Temperature 5: The exact location of this temperature can be defined by the manufacturer. It is intended to be located somewhere on the inverter.";
CM_ BO_ 2566599678 "Motor/Generator 6 Inverter Motor Temperature";
CM_ SG_ 2566599678 MotorGenerator6Temperature1 "Motor/Generator 6 Temperature 1: The exact location of this temperature can be defined by the manufacturer.  It is intended to located somewhere on the motor.";
CM_ SG_ 2566599678 MotorGenerator6Temperature2 "Motor/Generator 6 Temperature 2: The exact location of this temperature can be defined by the manufacturer.  It is intended to located somewhere on the motor. ";
CM_ SG_ 2566599678 MotorGenerator6Temperature3 "Motor/Generator 6 Temperature 3: The exact location of this temperature can be defined by the manufacturer.  It is intended to located somewhere on the motor. ";
CM_ SG_ 2566599678 MotorGenerator6Temperature4 "Motor/Generator 6 Temperature 4: The exact location of this temperature can be defined by the manufacturer.  It is intended to located somewhere on the motor. ";
CM_ BO_ 2566599934 "Motor/Generator 6 Inverter Isolation Integrity";
CM_ SG_ 2566599934 MtrGnrtr6InvrtrIsltnIntgrtCntr "Motor/Generator 6 Inverter Isolation Integrity Counter: The message counter is used to detect situations where the transmitting ECU malfunction repeats the same frame all the time. The receiver of the information may use the counter parameter to dete...";
CM_ SG_ 2566599934 MtGt6IvtHVtBsAtvIstTstStts "Motor/Generator 6 Inverter High-Voltage Bus Active Isolation Test Status: Status of the high-voltage bus electrical active isolation test as performed by this instance of the Motor/Generator.0000b = No test requested / No test in process0001b = Test ...";
CM_ SG_ 2566599934 MtGt6IvtHVtBsPssvIstTstStts "Motor/Generator 6 Inverter High-Voltage Bus Passive Isolation Test Status: Status of the high-voltage bus electrical passive isolation test as performed by this instance of the Motor/Generator.0000b = No test requested / No test in process0001b = Tes...";
CM_ SG_ 2566599934 MtGt6IvtHVtBsAtvIstTstRsts "Motor/Generator 6 Inverter High-Voltage Bus Active Isolation Test Results: The isolation resistance that resulted from the High-Voltage Bus Active Isolation Test.See SPN 12239 [High-Voltage Bus Active Isolation Test Status] for test status and SPN 12...";
CM_ SG_ 2566599934 MtGt6IvtHVtBsPssvIstTstRsts "Motor/Generator 6 Inverter High-Voltage Bus Passive Isolation Test Results: The isolation resistance that resulted from the High-Voltage Bus Passive Isolation Test.See SPN 12240 [High-Voltage Bus Passive Isolation Test Status] for test status and SPN...";
CM_ SG_ 2566599934 MtrGnrtr6InvrtrIsltnIntgrtCr "Motor/Generator 6 Inverter Isolation Integrity CRC: The CRC is defined as follows: - Length: 8 bits- Polynomial: x^8+x^5+x^3+x^2+x+1- Initial Value: FFh- Input Data Reflection: Not reflected- Result Data Reflection: Not reflected- XOR value: FFh SAE ...";
CM_ SG_ 2566599934 MtGt6IvtDSdNtvTCsssGdVt "Motor/Generator 6 Inverter DC Side Negative to Chassis Ground Voltage: The voltage level of the high voltage DC side, as measured by the inverter between the negative side of the High Voltage DC Side input and the chassis of the inverter enclosure.  ...";
CM_ BO_ 2566600190 "Motor/Generator 6 Inverter Active Power Limits";
CM_ SG_ 2566600190 MtGt6IvtPwLtdDTUddRs "Motor/Generator 6 Inverter Power Limited due to Undefined Reason: Output power is being limited due to an undefined reason.00b = No power limit for this reason01b = Power limited for this reason10b = Error11b = Not Available";
CM_ SG_ 2566600190 MtGt6IvtPwLtdDTMPwMx "Motor/Generator 6 Inverter Power Limited due to Mechanical Power Maximum: Output power is being limited due to Mechanical Power (product of SPN 12157 [Torque] and SPN 12155 [Speed]) approaching or exceeding the SPN 12189 [Inverter Limits Active Mecha...";
CM_ SG_ 2566600190 MtGt6IvtPwLtdDTMPwM "Motor/Generator 6 Inverter Power Limited due to Mechanical Power Minimum: Output power is being limited due to Mechanical Power (product of SPN 12157 [Torque] and SPN 12155 [Speed]) approaching or falling below the SPN 12190 [Inverter Limits Active M...";
CM_ SG_ 2566600190 MtrGnrtr6InvrtrPwrLmtdDTTrqMxmm "Motor/Generator 6 Inverter Power Limited due to Torque Maximum: Output power is being limited due to SPN 12157 [Torque] approaching or exceeding the SPN 12201 [Inverter Limits Active Torque Maximum].00b = No power limit for this reason01b = Power lim...";
CM_ SG_ 2566600190 MtrGnrtr6InvrtrPwrLmtdDTTrqMnmm "Motor/Generator 6 Inverter Power Limited due to Torque Minimum: Output power is being limited due to SPN 12157 [Torque] approaching or falling below the SPN 12202 [Inverter Limits Active Torque Minimum].00b = No power limit for this reason01b = Power...";
CM_ SG_ 2566600190 MtrGnrtr6InvrtrPwrLmtdDTSpdMxmm "Motor/Generator 6 Inverter Power Limited due to Speed Maximum: Output power is being limited due to SPN 12155 [Speed] approaching or exceeding the SPN 12203 [Inverter Limits Active Speed Maximum].00b = No power limit for this reason01b = Power limite...";
CM_ SG_ 2566600190 MtrGnrtr6InvrtrPwrLmtdDTSpdMnmm "Motor/Generator 6 Inverter Power Limited due to Speed Minimum: Output power is being limited due to SPN 12155 [Speed] approaching or falling below the SPN 12204 [Inverter Limits Active Speed Minimum].00b = No power limit for this reason01b = Power li...";
CM_ SG_ 2566600190 MtGt6IvtPwLtdDTIvtTpt "Motor/Generator 6 Inverter Power Limited due to Inverter Temperature: Output power is being limited due to one or more inverter temperature(s), see SPNs 12221 through 12224 [Inverter Temperature 1-4] approaching or exceeding internally defined limit(...";
CM_ SG_ 2566600190 MtGt6IvtPwLtdDTMtTpt "Motor/Generator 6 Inverter Power Limited due to Motor Temperature: Output power is being limited due to one or more motor temperature(s), see SPNs 12156 and 12225 through 12227 [Motor Temperature 1-4] approaching or exceeding internally defined limit...";
CM_ SG_ 2566600190 MtGt6IvtPwLtdDTFtCdt "Motor/Generator 6 Inverter Power Limited Due to Fault Condition: Output power is being limited due to an fault condition that requires a torque limitation to prevent further damage (e.g. 'limp home mode').  For example, this could be in case of tempe...";
CM_ SG_ 2566600190 MtGt6IvtPwLtdDTAtvTqRtLt "Motor/Generator 6 Inverter Power Limited Due to Active Torque Rate Limit: Output power is being limited due to exceeding internally defined torque rate limit(s) or SPN 12261 [Inverter Rate Limits Request Absolute Torque Rate Limit].00b = No power lim...";
CM_ SG_ 2566600190 MtGt6IvtPwLtdDTAtvSpdRtLt "Motor/Generator 6 Inverter Power Limited Due to Active Speed Rate Limit: Output power is being limited due to exceeding internally defined speed rate limit(s) or SPN 12260 [Inverter Rate Limits Request Absolute Speed Rate Limit].00b = No power limit ...";
CM_ SG_ 2566600190 MtGt6IvtTqLtdDTMCtsts "Motor/Generator 6 Inverter Torque Limited Due to Machine Characteristics: Output torque is being limited due to SPN 12157 [Torque] approaching or exceeding a motor design characteristic.  For example, for permanent magnet machines, this would be in t...";
CM_ SG_ 2566600190 MtGt6IvtPwLtdDTDSdCtMx "Motor/Generator 6 Inverter Power Limited due to DC Side Current Maximum: Output power is being limited due to SPN 12180 [Inverter DC Side Current] approaching or exceeding the SPN 12219 [Inverter Limits Active DC Side Current Maximum].00b = No power ...";
CM_ SG_ 2566600190 MtGt6IvtPwLtdDTDSdCtM "Motor/Generator 6 Inverter Power Limited due to DC Side Current Minimum: Output power is being limited due to SPN 12180 [Inverter DC Side Current] approaching or falling below the SPN 12220 [Inverter Limits Active DC Side Current Minimum].00b = No po...";
CM_ SG_ 2566600190 MtGt6IvtPwLtdDTDSdVtMx "Motor/Generator 6 Inverter Power Limited due to DC Side Voltage Maximum: Output power is being limited due to SPN 12158 [Inverter DC Side Voltage] approaching or exceeding the SPN 12217 [Inverter Limits Active DC Side Voltage Maximum].00b = No power ...";
CM_ SG_ 2566600190 MtGt6IvtPwLtdDTDSdVtM "Motor/Generator 6 Inverter Power Limited due to DC Side Voltage Minimum: Output power is being limited due to SPN 12158 [Inverter DC Side Voltage] approaching or falling below the SPN 12218 [Inverter Limits Active DC Side Voltage Minimum].00b = No po...";
CM_ SG_ 2566600190 MtGt6IvtPwLtdDTDSdPwMx "Motor/Generator 6 Inverter Power Limited due to DC Side Power Maximum: Output power is being limited due to DC Side Power (product of SPN 12180 [Inverter DC Side Current] and SPN 12158 [Inverter DC Side Voltage]) approaching or exceeding the SPN 1219...";
CM_ SG_ 2566600190 MtGt6IvtPwLtdDTDSdPwM "Motor/Generator 6 Inverter Power Limited due to DC Side Power Minimum: Output power is being limited due to DC Side Power (product of SPN 12180 [Inverter DC Side Current] and SPN 12158 [Inverter DC Side Voltage]) approaching or falling below the SPN ...";
CM_ BO_ 2365273854 "Motor/Generator 5 Inverter Reference 1";
CM_ SG_ 2365273854 MtrGnrtr5InvrtrRfrn1Cntr "Motor/Generator 5 Inverter Reference 1 Counter: The message counter is used to detect situations where the transmitting ECU malfunction repeats the same frame all the time. The receiver of the information may use the counter parameter to detect this ...";
CM_ SG_ 2365273854 MtrGnrtr5InvrtrRfrnTrq "Motor/Generator 5 Inverter Reference Torque: This value is used for converting torque in percent to units of Nm.Value in Nm = (Percent Value)/(100%) * (Reference Torque)For example, if this parameter has a value of 400 Nm and the percent value is equ...";
CM_ SG_ 2365273854 MtrGnrtr5InvrtrRfrnSpd "Motor/Generator 5 Inverter Reference Speed: This value is used for converting Speed in percent to units of rpm.Value in rpm = (Percent Value)/(100%) * (Reference Speed)For example, if this parameter has a value of 8192 rpm and the percent value is eq...";
CM_ SG_ 2365273854 MtrGnrtr5InvrtrRfrnPwr "Motor/Generator 5 Inverter Reference Power: This value is used for converting power in percent to units of kW.  It is applicable to both mechanical and electrical power.(Value in kW) = (Percent Value)/(100%) * (Reference Power)For example, if this pa...";
CM_ SG_ 2365273854 MtrGnrtr5InvrtrRfrn1Cr "Motor/Generator 5 Inverter Reference 1 CRC: The CRC is defined as follows: - Length: 8 bits- Polynomial: x^8+x^5+x^3+x^2+x+1- Initial Value: FFh- Input Data Reflection: Not reflected- Result Data Reflection: Not reflected- XOR value: FFh SAE makes no...";
CM_ BO_ 2365274110 "Motor/Generator 5 Inverter Status 1";
CM_ SG_ 2365274110 MtrGnrtr5InvrtrStts1Cntr "Motor/Generator 5 Inverter Status 1 Counter: The message counter is used to detect situations where the transmitting ECU malfunction repeats the same frame all the time. The receiver of the information may use the counter parameter to detect this sit...";
CM_ SG_ 2365274110 MotorGenerator5Torque "Motor/Generator 5 Torque: The measured or estimated motor torque.  This refers to the motor rotor output and excludes any gearbox that may be attached to the motor.Refer to SPN 12057 [Reference Torque] to convert % to Nm.The motor is generating when ...";
CM_ SG_ 2365274110 MotorGenerator5Speed "Motor/Generator 5 Speed: The measured or estimated motor speed.  This refers to the motor rotor output and excludes any gearbox that may be attached to the motor.   Refer to SPN 12058 [Reference Speed] to convert % to rpm.";
CM_ SG_ 2365274110 MtrGnrtr5InvrtrStts1Cr "Motor/Generator 5 Inverter Status 1 CRC: The CRC is defined as follows: - Length: 8 bits- Polynomial: x^8+x^5+x^3+x^2+x+1- Initial Value: FFh- Input Data Reflection: Not reflected- Result Data Reflection: Not reflected- XOR value: FFh SAE makes no cl...";
CM_ SG_ 2365274110 MtrGnrtr5InvrtrDSdCrrnt "Motor/Generator 5 Inverter DC Side Current: This is the DC side current of the inverter.Refer to SPN 12089 [Reference Current] to convert % to Amps.While motoring, the current is defined as positive.  For example, in a hybrid or EV propulsion system,...";
CM_ SG_ 2365274110 MtrGnrtr5InvrtrDSdVltg "Motor/Generator 5 Inverter DC Side Voltage: The measured or estimated DC side voltage.  Refer to SPN 12090 [Reference Voltage] to convert % to Volts.";
CM_ BO_ 2365274366 "Motor/Generator 5 Inverter Reference 2";
CM_ SG_ 2365274366 MtrGnrtr5InvrtrRfrn2Cntr "Motor/Generator 5 Inverter Reference 2 Counter: The message counter is used to detect situations where the transmitting ECU malfunction repeats the same frame all the time. The receiver of the information may use the counter parameter to detect this ...";
CM_ SG_ 2365274366 MtrGnrtr5InvrtrRfrnCrrnt "Motor/Generator 5 Inverter Reference Current: This value is used for converting inverter current in percent to units of Amps (RMS or DC).(Value in Amps) = (Percent Value)/(100%) * (Reference Current)For example, if this parameter has a value of 200 A...";
CM_ SG_ 2365274366 MtrGnrtr5InvrtrRfrnVltg "Motor/Generator 5 Inverter Reference Voltage: This value is used for converting inverter voltage in percent to units of Volts (RMS or DC).(Value in Volts) = (Percent Value)/(100%) * (Reference Voltage)For example, if this parameter has a value of 400...";
CM_ SG_ 2365274366 MtrGnrtr5InvrtrRfrn2Cr "Motor/Generator 5 Inverter Reference 2 CRC: The CRC is defined as follows: - Length: 8 bits- Polynomial: x^8+x^5+x^3+x^2+x+1- Initial Value: FFh- Input Data Reflection: Not reflected- Result Data Reflection: Not reflected- XOR value: FFh SAE makes no...";
CM_ BO_ 2566601214 "Motor/Generator 5 Inverter Temperature";
CM_ SG_ 2566601214 MtrGnrtr5InvrtrTmprtr1 "Motor/Generator 5 Inverter Temperature 1: The exact location of this temperature can be defined by the manufacturer.  It is intended to be located somewhere on the inverter. ";
CM_ SG_ 2566601214 MtrGnrtr5InvrtrTmprtr2 "Motor/Generator 5 Inverter Temperature 2: The exact location of this temperature can be defined by the manufacturer.  It is intended to be located somewhere on the inverter. ";
CM_ SG_ 2566601214 MtrGnrtr5InvrtrTmprtr3 "Motor/Generator 5 Inverter Temperature 3: The exact location of this temperature can be defined by the manufacturer.  It is intended to be located somewhere on the inverter. ";
CM_ SG_ 2566601214 MtrGnrtr5InvrtrTmprtr4 "Motor/Generator 5 Inverter Temperature 4: The exact location of this temperature can be defined by the manufacturer.  It is intended to be located somewhere on the inverter. ";
CM_ SG_ 2566601214 MtrGnrtr5InvrtrTmprtr5 "Motor/Generator 5 Inverter Temperature 5: The exact location of this temperature can be defined by the manufacturer. It is intended to be located somewhere on the inverter.";
CM_ BO_ 2566601470 "Motor/Generator 5 Inverter Motor Temperature";
CM_ SG_ 2566601470 MotorGenerator5Temperature1 "Motor/Generator 5 Temperature 1: The exact location of this temperature can be defined by the manufacturer.  It is intended to located somewhere on the motor.";
CM_ SG_ 2566601470 MotorGenerator5Temperature2 "Motor/Generator 5 Temperature 2: The exact location of this temperature can be defined by the manufacturer.  It is intended to located somewhere on the motor. ";
CM_ SG_ 2566601470 MotorGenerator5Temperature3 "Motor/Generator 5 Temperature 3: The exact location of this temperature can be defined by the manufacturer.  It is intended to located somewhere on the motor. ";
CM_ SG_ 2566601470 MotorGenerator5Temperature4 "Motor/Generator 5 Temperature 4: The exact location of this temperature can be defined by the manufacturer.  It is intended to located somewhere on the motor. ";
CM_ BO_ 2566601726 "Motor/Generator 5 Inverter Isolation Integrity";
CM_ SG_ 2566601726 MtrGnrtr5InvrtrIsltnIntgrtCntr "Motor/Generator 5 Inverter Isolation Integrity Counter: The message counter is used to detect situations where the transmitting ECU malfunction repeats the same frame all the time. The receiver of the information may use the counter parameter to dete...";
CM_ SG_ 2566601726 MtGt5IvtHVtBsAtvIstTstStts "Motor/Generator 5 Inverter High-Voltage Bus Active Isolation Test Status: Status of the high-voltage bus electrical active isolation test as performed by this instance of the Motor/Generator.0000b = No test requested / No test in process0001b = Test ...";
CM_ SG_ 2566601726 MtGt5IvtHVtBsPssvIstTstStts "Motor/Generator 5 Inverter High-Voltage Bus Passive Isolation Test Status: Status of the high-voltage bus electrical passive isolation test as performed by this instance of the Motor/Generator.0000b = No test requested / No test in process0001b = Tes...";
CM_ SG_ 2566601726 MtGt5IvtHVtBsAtvIstTstRsts "Motor/Generator 5 Inverter High-Voltage Bus Active Isolation Test Results: The isolation resistance that resulted from the High-Voltage Bus Active Isolation Test.See SPN 12121 [High-Voltage Bus Active Isolation Test Status] for test status and SPN 12...";
CM_ SG_ 2566601726 MtGt5IvtHVtBsPssvIstTstRsts "Motor/Generator 5 Inverter High-Voltage Bus Passive Isolation Test Results: The isolation resistance that resulted from the High-Voltage Bus Passive Isolation Test.See SPN 12122 [High-Voltage Bus Passive Isolation Test Status] for test status and SPN...";
CM_ SG_ 2566601726 MtrGnrtr5InvrtrIsltnIntgrtCr "Motor/Generator 5 Inverter Isolation Integrity CRC: The CRC is defined as follows: - Length: 8 bits- Polynomial: x^8+x^5+x^3+x^2+x+1- Initial Value: FFh- Input Data Reflection: Not reflected- Result Data Reflection: Not reflected- XOR value: FFh SAE ...";
CM_ SG_ 2566601726 MtGt5IvtDSdNtvTCsssGdVt "Motor/Generator 5 Inverter DC Side Negative to Chassis Ground Voltage: The voltage level of the high voltage DC side, as measured by the inverter between the negative side of the High Voltage DC Side input and the chassis of the inverter enclosure.  ...";
CM_ BO_ 2566601982 "Motor/Generator 5 Inverter Active Power Limits";
CM_ SG_ 2566601982 MtGt5IvtPwLtdDTUddRs "Motor/Generator 5 Inverter Power Limited due to Undefined Reason: Output power is being limited due to an undefined reason.00b = No power limit for this reason01b = Power limited for this reason10b = Error11b = Not Available";
CM_ SG_ 2566601982 MtGt5IvtPwLtdDTMPwMx "Motor/Generator 5 Inverter Power Limited due to Mechanical Power Maximum: Output power is being limited due to Mechanical Power (product of SPN 12039 [Torque] and SPN 12037 [Speed]) approaching or exceeding the SPN 12071 [Inverter Limits Active Mecha...";
CM_ SG_ 2566601982 MtGt5IvtPwLtdDTMPwM "Motor/Generator 5 Inverter Power Limited due to Mechanical Power Minimum: Output power is being limited due to Mechanical Power (product of SPN 12039 [Torque] and SPN 12037 [Speed]) approaching or falling below the SPN 12072 [Inverter Limits Active M...";
CM_ SG_ 2566601982 MtrGnrtr5InvrtrPwrLmtdDTTrqMxmm "Motor/Generator 5 Inverter Power Limited due to Torque Maximum: Output power is being limited due to SPN 12039 [Torque] approaching or exceeding the SPN 12083 [Inverter Limits Active Torque Maximum].00b = No power limit for this reason01b = Power lim...";
CM_ SG_ 2566601982 MtrGnrtr5InvrtrPwrLmtdDTTrqMnmm "Motor/Generator 5 Inverter Power Limited due to Torque Minimum: Output power is being limited due to SPN 12039 [Torque] approaching or falling below the SPN 12084 [Inverter Limits Active Torque Minimum].00b = No power limit for this reason01b = Power...";
CM_ SG_ 2566601982 MtrGnrtr5InvrtrPwrLmtdDTSpdMxmm "Motor/Generator 5 Inverter Power Limited due to Speed Maximum: Output power is being limited due to SPN 12037 [Speed] approaching or exceeding the SPN 12085 [Inverter Limits Active Speed Maximum].00b = No power limit for this reason01b = Power limite...";
CM_ SG_ 2566601982 MtrGnrtr5InvrtrPwrLmtdDTSpdMnmm "Motor/Generator 5 Inverter Power Limited due to Speed Minimum: Output power is being limited due to SPN 12037 [Speed] approaching or falling below the SPN 12086 [Inverter Limits Active Speed Minimum].00b = No power limit for this reason01b = Power li...";
CM_ SG_ 2566601982 MtGt5IvtPwLtdDTIvtTpt "Motor/Generator 5 Inverter Power Limited due to Inverter Temperature: Output power is being limited due to one or more inverter temperature(s), see SPNs 12103 through 12106 [Inverter Temperature 1-4] approaching or exceeding internally defined limit(...";
CM_ SG_ 2566601982 MtGt5IvtPwLtdDTMtTpt "Motor/Generator 5 Inverter Power Limited due to Motor Temperature: Output power is being limited due to one or more motor temperature(s), see SPNs 12038 and 12107 through 12109 [Motor Temperature 1-4] approaching or exceeding internally defined limit...";
CM_ SG_ 2566601982 MtGt5IvtPwLtdDTFtCdt "Motor/Generator 5 Inverter Power Limited Due to Fault Condition: Output power is being limited due to an fault condition that requires a torque limitation to prevent further damage (e.g. 'limp home mode').  For example, this could be in case of tempe...";
CM_ SG_ 2566601982 MtGt5IvtPwLtdDTAtvTqRtLt "Motor/Generator 5 Inverter Power Limited Due to Active Torque Rate Limit: Output power is being limited due to exceeding internally defined torque rate limit(s) or SPN 12143 [Inverter Rate Limits Request Absolute Torque Rate Limit].00b = No power lim...";
CM_ SG_ 2566601982 MtGt5IvtPwLtdDTAtvSpdRtLt "Motor/Generator 5 Inverter Power Limited Due to Active Speed Rate Limit: Output power is being limited due to exceeding internally defined speed rate limit(s) or SPN 12142 [Inverter Rate Limits Request Absolute Speed Rate Limit].00b = No power limit ...";
CM_ SG_ 2566601982 MtGt5IvtTqLtdDTMCtsts "Motor/Generator 5 Inverter Torque Limited Due to Machine Characteristics: Output torque is being limited due to SPN 12039 [Torque] approaching or exceeding a motor design characteristic.  For example, for permanent magnet machines, this would be in t...";
CM_ SG_ 2566601982 MtGt5IvtPwLtdDTDSdCtMx "Motor/Generator 5 Inverter Power Limited due to DC Side Current Maximum: Output power is being limited due to SPN 12062 [Inverter DC Side Current] approaching or exceeding the SPN 12101 [Inverter Limits Active DC Side Current Maximum].00b = No power ...";
CM_ SG_ 2566601982 MtGt5IvtPwLtdDTDSdCtM "Motor/Generator 5 Inverter Power Limited due to DC Side Current Minimum: Output power is being limited due to SPN 12062 [Inverter DC Side Current] approaching or falling below the SPN 12102 [Inverter Limits Active DC Side Current Minimum].00b = No po...";
CM_ SG_ 2566601982 MtGt5IvtPwLtdDTDSdVtMx "Motor/Generator 5 Inverter Power Limited due to DC Side Voltage Maximum: Output power is being limited due to SPN 12040 [Inverter DC Side Voltage] approaching or exceeding the SPN 12099 [Inverter Limits Active DC Side Voltage Maximum].00b = No power ...";
CM_ SG_ 2566601982 MtGt5IvtPwLtdDTDSdVtM "Motor/Generator 5 Inverter Power Limited due to DC Side Voltage Minimum: Output power is being limited due to SPN 12040 [Inverter DC Side Voltage] approaching or falling below the SPN 12100 [Inverter Limits Active DC Side Voltage Minimum].00b = No po...";
CM_ SG_ 2566601982 MtGt5IvtPwLtdDTDSdPwMx "Motor/Generator 5 Inverter Power Limited due to DC Side Power Maximum: Output power is being limited due to DC Side Power (product of SPN 12062 [Inverter DC Side Current] and SPN 12040 [Inverter DC Side Voltage]) approaching or exceeding the SPN 1207...";
CM_ SG_ 2566601982 MtGt5IvtPwLtdDTDSdPwM "Motor/Generator 5 Inverter Power Limited due to DC Side Power Minimum: Output power is being limited due to DC Side Power (product of SPN 12062 [Inverter DC Side Current] and SPN 12040 [Inverter DC Side Voltage]) approaching or falling below the SPN ...";
CM_ BO_ 2365275646 "Motor/Generator 4 Inverter Reference 1";
CM_ SG_ 2365275646 MtrGnrtr4InvrtrRfrn1Cntr "Motor/Generator 4 Inverter Reference 1 Counter: The message counter is used to detect situations where the transmitting ECU malfunction repeats the same frame all the time. The receiver of the information may use the counter parameter to detect this ...";
CM_ SG_ 2365275646 MtrGnrtr4InvrtrRfrnTrq "Motor/Generator 4 Inverter Reference Torque: This value is used for converting torque in percent to units of Nm.Value in Nm = (Percent Value)/(100%) * (Reference Torque)For example, if this parameter has a value of 400 Nm and the percent value is equ...";
CM_ SG_ 2365275646 MtrGnrtr4InvrtrRfrnSpd "Motor/Generator 4 Inverter Reference Speed: This value is used for converting Speed in percent to units of rpm.Value in rpm = (Percent Value)/(100%) * (Reference Speed)For example, if this parameter has a value of 8192 rpm and the percent value is eq...";
CM_ SG_ 2365275646 MtrGnrtr4InvrtrRfrnPwr "Motor/Generator 4 Inverter Reference Power: This value is used for converting power in percent to units of kW.  It is applicable to both mechanical and electrical power.(Value in kW) = (Percent Value)/(100%) * (Reference Power)For example, if this pa...";
CM_ SG_ 2365275646 MtrGnrtr4InvrtrRfrn1Cr "Motor/Generator 4 Inverter Reference 1 CRC: The CRC is defined as follows: - Length: 8 bits- Polynomial: x^8+x^5+x^3+x^2+x+1- Initial Value: FFh- Input Data Reflection: Not reflected- Result Data Reflection: Not reflected- XOR value: FFh SAE makes no...";
CM_ BO_ 2365275902 "Motor/Generator 4 Inverter Status 1";
CM_ SG_ 2365275902 MtrGnrtr4InvrtrStts1Cntr "Motor/Generator 4 Inverter Status 1 Counter: The message counter is used to detect situations where the transmitting ECU malfunction repeats the same frame all the time. The receiver of the information may use the counter parameter to detect this sit...";
CM_ SG_ 2365275902 MotorGenerator4Torque "Motor/Generator 4 Torque: The measured or estimated motor torque.  This refers to the motor rotor output and excludes any gearbox that may be attached to the motor.Refer to SPN 11939 [Reference Torque] to convert % to Nm.The motor is generating when ...";
CM_ SG_ 2365275902 MotorGenerator4Speed "Motor/Generator 4 Speed: The measured or estimated motor speed.  This refers to the motor rotor output and excludes any gearbox that may be attached to the motor.   Refer to SPN 11940 [Reference Speed] to convert % to rpm.";
CM_ SG_ 2365275902 MtrGnrtr4InvrtrStts1Cr "Motor/Generator 4 Inverter Status 1 CRC: The CRC is defined as follows: - Length: 8 bits- Polynomial: x^8+x^5+x^3+x^2+x+1- Initial Value: FFh- Input Data Reflection: Not reflected- Result Data Reflection: Not reflected- XOR value: FFh SAE makes no cl...";
CM_ SG_ 2365275902 MtrGnrtr4InvrtrDSdCrrnt "Motor/Generator 4 Inverter DC Side Current: This is the DC side current of the inverter.Refer to SPN 11971 [Reference Current] to convert % to Amps.While motoring, the current is defined as positive.  For example, in a hybrid or EV propulsion system,...";
CM_ SG_ 2365275902 MtrGnrtr4InvrtrDSdVltg "Motor/Generator 4 Inverter DC Side Voltage: The measured or estimated DC side voltage.  Refer to SPN 11972 [Reference Voltage] to convert % to Volts.";
CM_ BO_ 2365276158 "Motor/Generator 4 Inverter Reference 2";
CM_ SG_ 2365276158 MtrGnrtr4InvrtrRfrn2Cntr "Motor/Generator 4 Inverter Reference 2 Counter: The message counter is used to detect situations where the transmitting ECU malfunction repeats the same frame all the time. The receiver of the information may use the counter parameter to detect this ...";
CM_ SG_ 2365276158 MtrGnrtr4InvrtrRfrnCrrnt "Motor/Generator 4 Inverter Reference Current: This value is used for converting inverter current in percent to units of Amps (RMS or DC).(Value in Amps) = (Percent Value)/(100%) * (Reference Current)For example, if this parameter has a value of 200 A...";
CM_ SG_ 2365276158 MtrGnrtr4InvrtrRfrnVltg "Motor/Generator 4 Inverter Reference Voltage: This value is used for converting inverter voltage in percent to units of Volts (RMS or DC).(Value in Volts) = (Percent Value)/(100%) * (Reference Voltage)For example, if this parameter has a value of 400...";
CM_ SG_ 2365276158 MtrGnrtr4InvrtrRfrn2Cr "Motor/Generator 4 Inverter Reference 2 CRC: The CRC is defined as follows: - Length: 8 bits- Polynomial: x^8+x^5+x^3+x^2+x+1- Initial Value: FFh- Input Data Reflection: Not reflected- Result Data Reflection: Not reflected- XOR value: FFh SAE makes no...";
CM_ BO_ 2566603006 "Motor/Generator 4 Inverter Temperature";
CM_ SG_ 2566603006 MtrGnrtr4InvrtrTmprtr1 "Motor/Generator 4 Inverter Temperature 1: The exact location of this temperature can be defined by the manufacturer.  It is intended to be located somewhere on the inverter. ";
CM_ SG_ 2566603006 MtrGnrtr4InvrtrTmprtr2 "Motor/Generator 4 Inverter Temperature 2: The exact location of this temperature can be defined by the manufacturer.  It is intended to be located somewhere on the inverter. ";
CM_ SG_ 2566603006 MtrGnrtr4InvrtrTmprtr3 "Motor/Generator 4 Inverter Temperature 3: The exact location of this temperature can be defined by the manufacturer.  It is intended to be located somewhere on the inverter. ";
CM_ SG_ 2566603006 MtrGnrtr4InvrtrTmprtr4 "Motor/Generator 4 Inverter Temperature 4: The exact location of this temperature can be defined by the manufacturer.  It is intended to be located somewhere on the inverter. ";
CM_ SG_ 2566603006 MtrGnrtr4InvrtrTmprtr5 "Motor/Generator 4 Inverter Temperature 5: The exact location of this temperature can be defined by the manufacturer. It is intended to be located somewhere on the inverter.";
CM_ BO_ 2566603262 "Motor/Generator 4 Inverter Motor Temperature";
CM_ SG_ 2566603262 MotorGenerator4Temperature1 "Motor/Generator 4 Temperature 1: The exact location of this temperature can be defined by the manufacturer.  It is intended to located somewhere on the motor.";
CM_ SG_ 2566603262 MotorGenerator4Temperature2 "Motor/Generator 4 Temperature 2: The exact location of this temperature can be defined by the manufacturer.  It is intended to located somewhere on the motor. ";
CM_ SG_ 2566603262 MotorGenerator4Temperature3 "Motor/Generator 4 Temperature 3: The exact location of this temperature can be defined by the manufacturer.  It is intended to located somewhere on the motor. ";
CM_ SG_ 2566603262 MotorGenerator4Temperature4 "Motor/Generator 4 Temperature 4: The exact location of this temperature can be defined by the manufacturer.  It is intended to located somewhere on the motor. ";
CM_ BO_ 2566603518 "Motor/Generator 4 Inverter Isolation Integrity";
CM_ SG_ 2566603518 MtrGnrtr4InvrtrIsltnIntgrtCntr "Motor/Generator 4 Inverter Isolation Integrity Counter: The message counter is used to detect situations where the transmitting ECU malfunction repeats the same frame all the time. The receiver of the information may use the counter parameter to dete...";
CM_ SG_ 2566603518 MtGt4IvtHVtBsAtvIstTstStts "Motor/Generator 4 Inverter High-Voltage Bus Active Isolation Test Status: Status of the high-voltage bus electrical active isolation test as performed by this instance of the Motor/Generator.0000b = No test requested / No test in process0001b = Test ...";
CM_ SG_ 2566603518 MtGt4IvtHVtBsPssvIstTstStts "Motor/Generator 4 Inverter High-Voltage Bus Passive Isolation Test Status: Status of the high-voltage bus electrical passive isolation test as performed by this instance of the Motor/Generator.0000b = No test requested / No test in process0001b = Tes...";
CM_ SG_ 2566603518 MtGt4IvtHVtBsAtvIstTstRsts "Motor/Generator 4 Inverter High-Voltage Bus Active Isolation Test Results: The isolation resistance that resulted from the High-Voltage Bus Active Isolation Test.See SPN 12003 [High-Voltage Bus Active Isolation Test Status] for test status and SPN 11...";
CM_ SG_ 2566603518 MtGt4IvtHVtBsPssvIstTstRsts "Motor/Generator 4 Inverter High-Voltage Bus Passive Isolation Test Results: The isolation resistance that resulted from the High-Voltage Bus Passive Isolation Test.See SPN 12004 [High-Voltage Bus Passive Isolation Test Status] for test status and SPN...";
CM_ SG_ 2566603518 MtrGnrtr4InvrtrIsltnIntgrtCr "Motor/Generator 4 Inverter Isolation Integrity CRC: The CRC is defined as follows: - Length: 8 bits- Polynomial: x^8+x^5+x^3+x^2+x+1- Initial Value: FFh- Input Data Reflection: Not reflected- Result Data Reflection: Not reflected- XOR value: FFh SAE ...";
CM_ SG_ 2566603518 MtGt4IvtDSdNtvTCsssGdVt "Motor/Generator 4 Inverter DC Side Negative to Chassis Ground Voltage: The voltage level of the high voltage DC side, as measured by the inverter between the negative side of the High Voltage DC Side input and the chassis of the inverter enclosure.  ...";
CM_ BO_ 2566603774 "Motor/Generator 4 Inverter Active Power Limits";
CM_ SG_ 2566603774 MtGt4IvtPwLtdDTUddRs "Motor/Generator 4 Inverter Power Limited due to Undefined Reason: Output power is being limited due to an undefined reason.00b = No power limit for this reason01b = Power limited for this reason10b = Error11b = Not Available";
CM_ SG_ 2566603774 MtGt4IvtPwLtdDTMPwMx "Motor/Generator 4 Inverter Power Limited due to Mechanical Power Maximum: Output power is being limited due to Mechanical Power (product of SPN 11921 [Torque] and SPN 11919 [Speed]) approaching or exceeding the SPN 11953 [Inverter Limits Active Mecha...";
CM_ SG_ 2566603774 MtGt4IvtPwLtdDTMPwM "Motor/Generator 4 Inverter Power Limited due to Mechanical Power Minimum: Output power is being limited due to Mechanical Power (product of SPN 11921 [Torque] and SPN 11919 [Speed]) approaching or falling below the SPN 11954 [Inverter Limits Active M...";
CM_ SG_ 2566603774 MtrGnrtr4InvrtrPwrLmtdDTTrqMxmm "Motor/Generator 4 Inverter Power Limited due to Torque Maximum: Output power is being limited due to SPN 11921 [Torque] approaching or exceeding the SPN 11965 [Inverter Limits Active Torque Maximum].00b = No power limit for this reason01b = Power lim...";
CM_ SG_ 2566603774 MtrGnrtr4InvrtrPwrLmtdDTTrqMnmm "Motor/Generator 4 Inverter Power Limited due to Torque Minimum: Output power is being limited due to SPN 11921 [Torque] approaching or falling below the SPN 11966 [Inverter Limits Active Torque Minimum].00b = No power limit for this reason01b = Power...";
CM_ SG_ 2566603774 MtrGnrtr4InvrtrPwrLmtdDTSpdMxmm "Motor/Generator 4 Inverter Power Limited due to Speed Maximum: Output power is being limited due to SPN 11919 [Speed] approaching or exceeding the SPN 11967 [Inverter Limits Active Speed Maximum].00b = No power limit for this reason01b = Power limite...";
CM_ SG_ 2566603774 MtrGnrtr4InvrtrPwrLmtdDTSpdMnmm "Motor/Generator 4 Inverter Power Limited due to Speed Minimum: Output power is being limited due to SPN 11919 [Speed] approaching or falling below the SPN 11968 [Inverter Limits Active Speed Minimum].00b = No power limit for this reason01b = Power li...";
CM_ SG_ 2566603774 MtGt4IvtPwLtdDTIvtTpt "Motor/Generator 4 Inverter Power Limited due to Inverter Temperature: Output power is being limited due to one or more inverter temperature(s), see SPNs 11985 through 11988 [Inverter Temperature 1-4] approaching or exceeding internally defined limit(...";
CM_ SG_ 2566603774 MtGt4IvtPwLtdDTMtTpt "Motor/Generator 4 Inverter Power Limited due to Motor Temperature: Output power is being limited due to one or more motor temperature(s), see SPNs 11920 and 11989 through 11991 [Motor Temperature 1-4] approaching or exceeding internally defined limit...";
CM_ SG_ 2566603774 MtGt4IvtPwLtdDTFtCdt "Motor/Generator 4 Inverter Power Limited Due to Fault Condition: Output power is being limited due to an fault condition that requires a torque limitation to prevent further damage (e.g. 'limp home mode').  For example, this could be in case of tempe...";
CM_ SG_ 2566603774 MtGt4IvtPwLtdDTAtvTqRtLt "Motor/Generator 4 Inverter Power Limited Due to Active Torque Rate Limit: Output power is being limited due to exceeding internally defined torque rate limit(s) or SPN 12025 [Inverter Rate Limits Request Absolute Torque Rate Limit].00b = No power lim...";
CM_ SG_ 2566603774 MtGt4IvtPwLtdDTAtvSpdRtLt "Motor/Generator 4 Inverter Power Limited Due to Active Speed Rate Limit: Output power is being limited due to exceeding internally defined speed rate limit(s) or SPN 12024 [Inverter Rate Limits Request Absolute Speed Rate Limit].00b = No power limit ...";
CM_ SG_ 2566603774 MtGt4IvtTqLtdDTMCtsts "Motor/Generator 4 Inverter Torque Limited Due to Machine Characteristics: Output torque is being limited due to SPN 11921 [Torque] approaching or exceeding a motor design characteristic.  For example, for permanent magnet machines, this would be in t...";
CM_ SG_ 2566603774 MtGt4IvtPwLtdDTDSdCtMx "Motor/Generator 4 Inverter Power Limited due to DC Side Current Maximum: Output power is being limited due to SPN 11944 [Inverter DC Side Current] approaching or exceeding the SPN 11983 [Inverter Limits Active DC Side Current Maximum].00b = No power ...";
CM_ SG_ 2566603774 MtGt4IvtPwLtdDTDSdCtM "Motor/Generator 4 Inverter Power Limited due to DC Side Current Minimum: Output power is being limited due to SPN 11944 [Inverter DC Side Current] approaching or falling below the SPN 11984 [Inverter Limits Active DC Side Current Minimum].00b = No po...";
CM_ SG_ 2566603774 MtGt4IvtPwLtdDTDSdVtMx "Motor/Generator 4 Inverter Power Limited due to DC Side Voltage Maximum: Output power is being limited due to SPN 11922 [Inverter DC Side Voltage] approaching or exceeding the SPN 11981 [Inverter Limits Active DC Side Voltage Maximum].00b = No power ...";
CM_ SG_ 2566603774 MtGt4IvtPwLtdDTDSdVtM "Motor/Generator 4 Inverter Power Limited due to DC Side Voltage Minimum: Output power is being limited due to SPN 11922 [Inverter DC Side Voltage] approaching or falling below the SPN 11982 [Inverter Limits Active DC Side Voltage Minimum].00b = No po...";
CM_ SG_ 2566603774 MtGt4IvtPwLtdDTDSdPwMx "Motor/Generator 4 Inverter Power Limited due to DC Side Power Maximum: Output power is being limited due to DC Side Power (product of SPN 11944 [Inverter DC Side Current] and SPN 11922 [Inverter DC Side Voltage]) approaching or exceeding the SPN 1195...";
CM_ SG_ 2566603774 MtGt4IvtPwLtdDTDSdPwM "Motor/Generator 4 Inverter Power Limited due to DC Side Power Minimum: Output power is being limited due to DC Side Power (product of SPN 11944 [Inverter DC Side Current] and SPN 11922 [Inverter DC Side Voltage]) approaching or falling below the SPN ...";
CM_ BO_ 2365277438 "Motor/Generator 3 Inverter Reference 1";
CM_ SG_ 2365277438 MtrGnrtr3InvrtrRfrn1Cntr "Motor/Generator 3 Inverter Reference 1 Counter: The message counter is used to detect situations where the transmitting ECU malfunction repeats the same frame all the time. The receiver of the information may use the counter parameter to detect this ...";
CM_ SG_ 2365277438 MtrGnrtr3InvrtrRfrnTrq "Motor/Generator 3 Inverter Reference Torque: This value is used for converting torque in percent to units of Nm.Value in Nm = (Percent Value)/(100%) * (Reference Torque)For example, if this parameter has a value of 400 Nm and the percent value is equ...";
CM_ SG_ 2365277438 MtrGnrtr3InvrtrRfrnSpd "Motor/Generator 3 Inverter Reference Speed: This value is used for converting Speed in percent to units of rpm.Value in rpm = (Percent Value)/(100%) * (Reference Speed)For example, if this parameter has a value of 8192 rpm and the percent value is eq...";
CM_ SG_ 2365277438 MtrGnrtr3InvrtrRfrnPwr "Motor/Generator 3 Inverter Reference Power: This value is used for converting power in percent to units of kW.  It is applicable to both mechanical and electrical power.(Value in kW) = (Percent Value)/(100%) * (Reference Power)For example, if this pa...";
CM_ SG_ 2365277438 MtrGnrtr3InvrtrRfrn1Cr "Motor/Generator 3 Inverter Reference 1 CRC: The CRC is defined as follows: - Length: 8 bits- Polynomial: x^8+x^5+x^3+x^2+x+1- Initial Value: FFh- Input Data Reflection: Not reflected- Result Data Reflection: Not reflected- XOR value: FFh SAE makes no...";
CM_ BO_ 2365277694 "Motor/Generator 3 Inverter Status 1";
CM_ SG_ 2365277694 MtrGnrtr3InvrtrStts1Cntr "Motor/Generator 3 Inverter Status 1 Counter: The message counter is used to detect situations where the transmitting ECU malfunction repeats the same frame all the time. The receiver of the information may use the counter parameter to detect this sit...";
CM_ SG_ 2365277694 MotorGenerator3Torque "Motor/Generator 3 Torque: The measured or estimated motor torque.  This refers to the motor rotor output and excludes any gearbox that may be attached to the motor.Refer to SPN 11821 [Reference Torque] to convert % to Nm.The motor is generating when ...";
CM_ SG_ 2365277694 MotorGenerator3Speed "Motor/Generator 3 Speed: The measured or estimated motor speed.  This refers to the motor rotor output and excludes any gearbox that may be attached to the motor.   Refer to SPN 11822 [Reference Speed] to convert % to rpm.";
CM_ SG_ 2365277694 MtrGnrtr3InvrtrStts1Cr "Motor/Generator 3 Inverter Status 1 CRC: The CRC is defined as follows: - Length: 8 bits- Polynomial: x^8+x^5+x^3+x^2+x+1- Initial Value: FFh- Input Data Reflection: Not reflected- Result Data Reflection: Not reflected- XOR value: FFh SAE makes no cl...";
CM_ SG_ 2365277694 MtrGnrtr3InvrtrDSdCrrnt "Motor/Generator 3 Inverter DC Side Current: This is the DC side current of the inverter.Refer to SPN 11853 [Reference Current] to convert % to Amps.While motoring, the current is defined as positive.  For example, in a hybrid or EV propulsion system,...";
CM_ SG_ 2365277694 MtrGnrtr3InvrtrDSdVltg "Motor/Generator 3 Inverter DC Side Voltage: The measured or estimated DC side voltage.  Refer to SPN 11854 [Reference Voltage] to convert % to Volts.";
CM_ BO_ 2365277950 "Motor/Generator 3 Inverter Reference 2";
CM_ SG_ 2365277950 MtrGnrtr3InvrtrRfrn2Cntr "Motor/Generator 3 Inverter Reference 2 Counter: The message counter is used to detect situations where the transmitting ECU malfunction repeats the same frame all the time. The receiver of the information may use the counter parameter to detect this ...";
CM_ SG_ 2365277950 MtrGnrtr3InvrtrRfrnCrrnt "Motor/Generator 3 Inverter Reference Current: This value is used for converting inverter current in percent to units of Amps (RMS or DC).(Value in Amps) = (Percent Value)/(100%) * (Reference Current)For example, if this parameter has a value of 200 A...";
CM_ SG_ 2365277950 MtrGnrtr3InvrtrRfrnVltg "Motor/Generator 3 Inverter Reference Voltage: This value is used for converting inverter voltage in percent to units of Volts (RMS or DC).(Value in Volts) = (Percent Value)/(100%) * (Reference Voltage)For example, if this parameter has a value of 400...";
CM_ SG_ 2365277950 MtrGnrtr3InvrtrRfrn2Cr "Motor/Generator 3 Inverter Reference 2 CRC: The CRC is defined as follows: - Length: 8 bits- Polynomial: x^8+x^5+x^3+x^2+x+1- Initial Value: FFh- Input Data Reflection: Not reflected- Result Data Reflection: Not reflected- XOR value: FFh SAE makes no...";
CM_ BO_ 2566604798 "Motor/Generator 3 Inverter Temperature";
CM_ SG_ 2566604798 MtrGnrtr3InvrtrTmprtr1 "Motor/Generator 3 Inverter Temperature 1: The exact location of this temperature can be defined by the manufacturer.  It is intended to be located somewhere on the inverter. ";
CM_ SG_ 2566604798 MtrGnrtr3InvrtrTmprtr2 "Motor/Generator 3 Inverter Temperature 2: The exact location of this temperature can be defined by the manufacturer.  It is intended to be located somewhere on the inverter. ";
CM_ SG_ 2566604798 MtrGnrtr3InvrtrTmprtr3 "Motor/Generator 3 Inverter Temperature 3: The exact location of this temperature can be defined by the manufacturer.  It is intended to be located somewhere on the inverter. ";
CM_ SG_ 2566604798 MtrGnrtr3InvrtrTmprtr4 "Motor/Generator 3 Inverter Temperature 4: The exact location of this temperature can be defined by the manufacturer.  It is intended to be located somewhere on the inverter. ";
CM_ SG_ 2566604798 MtrGnrtr3InvrtrTmprtr5 "Motor/Generator 3 Inverter Temperature 5: The exact location of this temperature can be defined by the manufacturer. It is intended to be located somewhere on the inverter.";
CM_ BO_ 2566605054 "Motor/Generator 3 Inverter Motor Temperature";
CM_ SG_ 2566605054 MotorGenerator3Temperature1 "Motor/Generator 3 Temperature 1: The exact location of this temperature can be defined by the manufacturer.  It is intended to located somewhere on the motor.";
CM_ SG_ 2566605054 MotorGenerator3Temperature2 "Motor/Generator 3 Temperature 2: The exact location of this temperature can be defined by the manufacturer.  It is intended to located somewhere on the motor. ";
CM_ SG_ 2566605054 MotorGenerator3Temperature3 "Motor/Generator 3 Temperature 3: The exact location of this temperature can be defined by the manufacturer.  It is intended to located somewhere on the motor. ";
CM_ SG_ 2566605054 MotorGenerator3Temperature4 "Motor/Generator 3 Temperature 4: The exact location of this temperature can be defined by the manufacturer.  It is intended to located somewhere on the motor. ";
CM_ BO_ 2566605310 "Motor/Generator 3 Inverter Isolation Integrity";
CM_ SG_ 2566605310 MtrGnrtr3InvrtrIsltnIntgrtCntr "Motor/Generator 3 Inverter Isolation Integrity Counter: The message counter is used to detect situations where the transmitting ECU malfunction repeats the same frame all the time. The receiver of the information may use the counter parameter to dete...";
CM_ SG_ 2566605310 MtGt3IvtHVtBsAtvIstTstStts "Motor/Generator 3 Inverter High-Voltage Bus Active Isolation Test Status: Status of the high-voltage bus electrical active isolation test as performed by this instance of the Motor/Generator.0000b = No test requested / No test in process0001b = Test ...";
CM_ SG_ 2566605310 MtGt3IvtHVtBsPssvIstTstStts "Motor/Generator 3 Inverter High-Voltage Bus Passive Isolation Test Status: Status of the high-voltage bus electrical passive isolation test as performed by this instance of the Motor/Generator.0000b = No test requested / No test in process0001b = Tes...";
CM_ SG_ 2566605310 MtGt3IvtHVtBsAtvIstTstRsts "Motor/Generator 3 Inverter High-Voltage Bus Active Isolation Test Results: The isolation resistance that resulted from the High-Voltage Bus Active Isolation Test.See SPN 11885 [High-Voltage Bus Active Isolation Test Status] for test status and SPN 11...";
CM_ SG_ 2566605310 MtGt3IvtHVtBsPssvIstTstRsts "Motor/Generator 3 Inverter High-Voltage Bus Passive Isolation Test Results: The isolation resistance that resulted from the High-Voltage Bus Passive Isolation Test.See SPN 11886 [High-Voltage Bus Passive Isolation Test Status] for test status and SPN...";
CM_ SG_ 2566605310 MtrGnrtr3InvrtrIsltnIntgrtCr "Motor/Generator 3 Inverter Isolation Integrity CRC: The CRC is defined as follows: - Length: 8 bits- Polynomial: x^8+x^5+x^3+x^2+x+1- Initial Value: FFh- Input Data Reflection: Not reflected- Result Data Reflection: Not reflected- XOR value: FFh SAE ...";
CM_ SG_ 2566605310 MtGt3IvtDSdNtvTCsssGdVt "Motor/Generator 3 Inverter DC Side Negative to Chassis Ground Voltage: The voltage level of the high voltage DC side, as measured by the inverter between the negative side of the High Voltage DC Side input and the chassis of the inverter enclosure.  ...";
BA_DEF_ SG_  "SPN" INT 0 524287;
BA_DEF_ BO_  "VFrameFormat" ENUM  "StandardCAN","ExtendedCAN","reserved","J1939PG";
BA_DEF_DEF_  "SPN" 0;
BA_DEF_DEF_  "VFrameFormat" "J1939PG";
BA_ "SPN" SG_ 2566590462 NxTStd100HEOtptEB1Tt 12457;
BA_ "SPN" SG_ 2566590462 NxTrkngStrd100HrEngnOtptEnrgBn2 12458;
BA_ "SPN" SG_ 2566590462 NxTrkngStrd100HrEngnOtptEnrgBn3 12459;
BA_ "SPN" SG_ 2566590462 NxTrkngStrd100HrEngnOtptEnrgBn4 12460;
BA_ "SPN" SG_ 2566590462 NxTrkngStrd100HrEngnOtptEnrgBn5 12461;
BA_ "SPN" SG_ 2566590462 NxTrkngStrd100HrEngnOtptEnrgBn6 12462;
BA_ "SPN" SG_ 2566590462 NxTrkngStrd100HrEngnOtptEnrgBn7 12463;
BA_ "SPN" SG_ 2566590462 NxTrkngStrd100HrEngnOtptEnrgBn8 12464;
BA_ "SPN" SG_ 2566590462 NxTrkngStrd100HrEngnOtptEnrgBn9 12465;
BA_ "SPN" SG_ 2566590462 NxTStd100HEOtptEB10 12466;
BA_ "SPN" SG_ 2566590462 NxTStd100HEOtptEB11 12467;
BA_ "SPN" SG_ 2566590462 NxTStd100HEOtptEB12 12468;
BA_ "SPN" SG_ 2566590462 NxTStd100HEOtptEB13 12469;
BA_ "SPN" SG_ 2566590462 NxTStd100HEOtptEB14 12470;
BA_ "SPN" SG_ 2566590462 NxTStd100HEOtptEB15NtB 12471;
BA_ "SPN" SG_ 2566590462 NxTStd100HEOtptEB16RB 12472;
BA_ "SPN" SG_ 2566590462 NxTStd100HEOtptEB17MOB 12473;
BA_ "SPN" SG_ 2566590718 NxTStd100HEOtNxMssB1Tt 12440;
BA_ "SPN" SG_ 2566590718 NxTrkngStrd100HrEngnOtNxMssBn2 12441;
BA_ "SPN" SG_ 2566590718 NxTrkngStrd100HrEngnOtNxMssBn3 12442;
BA_ "SPN" SG_ 2566590718 NxTrkngStrd100HrEngnOtNxMssBn4 12443;
BA_ "SPN" SG_ 2566590718 NxTrkngStrd100HrEngnOtNxMssBn5 12444;
BA_ "SPN" SG_ 2566590718 NxTrkngStrd100HrEngnOtNxMssBn6 12445;
BA_ "SPN" SG_ 2566590718 NxTrkngStrd100HrEngnOtNxMssBn7 12446;
BA_ "SPN" SG_ 2566590718 NxTrkngStrd100HrEngnOtNxMssBn8 12447;
BA_ "SPN" SG_ 2566590718 NxTrkngStrd100HrEngnOtNxMssBn9 12448;
BA_ "SPN" SG_ 2566590718 NxTrkngStrd100HrEngnOtNxMssBn10 12449;
BA_ "SPN" SG_ 2566590718 NxTrkngStrd100HrEngnOtNxMssBn11 12450;
BA_ "SPN" SG_ 2566590718 NxTrkngStrd100HrEngnOtNxMssBn12 12451;
BA_ "SPN" SG_ 2566590718 NxTrkngStrd100HrEngnOtNxMssBn13 12452;
BA_ "SPN" SG_ 2566590718 NxTrkngStrd100HrEngnOtNxMssBn14 12453;
BA_ "SPN" SG_ 2566590718 NxTStd100HEOtNxMssB15NtB 12454;
BA_ "SPN" SG_ 2566590718 NxTStd100HEOtNxMssB16RB 12455;
BA_ "SPN" SG_ 2566590718 NxTStd100HEOtNxMssB17MOB 12456;
BA_ "SPN" SG_ 2566590974 NxTStd100HSstOtNxMssB1Tt 12423;
BA_ "SPN" SG_ 2566590974 NxTrkngStrd100HrSstmOtNxMssBn2 12424;
BA_ "SPN" SG_ 2566590974 NxTrkngStrd100HrSstmOtNxMssBn3 12425;
BA_ "SPN" SG_ 2566590974 NxTrkngStrd100HrSstmOtNxMssBn4 12426;
BA_ "SPN" SG_ 2566590974 NxTrkngStrd100HrSstmOtNxMssBn5 12427;
BA_ "SPN" SG_ 2566590974 NxTrkngStrd100HrSstmOtNxMssBn6 12428;
BA_ "SPN" SG_ 2566590974 NxTrkngStrd100HrSstmOtNxMssBn7 12429;
BA_ "SPN" SG_ 2566590974 NxTrkngStrd100HrSstmOtNxMssBn8 12430;
BA_ "SPN" SG_ 2566590974 NxTrkngStrd100HrSstmOtNxMssBn9 12431;
BA_ "SPN" SG_ 2566590974 NxTrkngStrd100HrSstmOtNxMssBn10 12432;
BA_ "SPN" SG_ 2566590974 NxTrkngStrd100HrSstmOtNxMssBn11 12433;
BA_ "SPN" SG_ 2566590974 NxTrkngStrd100HrSstmOtNxMssBn12 12434;
BA_ "SPN" SG_ 2566590974 NxTrkngStrd100HrSstmOtNxMssBn13 12435;
BA_ "SPN" SG_ 2566590974 NxTrkngStrd100HrSstmOtNxMssBn14 12436;
BA_ "SPN" SG_ 2566590974 NxTStd100HSstOtNxMssB15NtB 12437;
BA_ "SPN" SG_ 2566590974 NxTStd100HSstOtNxMssB16RB 12438;
BA_ "SPN" SG_ 2566590974 NxTStd100HSstOtNxMssB17MOB 12439;
BA_ "SPN" SG_ 2566591230 NxTrkngAtv100HrFlCnsmptnBn1Ttl 12406;
BA_ "SPN" SG_ 2566591230 NxTrkngAtv100HrFlCnsmptnBn2 12407;
BA_ "SPN" SG_ 2566591230 NxTrkngAtv100HrFlCnsmptnBn3 12408;
BA_ "SPN" SG_ 2566591230 NxTrkngAtv100HrFlCnsmptnBn4 12409;
BA_ "SPN" SG_ 2566591230 NxTrkngAtv100HrFlCnsmptnBn5 12410;
BA_ "SPN" SG_ 2566591230 NxTrkngAtv100HrFlCnsmptnBn6 12411;
BA_ "SPN" SG_ 2566591230 NxTrkngAtv100HrFlCnsmptnBn7 12412;
BA_ "SPN" SG_ 2566591230 NxTrkngAtv100HrFlCnsmptnBn8 12413;
BA_ "SPN" SG_ 2566591230 NxTrkngAtv100HrFlCnsmptnBn9 12414;
BA_ "SPN" SG_ 2566591230 NxTrkngAtv100HrFlCnsmptnBn10 12415;
BA_ "SPN" SG_ 2566591230 NxTrkngAtv100HrFlCnsmptnBn11 12416;
BA_ "SPN" SG_ 2566591230 NxTrkngAtv100HrFlCnsmptnBn12 12417;
BA_ "SPN" SG_ 2566591230 NxTrkngAtv100HrFlCnsmptnBn13 12418;
BA_ "SPN" SG_ 2566591230 NxTrkngAtv100HrFlCnsmptnBn14 12419;
BA_ "SPN" SG_ 2566591230 NxTAtv100HFCsptB15NtB 12420;
BA_ "SPN" SG_ 2566591230 NxTAtv100HFCsptB16RB 12421;
BA_ "SPN" SG_ 2566591230 NxTAtv100HFCsptB17MOB 12422;
BA_ "SPN" SG_ 2566591486 NxTrkngAtv100HrEngnRnTmBn1Ttl 12389;
BA_ "SPN" SG_ 2566591486 NxTrkngAtv100HrEngnRnTmBn2 12390;
BA_ "SPN" SG_ 2566591486 NxTrkngAtv100HrEngnRnTmBn3 12391;
BA_ "SPN" SG_ 2566591486 NxTrkngAtv100HrEngnRnTmBn4 12392;
BA_ "SPN" SG_ 2566591486 NxTrkngAtv100HrEngnRnTmBn5 12393;
BA_ "SPN" SG_ 2566591486 NxTrkngAtv100HrEngnRnTmBn6 12394;
BA_ "SPN" SG_ 2566591486 NxTrkngAtv100HrEngnRnTmBn7 12395;
BA_ "SPN" SG_ 2566591486 NxTrkngAtv100HrEngnRnTmBn8 12396;
BA_ "SPN" SG_ 2566591486 NxTrkngAtv100HrEngnRnTmBn9 12397;
BA_ "SPN" SG_ 2566591486 NxTrkngAtv100HrEngnRnTmBn10 12398;
BA_ "SPN" SG_ 2566591486 NxTrkngAtv100HrEngnRnTmBn11 12399;
BA_ "SPN" SG_ 2566591486 NxTrkngAtv100HrEngnRnTmBn12 12400;
BA_ "SPN" SG_ 2566591486 NxTrkngAtv100HrEngnRnTmBn13 12401;
BA_ "SPN" SG_ 2566591486 NxTrkngAtv100HrEngnRnTmBn14 12402;
BA_ "SPN" SG_ 2566591486 NxTrkngAtv100HrEngnRnTmBn15NtBn 12403;
BA_ "SPN" SG_ 2566591486 NxTAtv100HERTB16RB 12404;
BA_ "SPN" SG_ 2566591486 NxTAtv100HERTB17MOB 12405;
BA_ "SPN" SG_ 2566591742 NxTrkngAtv100HrVhlDstnBn1Ttl 12372;
BA_ "SPN" SG_ 2566591742 NxTrkngAtv100HrVhlDstnBn2 12373;
BA_ "SPN" SG_ 2566591742 NxTrkngAtv100HrVhlDstnBn3 12374;
BA_ "SPN" SG_ 2566591742 NxTrkngAtv100HrVhlDstnBn4 12375;
BA_ "SPN" SG_ 2566591742 NxTrkngAtv100HrVhlDstnBn5 12376;
BA_ "SPN" SG_ 2566591742 NxTrkngAtv100HrVhlDstnBn6 12377;
BA_ "SPN" SG_ 2566591742 NxTrkngAtv100HrVhlDstnBn7 12378;
BA_ "SPN" SG_ 2566591742 NxTrkngAtv100HrVhlDstnBn8 12379;
BA_ "SPN" SG_ 2566591742 NxTrkngAtv100HrVhlDstnBn9 12380;
BA_ "SPN" SG_ 2566591742 NxTrkngAtv100HrVhlDstnBn10 12381;
BA_ "SPN" SG_ 2566591742 NxTrkngAtv100HrVhlDstnBn11 12382;
BA_ "SPN" SG_ 2566591742 NxTrkngAtv100HrVhlDstnBn12 12383;
BA_ "SPN" SG_ 2566591742 NxTrkngAtv100HrVhlDstnBn13 12384;
BA_ "SPN" SG_ 2566591742 NxTrkngAtv100HrVhlDstnBn14 12385;
BA_ "SPN" SG_ 2566591742 NxTrkngAtv100HrVhlDstnBn15NtBn 12386;
BA_ "SPN" SG_ 2566591742 NxTrkngAtv100HrVhlDstnBn16RgnBn 12387;
BA_ "SPN" SG_ 2566591742 NxTAtv100HVDstB17MOB 12388;
BA_ "SPN" SG_ 2566591998 NxTAtv100HEOtptEB1Tt 12355;
BA_ "SPN" SG_ 2566591998 NxTrkngAtv100HrEngnOtptEnrgBn2 12356;
BA_ "SPN" SG_ 2566591998 NxTrkngAtv100HrEngnOtptEnrgBn3 12357;
BA_ "SPN" SG_ 2566591998 NxTrkngAtv100HrEngnOtptEnrgBn4 12358;
BA_ "SPN" SG_ 2566591998 NxTrkngAtv100HrEngnOtptEnrgBn5 12359;
BA_ "SPN" SG_ 2566591998 NxTrkngAtv100HrEngnOtptEnrgBn6 12360;
BA_ "SPN" SG_ 2566591998 NxTrkngAtv100HrEngnOtptEnrgBn7 12361;
BA_ "SPN" SG_ 2566591998 NxTrkngAtv100HrEngnOtptEnrgBn8 12362;
BA_ "SPN" SG_ 2566591998 NxTrkngAtv100HrEngnOtptEnrgBn9 12363;
BA_ "SPN" SG_ 2566591998 NxTrkngAtv100HrEngnOtptEnrgBn10 12364;
BA_ "SPN" SG_ 2566591998 NxTrkngAtv100HrEngnOtptEnrgBn11 12365;
BA_ "SPN" SG_ 2566591998 NxTrkngAtv100HrEngnOtptEnrgBn12 12366;
BA_ "SPN" SG_ 2566591998 NxTrkngAtv100HrEngnOtptEnrgBn13 12367;
BA_ "SPN" SG_ 2566591998 NxTrkngAtv100HrEngnOtptEnrgBn14 12368;
BA_ "SPN" SG_ 2566591998 NxTAtv100HEOtptEB15NtB 12369;
BA_ "SPN" SG_ 2566591998 NxTAtv100HEOtptEB16RB 12370;
BA_ "SPN" SG_ 2566591998 NxTAtv100HEOtptEB17MOB 12371;
BA_ "SPN" SG_ 2566592254 NxTAtv100HEOtNxMssB1Tt 12338;
BA_ "SPN" SG_ 2566592254 NxTrkngAtv100HrEngnOtNxMssBn2 12339;
BA_ "SPN" SG_ 2566592254 NxTrkngAtv100HrEngnOtNxMssBn3 12340;
BA_ "SPN" SG_ 2566592254 NxTrkngAtv100HrEngnOtNxMssBn4 12341;
BA_ "SPN" SG_ 2566592254 NxTrkngAtv100HrEngnOtNxMssBn5 12342;
BA_ "SPN" SG_ 2566592254 NxTrkngAtv100HrEngnOtNxMssBn6 12343;
BA_ "SPN" SG_ 2566592254 NxTrkngAtv100HrEngnOtNxMssBn7 12344;
BA_ "SPN" SG_ 2566592254 NxTrkngAtv100HrEngnOtNxMssBn8 12345;
BA_ "SPN" SG_ 2566592254 NxTrkngAtv100HrEngnOtNxMssBn9 12346;
BA_ "SPN" SG_ 2566592254 NxTrkngAtv100HrEngnOtNxMssBn10 12347;
BA_ "SPN" SG_ 2566592254 NxTrkngAtv100HrEngnOtNxMssBn11 12348;
BA_ "SPN" SG_ 2566592254 NxTrkngAtv100HrEngnOtNxMssBn12 12349;
BA_ "SPN" SG_ 2566592254 NxTrkngAtv100HrEngnOtNxMssBn13 12350;
BA_ "SPN" SG_ 2566592254 NxTrkngAtv100HrEngnOtNxMssBn14 12351;
BA_ "SPN" SG_ 2566592254 NxTAtv100HEOtNxMssB15NtB 12352;
BA_ "SPN" SG_ 2566592254 NxTAtv100HEOtNxMssB16RB 12353;
BA_ "SPN" SG_ 2566592254 NxTAtv100HEOtNxMssB17MOB 12354;
BA_ "SPN" SG_ 2566592510 NxTAtv100HSstOtNxMssB1Tt 12321;
BA_ "SPN" SG_ 2566592510 NxTrkngAtv100HrSstmOtNxMssBn2 12322;
BA_ "SPN" SG_ 2566592510 NxTrkngAtv100HrSstmOtNxMssBn3 12323;
BA_ "SPN" SG_ 2566592510 NxTrkngAtv100HrSstmOtNxMssBn4 12324;
BA_ "SPN" SG_ 2566592510 NxTrkngAtv100HrSstmOtNxMssBn5 12325;
BA_ "SPN" SG_ 2566592510 NxTrkngAtv100HrSstmOtNxMssBn6 12326;
BA_ "SPN" SG_ 2566592510 NxTrkngAtv100HrSstmOtNxMssBn7 12327;
BA_ "SPN" SG_ 2566592510 NxTrkngAtv100HrSstmOtNxMssBn8 12328;
BA_ "SPN" SG_ 2566592510 NxTrkngAtv100HrSstmOtNxMssBn9 12329;
BA_ "SPN" SG_ 2566592510 NxTrkngAtv100HrSstmOtNxMssBn10 12330;
BA_ "SPN" SG_ 2566592510 NxTrkngAtv100HrSstmOtNxMssBn11 12331;
BA_ "SPN" SG_ 2566592510 NxTrkngAtv100HrSstmOtNxMssBn12 12332;
BA_ "SPN" SG_ 2566592510 NxTrkngAtv100HrSstmOtNxMssBn13 12333;
BA_ "SPN" SG_ 2566592510 NxTrkngAtv100HrSstmOtNxMssBn14 12334;
BA_ "SPN" SG_ 2566592510 NxTAtv100HSstOtNxMssB15NtB 12335;
BA_ "SPN" SG_ 2566592510 NxTAtv100HSstOtNxMssB16RB 12336;
BA_ "SPN" SG_ 2566592510 NxTAtv100HSstOtNxMssB17MOB 12337;
BA_ "SPN" SG_ 2365266174 MtrGnrtr6InvrtrRtLmtsRqst2Cntr 12267;
BA_ "SPN" SG_ 2365266174 MtrGnrtr6InvrtrRtLmtsRqst2Cr 12266;
BA_ "SPN" SG_ 2365266174 MtrGnrtr6InvrtrPdCntrlAppllMd 12268;
BA_ "SPN" SG_ 2365266174 MtGt6IvtPdCtNzdDtG 12269;
BA_ "SPN" SG_ 2365266174 MtGt6IvtPdCtNzdItG 12270;
BA_ "SPN" SG_ 2365266174 MtGt6IvtPdCtNzdPptG 12271;
BA_ "SPN" SG_ 2365266174 MtGt6IvtPdCtFdFwdTq 12272;
BA_ "SPN" SG_ 2566593022 MtrGnrtr6InvrtrLmtsRqstPwrCntr 12182;
BA_ "SPN" SG_ 2566593022 MtGt6IvtLtsRqstMPwMx 12183;
BA_ "SPN" SG_ 2566593022 MtGt6IvtLtsRqstMPwM 12184;
BA_ "SPN" SG_ 2566593022 MtrGnrtr6InvrtrLmtsRqstPwrCr 12181;
BA_ "SPN" SG_ 2566593022 MtGt6IvtLtsRqstDSdPwMx 12185;
BA_ "SPN" SG_ 2566593022 MtGt6IvtLtsRqstDSdPwM 12186;
BA_ "SPN" SG_ 2566593278 MtrGnrtr6InvrtrLmtsRqstMhnlCntr 12194;
BA_ "SPN" SG_ 2566593278 MtrGnrtr6InvrtrLmtsRqstTrqMxmm 12195;
BA_ "SPN" SG_ 2566593278 MtrGnrtr6InvrtrLmtsRqstTrqMnmm 12196;
BA_ "SPN" SG_ 2566593278 MtrGnrtr6InvrtrLmtsRqstSpdMxmm 12197;
BA_ "SPN" SG_ 2566593278 MtrGnrtr6InvrtrLmtsRqstSpdMnmm 12198;
BA_ "SPN" SG_ 2566593278 MtrGnrtr6InvrtrLmtsRqstMhnlCr 12193;
BA_ "SPN" SG_ 2566593534 MtrGnrtr6InvrtrLmtsRqstDSdCr 12209;
BA_ "SPN" SG_ 2566593534 MtrGnrtr6InvrtrLmtsRqstDSdCntr 12210;
BA_ "SPN" SG_ 2566593534 MtGt6IvtLtsRqstDSdVtMx 12211;
BA_ "SPN" SG_ 2566593534 MtGt6IvtLtsRqstDSdVtM 12212;
BA_ "SPN" SG_ 2566593534 MtGt6IvtLtsRqstDSdCtMx 12213;
BA_ "SPN" SG_ 2566593534 MtGt6IvtLtsRqstDSdCtM 12214;
BA_ "SPN" SG_ 2566593790 MtGt6IvtHVtBsAtvIstTstCd 12232;
BA_ "SPN" SG_ 2566593790 MtGt6IvtHVtBsPssvIstTstCd 12233;
BA_ "SPN" SG_ 2566593790 MtGt6IvtHVtBsHSdRsstCtRqst 12234;
BA_ "SPN" SG_ 2566593790 MtGt6IvtHVtBsLwSdRsstCtRqst 12235;
BA_ "SPN" SG_ 2365267454 MtrGnrtr5InvrtrRtLmtsRqst2Cntr 12149;
BA_ "SPN" SG_ 2365267454 MtrGnrtr5InvrtrRtLmtsRqst2Cr 12148;
BA_ "SPN" SG_ 2365267454 MtrGnrtr5InvrtrPdCntrlAppllMd 12150;
BA_ "SPN" SG_ 2365267454 MtGt5IvtPdCtNzdDtG 12151;
BA_ "SPN" SG_ 2365267454 MtGt5IvtPdCtNzdItG 12152;
BA_ "SPN" SG_ 2365267454 MtGt5IvtPdCtNzdPptG 12153;
BA_ "SPN" SG_ 2365267454 MtGt5IvtPdCtFdFwdTq 12154;
BA_ "SPN" SG_ 2566594302 MtrGnrtr5InvrtrLmtsRqstPwrCntr 12064;
BA_ "SPN" SG_ 2566594302 MtGt5IvtLtsRqstMPwMx 12065;
BA_ "SPN" SG_ 2566594302 MtGt5IvtLtsRqstMPwM 12066;
BA_ "SPN" SG_ 2566594302 MtrGnrtr5InvrtrLmtsRqstPwrCr 12063;
BA_ "SPN" SG_ 2566594302 MtGt5IvtLtsRqstDSdPwMx 12067;
BA_ "SPN" SG_ 2566594302 MtGt5IvtLtsRqstDSdPwM 12068;
BA_ "SPN" SG_ 2566594558 MtrGnrtr5InvrtrLmtsRqstMhnlCntr 12076;
BA_ "SPN" SG_ 2566594558 MtrGnrtr5InvrtrLmtsRqstTrqMxmm 12077;
BA_ "SPN" SG_ 2566594558 MtrGnrtr5InvrtrLmtsRqstTrqMnmm 12078;
BA_ "SPN" SG_ 2566594558 MtrGnrtr5InvrtrLmtsRqstSpdMxmm 12079;
BA_ "SPN" SG_ 2566594558 MtrGnrtr5InvrtrLmtsRqstSpdMnmm 12080;
BA_ "SPN" SG_ 2566594558 MtrGnrtr5InvrtrLmtsRqstMhnlCr 12075;
BA_ "SPN" SG_ 2566594814 MtrGnrtr5InvrtrLmtsRqstDSdCr 12091;
BA_ "SPN" SG_ 2566594814 MtrGnrtr5InvrtrLmtsRqstDSdCntr 12092;
BA_ "SPN" SG_ 2566594814 MtGt5IvtLtsRqstDSdVtMx 12093;
BA_ "SPN" SG_ 2566594814 MtGt5IvtLtsRqstDSdVtM 12094;
BA_ "SPN" SG_ 2566594814 MtGt5IvtLtsRqstDSdCtMx 12095;
BA_ "SPN" SG_ 2566594814 MtGt5IvtLtsRqstDSdCtM 12096;
BA_ "SPN" SG_ 2566595070 MtGt5IvtHVtBsAtvIstTstCd 12114;
BA_ "SPN" SG_ 2566595070 MtGt5IvtHVtBsPssvIstTstCd 12115;
BA_ "SPN" SG_ 2566595070 MtGt5IvtHVtBsHSdRsstCtRqst 12116;
BA_ "SPN" SG_ 2566595070 MtGt5IvtHVtBsLwSdRsstCtRqst 12117;
BA_ "SPN" SG_ 2365268734 MtrGnrtr4InvrtrRtLmtsRqst2Cntr 12031;
BA_ "SPN" SG_ 2365268734 MtrGnrtr4InvrtrRtLmtsRqst2Cr 12030;
BA_ "SPN" SG_ 2365268734 MtrGnrtr4InvrtrPdCntrlAppllMd 12032;
BA_ "SPN" SG_ 2365268734 MtGt4IvtPdCtNzdDtG 12033;
BA_ "SPN" SG_ 2365268734 MtGt4IvtPdCtNzdItG 12034;
BA_ "SPN" SG_ 2365268734 MtGt4IvtPdCtNzdPptG 12035;
BA_ "SPN" SG_ 2365268734 MtGt4IvtPdCtFdFwdTq 12036;
BA_ "SPN" SG_ 2566595582 MtrGnrtr4InvrtrLmtsRqstPwrCntr 11946;
BA_ "SPN" SG_ 2566595582 MtGt4IvtLtsRqstMPwMx 11947;
BA_ "SPN" SG_ 2566595582 MtGt4IvtLtsRqstMPwM 11948;
BA_ "SPN" SG_ 2566595582 MtrGnrtr4InvrtrLmtsRqstPwrCr 11945;
BA_ "SPN" SG_ 2566595582 MtGt4IvtLtsRqstDSdPwMx 11949;
BA_ "SPN" SG_ 2566595582 MtGt4IvtLtsRqstDSdPwM 11950;
BA_ "SPN" SG_ 2566595838 MtrGnrtr4InvrtrLmtsRqstMhnlCntr 11958;
BA_ "SPN" SG_ 2566595838 MtrGnrtr4InvrtrLmtsRqstTrqMxmm 11959;
BA_ "SPN" SG_ 2566595838 MtrGnrtr4InvrtrLmtsRqstTrqMnmm 11960;
BA_ "SPN" SG_ 2566595838 MtrGnrtr4InvrtrLmtsRqstSpdMxmm 11961;
BA_ "SPN" SG_ 2566595838 MtrGnrtr4InvrtrLmtsRqstSpdMnmm 11962;
BA_ "SPN" SG_ 2566595838 MtrGnrtr4InvrtrLmtsRqstMhnlCr 11957;
BA_ "SPN" SG_ 2566596094 MtrGnrtr4InvrtrLmtsRqstDSdCr 11973;
BA_ "SPN" SG_ 2566596094 MtrGnrtr4InvrtrLmtsRqstDSdCntr 11974;
BA_ "SPN" SG_ 2566596094 MtGt4IvtLtsRqstDSdVtMx 11975;
BA_ "SPN" SG_ 2566596094 MtGt4IvtLtsRqstDSdVtM 11976;
BA_ "SPN" SG_ 2566596094 MtGt4IvtLtsRqstDSdCtMx 11977;
BA_ "SPN" SG_ 2566596094 MtGt4IvtLtsRqstDSdCtM 11978;
BA_ "SPN" SG_ 2566596350 MtGt4IvtHVtBsAtvIstTstCd 11996;
BA_ "SPN" SG_ 2566596350 MtGt4IvtHVtBsPssvIstTstCd 11997;
BA_ "SPN" SG_ 2566596350 MtGt4IvtHVtBsHSdRsstCtRqst 11998;
BA_ "SPN" SG_ 2566596350 MtGt4IvtHVtBsLwSdRsstCtRqst 11999;
BA_ "SPN" SG_ 2365270014 MtrGnrtr3InvrtrRtLmtsRqst2Cntr 11913;
BA_ "SPN" SG_ 2365270014 MtrGnrtr3InvrtrRtLmtsRqst2Cr 11912;
BA_ "SPN" SG_ 2365270014 MtrGnrtr3InvrtrPdCntrlAppllMd 11914;
BA_ "SPN" SG_ 2365270014 MtGt3IvtPdCtNzdDtG 11915;
BA_ "SPN" SG_ 2365270014 MtGt3IvtPdCtNzdItG 11916;
BA_ "SPN" SG_ 2365270014 MtGt3IvtPdCtNzdPptG 11917;
BA_ "SPN" SG_ 2365270014 MtGt3IvtPdCtFdFwdTq 11918;
BA_ "SPN" SG_ 2566596862 MtrGnrtr3InvrtrLmtsRqstPwrCntr 11828;
BA_ "SPN" SG_ 2566596862 MtGt3IvtLtsRqstMPwMx 11829;
BA_ "SPN" SG_ 2566596862 MtGt3IvtLtsRqstMPwM 11830;
BA_ "SPN" SG_ 2566596862 MtrGnrtr3InvrtrLmtsRqstPwrCr 11827;
BA_ "SPN" SG_ 2566596862 MtGt3IvtLtsRqstDSdPwMx 11831;
BA_ "SPN" SG_ 2566596862 MtGt3IvtLtsRqstDSdPwM 11832;
BA_ "SPN" SG_ 2566597118 MtrGnrtr3InvrtrLmtsRqstMhnlCntr 11840;
BA_ "SPN" SG_ 2566597118 MtrGnrtr3InvrtrLmtsRqstTrqMxmm 11841;
BA_ "SPN" SG_ 2566597118 MtrGnrtr3InvrtrLmtsRqstTrqMnmm 11842;
BA_ "SPN" SG_ 2566597118 MtrGnrtr3InvrtrLmtsRqstSpdMxmm 11843;
BA_ "SPN" SG_ 2566597118 MtrGnrtr3InvrtrLmtsRqstSpdMnmm 11844;
BA_ "SPN" SG_ 2566597118 MtrGnrtr3InvrtrLmtsRqstMhnlCr 11839;
BA_ "SPN" SG_ 2566597374 MtrGnrtr3InvrtrLmtsRqstDSdCr 11855;
BA_ "SPN" SG_ 2566597374 MtrGnrtr3InvrtrLmtsRqstDSdCntr 11856;
BA_ "SPN" SG_ 2566597374 MtGt3IvtLtsRqstDSdVtMx 11857;
BA_ "SPN" SG_ 2566597374 MtGt3IvtLtsRqstDSdVtM 11858;
BA_ "SPN" SG_ 2566597374 MtGt3IvtLtsRqstDSdCtMx 11859;
BA_ "SPN" SG_ 2566597374 MtGt3IvtLtsRqstDSdCtM 11860;
BA_ "SPN" SG_ 2566597630 MtGt3IvtHVtBsAtvIstTstCd 11878;
BA_ "SPN" SG_ 2566597630 MtGt3IvtHVtBsPssvIstTstCd 11879;
BA_ "SPN" SG_ 2566597630 MtGt3IvtHVtBsHSdRsstCtRqst 11880;
BA_ "SPN" SG_ 2566597630 MtGt3IvtHVtBsLwSdRsstCtRqst 11881;
BA_ "SPN" SG_ 2566598142 EngineTurbocharger5Speed 12313;
BA_ "SPN" SG_ 2566598142 EngineTurbocharger6Speed 12314;
BA_ "SPN" SG_ 2566598142 EngnTrhrgr5CmprssrIntkPrssr 12315;
BA_ "SPN" SG_ 2566598142 EngnTrhrgr6CmprssrIntkPrssr 12316;
BA_ "SPN" SG_ 2566598398 WinchLifetimeRevolutionCounter 12311;
BA_ "SPN" SG_ 2365272062 MtrGnrtr6InvrtrRfrn1Cntr 12174;
BA_ "SPN" SG_ 2365272062 MtrGnrtr6InvrtrRfrnTrq 12175;
BA_ "SPN" SG_ 2365272062 MtrGnrtr6InvrtrRfrnSpd 12176;
BA_ "SPN" SG_ 2365272062 MtrGnrtr6InvrtrRfrnPwr 12177;
BA_ "SPN" SG_ 2365272062 MtrGnrtr6InvrtrRfrn1Cr 12173;
BA_ "SPN" SG_ 2365272318 MtrGnrtr6InvrtrStts1Cntr 12179;
BA_ "SPN" SG_ 2365272318 MotorGenerator6Torque 12157;
BA_ "SPN" SG_ 2365272318 MotorGenerator6Speed 12155;
BA_ "SPN" SG_ 2365272318 MtrGnrtr6InvrtrStts1Cr 12178;
BA_ "SPN" SG_ 2365272318 MtrGnrtr6InvrtrDSdCrrnt 12180;
BA_ "SPN" SG_ 2365272318 MtrGnrtr6InvrtrDSdVltg 12158;
BA_ "SPN" SG_ 2365272574 MtrGnrtr6InvrtrRfrn2Cntr 12206;
BA_ "SPN" SG_ 2365272574 MtrGnrtr6InvrtrRfrnCrrnt 12207;
BA_ "SPN" SG_ 2365272574 MtrGnrtr6InvrtrRfrnVltg 12208;
BA_ "SPN" SG_ 2365272574 MtrGnrtr6InvrtrRfrn2Cr 12205;
BA_ "SPN" SG_ 2566599422 MtrGnrtr6InvrtrTmprtr1 12221;
BA_ "SPN" SG_ 2566599422 MtrGnrtr6InvrtrTmprtr2 12222;
BA_ "SPN" SG_ 2566599422 MtrGnrtr6InvrtrTmprtr3 12223;
BA_ "SPN" SG_ 2566599422 MtrGnrtr6InvrtrTmprtr4 12224;
BA_ "SPN" SG_ 2566599422 MtrGnrtr6InvrtrTmprtr5 20919;
BA_ "SPN" SG_ 2566599678 MotorGenerator6Temperature1 12156;
BA_ "SPN" SG_ 2566599678 MotorGenerator6Temperature2 12225;
BA_ "SPN" SG_ 2566599678 MotorGenerator6Temperature3 12226;
BA_ "SPN" SG_ 2566599678 MotorGenerator6Temperature4 12227;
BA_ "SPN" SG_ 2566599934 MtrGnrtr6InvrtrIsltnIntgrtCntr 12237;
BA_ "SPN" SG_ 2566599934 MtGt6IvtHVtBsAtvIstTstStts 12239;
BA_ "SPN" SG_ 2566599934 MtGt6IvtHVtBsPssvIstTstStts 12240;
BA_ "SPN" SG_ 2566599934 MtGt6IvtHVtBsAtvIstTstRsts 12241;
BA_ "SPN" SG_ 2566599934 MtGt6IvtHVtBsPssvIstTstRsts 12242;
BA_ "SPN" SG_ 2566599934 MtrGnrtr6InvrtrIsltnIntgrtCr 12236;
BA_ "SPN" SG_ 2566599934 MtGt6IvtDSdNtvTCsssGdVt 12238;
BA_ "SPN" SG_ 2566600190 MtGt6IvtPwLtdDTUddRs 12243;
BA_ "SPN" SG_ 2566600190 MtGt6IvtPwLtdDTMPwMx 12248;
BA_ "SPN" SG_ 2566600190 MtGt6IvtPwLtdDTMPwM 12249;
BA_ "SPN" SG_ 2566600190 MtrGnrtr6InvrtrPwrLmtdDTTrqMxmm 12252;
BA_ "SPN" SG_ 2566600190 MtrGnrtr6InvrtrPwrLmtdDTTrqMnmm 12253;
BA_ "SPN" SG_ 2566600190 MtrGnrtr6InvrtrPwrLmtdDTSpdMxmm 12254;
BA_ "SPN" SG_ 2566600190 MtrGnrtr6InvrtrPwrLmtdDTSpdMnmm 12255;
BA_ "SPN" SG_ 2566600190 MtGt6IvtPwLtdDTIvtTpt 12256;
BA_ "SPN" SG_ 2566600190 MtGt6IvtPwLtdDTMtTpt 12257;
BA_ "SPN" SG_ 2566600190 MtGt6IvtPwLtdDTFtCdt 13061;
BA_ "SPN" SG_ 2566600190 MtGt6IvtPwLtdDTAtvTqRtLt 13062;
BA_ "SPN" SG_ 2566600190 MtGt6IvtPwLtdDTAtvSpdRtLt 13063;
BA_ "SPN" SG_ 2566600190 MtGt6IvtTqLtdDTMCtsts 13064;
BA_ "SPN" SG_ 2566600190 MtGt6IvtPwLtdDTDSdCtMx 12244;
BA_ "SPN" SG_ 2566600190 MtGt6IvtPwLtdDTDSdCtM 12245;
BA_ "SPN" SG_ 2566600190 MtGt6IvtPwLtdDTDSdVtMx 12246;
BA_ "SPN" SG_ 2566600190 MtGt6IvtPwLtdDTDSdVtM 12247;
BA_ "SPN" SG_ 2566600190 MtGt6IvtPwLtdDTDSdPwMx 12250;
BA_ "SPN" SG_ 2566600190 MtGt6IvtPwLtdDTDSdPwM 12251;
BA_ "SPN" SG_ 2365273854 MtrGnrtr5InvrtrRfrn1Cntr 12056;
BA_ "SPN" SG_ 2365273854 MtrGnrtr5InvrtrRfrnTrq 12057;
BA_ "SPN" SG_ 2365273854 MtrGnrtr5InvrtrRfrnSpd 12058;
BA_ "SPN" SG_ 2365273854 MtrGnrtr5InvrtrRfrnPwr 12059;
BA_ "SPN" SG_ 2365273854 MtrGnrtr5InvrtrRfrn1Cr 12055;
BA_ "SPN" SG_ 2365274110 MtrGnrtr5InvrtrStts1Cntr 12061;
BA_ "SPN" SG_ 2365274110 MotorGenerator5Torque 12039;
BA_ "SPN" SG_ 2365274110 MotorGenerator5Speed 12037;
BA_ "SPN" SG_ 2365274110 MtrGnrtr5InvrtrStts1Cr 12060;
BA_ "SPN" SG_ 2365274110 MtrGnrtr5InvrtrDSdCrrnt 12062;
BA_ "SPN" SG_ 2365274110 MtrGnrtr5InvrtrDSdVltg 12040;
BA_ "SPN" SG_ 2365274366 MtrGnrtr5InvrtrRfrn2Cntr 12088;
BA_ "SPN" SG_ 2365274366 MtrGnrtr5InvrtrRfrnCrrnt 12089;
BA_ "SPN" SG_ 2365274366 MtrGnrtr5InvrtrRfrnVltg 12090;
BA_ "SPN" SG_ 2365274366 MtrGnrtr5InvrtrRfrn2Cr 12087;
BA_ "SPN" SG_ 2566601214 MtrGnrtr5InvrtrTmprtr1 12103;
BA_ "SPN" SG_ 2566601214 MtrGnrtr5InvrtrTmprtr2 12104;
BA_ "SPN" SG_ 2566601214 MtrGnrtr5InvrtrTmprtr3 12105;
BA_ "SPN" SG_ 2566601214 MtrGnrtr5InvrtrTmprtr4 12106;
BA_ "SPN" SG_ 2566601214 MtrGnrtr5InvrtrTmprtr5 20918;
BA_ "SPN" SG_ 2566601470 MotorGenerator5Temperature1 12038;
BA_ "SPN" SG_ 2566601470 MotorGenerator5Temperature2 12107;
BA_ "SPN" SG_ 2566601470 MotorGenerator5Temperature3 12108;
BA_ "SPN" SG_ 2566601470 MotorGenerator5Temperature4 12109;
BA_ "SPN" SG_ 2566601726 MtrGnrtr5InvrtrIsltnIntgrtCntr 12119;
BA_ "SPN" SG_ 2566601726 MtGt5IvtHVtBsAtvIstTstStts 12121;
BA_ "SPN" SG_ 2566601726 MtGt5IvtHVtBsPssvIstTstStts 12122;
BA_ "SPN" SG_ 2566601726 MtGt5IvtHVtBsAtvIstTstRsts 12123;
BA_ "SPN" SG_ 2566601726 MtGt5IvtHVtBsPssvIstTstRsts 12124;
BA_ "SPN" SG_ 2566601726 MtrGnrtr5InvrtrIsltnIntgrtCr 12118;
BA_ "SPN" SG_ 2566601726 MtGt5IvtDSdNtvTCsssGdVt 12120;
BA_ "SPN" SG_ 2566601982 MtGt5IvtPwLtdDTUddRs 12125;
BA_ "SPN" SG_ 2566601982 MtGt5IvtPwLtdDTMPwMx 12130;
BA_ "SPN" SG_ 2566601982 MtGt5IvtPwLtdDTMPwM 12131;
BA_ "SPN" SG_ 2566601982 MtrGnrtr5InvrtrPwrLmtdDTTrqMxmm 12134;
BA_ "SPN" SG_ 2566601982 MtrGnrtr5InvrtrPwrLmtdDTTrqMnmm 12135;
BA_ "SPN" SG_ 2566601982 MtrGnrtr5InvrtrPwrLmtdDTSpdMxmm 12136;
BA_ "SPN" SG_ 2566601982 MtrGnrtr5InvrtrPwrLmtdDTSpdMnmm 12137;
BA_ "SPN" SG_ 2566601982 MtGt5IvtPwLtdDTIvtTpt 12138;
BA_ "SPN" SG_ 2566601982 MtGt5IvtPwLtdDTMtTpt 12139;
BA_ "SPN" SG_ 2566601982 MtGt5IvtPwLtdDTFtCdt 13057;
BA_ "SPN" SG_ 2566601982 MtGt5IvtPwLtdDTAtvTqRtLt 13058;
BA_ "SPN" SG_ 2566601982 MtGt5IvtPwLtdDTAtvSpdRtLt 13059;
BA_ "SPN" SG_ 2566601982 MtGt5IvtTqLtdDTMCtsts 13060;
BA_ "SPN" SG_ 2566601982 MtGt5IvtPwLtdDTDSdCtMx 12126;
BA_ "SPN" SG_ 2566601982 MtGt5IvtPwLtdDTDSdCtM 12127;
BA_ "SPN" SG_ 2566601982 MtGt5IvtPwLtdDTDSdVtMx 12128;
BA_ "SPN" SG_ 2566601982 MtGt5IvtPwLtdDTDSdVtM 12129;
BA_ "SPN" SG_ 2566601982 MtGt5IvtPwLtdDTDSdPwMx 12132;
BA_ "SPN" SG_ 2566601982 MtGt5IvtPwLtdDTDSdPwM 12133;
BA_ "SPN" SG_ 2365275646 MtrGnrtr4InvrtrRfrn1Cntr 11938;
BA_ "SPN" SG_ 2365275646 MtrGnrtr4InvrtrRfrnTrq 11939;
BA_ "SPN" SG_ 2365275646 MtrGnrtr4InvrtrRfrnSpd 11940;
BA_ "SPN" SG_ 2365275646 MtrGnrtr4InvrtrRfrnPwr 11941;
BA_ "SPN" SG_ 2365275646 MtrGnrtr4InvrtrRfrn1Cr 11937;
BA_ "SPN" SG_ 2365275902 MtrGnrtr4InvrtrStts1Cntr 11943;
BA_ "SPN" SG_ 2365275902 MotorGenerator4Torque 11921;
BA_ "SPN" SG_ 2365275902 MotorGenerator4Speed 11919;
BA_ "SPN" SG_ 2365275902 MtrGnrtr4InvrtrStts1Cr 11942;
BA_ "SPN" SG_ 2365275902 MtrGnrtr4InvrtrDSdCrrnt 11944;
BA_ "SPN" SG_ 2365275902 MtrGnrtr4InvrtrDSdVltg 11922;
BA_ "SPN" SG_ 2365276158 MtrGnrtr4InvrtrRfrn2Cntr 11970;
BA_ "SPN" SG_ 2365276158 MtrGnrtr4InvrtrRfrnCrrnt 11971;
BA_ "SPN" SG_ 2365276158 MtrGnrtr4InvrtrRfrnVltg 11972;
BA_ "SPN" SG_ 2365276158 MtrGnrtr4InvrtrRfrn2Cr 11969;
BA_ "SPN" SG_ 2566603006 MtrGnrtr4InvrtrTmprtr1 11985;
BA_ "SPN" SG_ 2566603006 MtrGnrtr4InvrtrTmprtr2 11986;
BA_ "SPN" SG_ 2566603006 MtrGnrtr4InvrtrTmprtr3 11987;
BA_ "SPN" SG_ 2566603006 MtrGnrtr4InvrtrTmprtr4 11988;
BA_ "SPN" SG_ 2566603006 MtrGnrtr4InvrtrTmprtr5 20917;
BA_ "SPN" SG_ 2566603262 MotorGenerator4Temperature1 11920;
BA_ "SPN" SG_ 2566603262 MotorGenerator4Temperature2 11989;
BA_ "SPN" SG_ 2566603262 MotorGenerator4Temperature3 11990;
BA_ "SPN" SG_ 2566603262 MotorGenerator4Temperature4 11991;
BA_ "SPN" SG_ 2566603518 MtrGnrtr4InvrtrIsltnIntgrtCntr 12001;
BA_ "SPN" SG_ 2566603518 MtGt4IvtHVtBsAtvIstTstStts 12003;
BA_ "SPN" SG_ 2566603518 MtGt4IvtHVtBsPssvIstTstStts 12004;
BA_ "SPN" SG_ 2566603518 MtGt4IvtHVtBsAtvIstTstRsts 12005;
BA_ "SPN" SG_ 2566603518 MtGt4IvtHVtBsPssvIstTstRsts 12006;
BA_ "SPN" SG_ 2566603518 MtrGnrtr4InvrtrIsltnIntgrtCr 12000;
BA_ "SPN" SG_ 2566603518 MtGt4IvtDSdNtvTCsssGdVt 12002;
BA_ "SPN" SG_ 2566603774 MtGt4IvtPwLtdDTUddRs 12007;
BA_ "SPN" SG_ 2566603774 MtGt4IvtPwLtdDTMPwMx 12012;
BA_ "SPN" SG_ 2566603774 MtGt4IvtPwLtdDTMPwM 12013;
BA_ "SPN" SG_ 2566603774 MtrGnrtr4InvrtrPwrLmtdDTTrqMxmm 12016;
BA_ "SPN" SG_ 2566603774 MtrGnrtr4InvrtrPwrLmtdDTTrqMnmm 12017;
BA_ "SPN" SG_ 2566603774 MtrGnrtr4InvrtrPwrLmtdDTSpdMxmm 12018;
BA_ "SPN" SG_ 2566603774 MtrGnrtr4InvrtrPwrLmtdDTSpdMnmm 12019;
BA_ "SPN" SG_ 2566603774 MtGt4IvtPwLtdDTIvtTpt 12020;
BA_ "SPN" SG_ 2566603774 MtGt4IvtPwLtdDTMtTpt 12021;
BA_ "SPN" SG_ 2566603774 MtGt4IvtPwLtdDTFtCdt 13053;
BA_ "SPN" SG_ 2566603774 MtGt4IvtPwLtdDTAtvTqRtLt 13054;
BA_ "SPN" SG_ 2566603774 MtGt4IvtPwLtdDTAtvSpdRtLt 13055;
BA_ "SPN" SG_ 2566603774 MtGt4IvtTqLtdDTMCtsts 13056;
BA_ "SPN" SG_ 2566603774 MtGt4IvtPwLtdDTDSdCtMx 12008;
BA_ "SPN" SG_ 2566603774 MtGt4IvtPwLtdDTDSdCtM 12009;
BA_ "SPN" SG_ 2566603774 MtGt4IvtPwLtdDTDSdVtMx 12010;
BA_ "SPN" SG_ 2566603774 MtGt4IvtPwLtdDTDSdVtM 12011;
BA_ "SPN" SG_ 2566603774 MtGt4IvtPwLtdDTDSdPwMx 12014;
BA_ "SPN" SG_ 2566603774 MtGt4IvtPwLtdDTDSdPwM 12015;
BA_ "SPN" SG_ 2365277438 MtrGnrtr3InvrtrRfrn1Cntr 11820;
BA_ "SPN" SG_ 2365277438 MtrGnrtr3InvrtrRfrnTrq 11821;
BA_ "SPN" SG_ 2365277438 MtrGnrtr3InvrtrRfrnSpd 11822;
BA_ "SPN" SG_ 2365277438 MtrGnrtr3InvrtrRfrnPwr 11823;
BA_ "SPN" SG_ 2365277438 MtrGnrtr3InvrtrRfrn1Cr 11819;
BA_ "SPN" SG_ 2365277694 MtrGnrtr3InvrtrStts1Cntr 11825;
BA_ "SPN" SG_ 2365277694 MotorGenerator3Torque 11803;
BA_ "SPN" SG_ 2365277694 MotorGenerator3Speed 11801;
BA_ "SPN" SG_ 2365277694 MtrGnrtr3InvrtrStts1Cr 11824;
BA_ "SPN" SG_ 2365277694 MtrGnrtr3InvrtrDSdCrrnt 11826;
BA_ "SPN" SG_ 2365277694 MtrGnrtr3InvrtrDSdVltg 11804;
BA_ "SPN" SG_ 2365277950 MtrGnrtr3InvrtrRfrn2Cntr 11852;
BA_ "SPN" SG_ 2365277950 MtrGnrtr3InvrtrRfrnCrrnt 11853;
BA_ "SPN" SG_ 2365277950 MtrGnrtr3InvrtrRfrnVltg 11854;
BA_ "SPN" SG_ 2365277950 MtrGnrtr3InvrtrRfrn2Cr 11851;
BA_ "SPN" SG_ 2566604798 MtrGnrtr3InvrtrTmprtr1 11867;
BA_ "SPN" SG_ 2566604798 MtrGnrtr3InvrtrTmprtr2 11868;
BA_ "SPN" SG_ 2566604798 MtrGnrtr3InvrtrTmprtr3 11869;
BA_ "SPN" SG_ 2566604798 MtrGnrtr3InvrtrTmprtr4 11870;
BA_ "SPN" SG_ 2566604798 MtrGnrtr3InvrtrTmprtr5 20916;
BA_ "SPN" SG_ 2566605054 MotorGenerator3Temperature1 11802;
BA_ "SPN" SG_ 2566605054 MotorGenerator3Temperature2 11871;
BA_ "SPN" SG_ 2566605054 MotorGenerator3Temperature3 11872;
BA_ "SPN" SG_ 2566605054 MotorGenerator3Temperature4 11873;
BA_ "SPN" SG_ 2566605310 MtrGnrtr3InvrtrIsltnIntgrtCntr 11883;
BA_ "SPN" SG_ 2566605310 MtGt3IvtHVtBsAtvIstTstStts 11885;
BA_ "SPN" SG_ 2566605310 MtGt3IvtHVtBsPssvIstTstStts 11886;
BA_ "SPN" SG_ 2566605310 MtGt3IvtHVtBsAtvIstTstRsts 11887;
BA_ "SPN" SG_ 2566605310 MtGt3IvtHVtBsPssvIstTstRsts 11888;
BA_ "SPN" SG_ 2566605310 MtrGnrtr3InvrtrIsltnIntgrtCr 11882;
BA_ "SPN" SG_ 2566605310 MtGt3IvtDSdNtvTCsssGdVt 11884;
